VERSION "HNNBNNNYNNNNNNNNNNNNNNNNNNNNNNNNNNNNNNNNNN/4/%%%/4/'%**4NNN///"

NS_ :

BS_:

BU_: BAP_Tester CGS Gateway Gateway_PAG HUD Kombi Kombi_LB Kombi_PAG Waehlhebel_SB

BO_ 379 FCU_02: 8 Gateway
 SG_ FCU_02_CRC : 0|8@1+ (1,0) [0|255] ""  Vector__XXX
 SG_ FCU_02_BZ : 8|4@1+ (1,0) [0|15] ""  Vector__XXX
 SG_ FCU_Warn_H2_Konzentrat_Motorraum : 12|3@1+ (1.0,0.0) [0.0|7] ""  Kombi
 SG_ FCU_nicht_verfuegbar : 15|1@1+ (1.0,0.0) [0.0|1] ""  Vector__XXX
 SG_ FCU_Startstopp_Anforderung : 16|4@1+ (1.0,0.0) [0.0|15] ""  Vector__XXX
 SG_ FCU_HV_Anf : 20|2@1+ (1.0,0.0) [0.0|3] ""  Vector__XXX
 SG_ FCU_Klima_Eingr : 22|2@1+ (1.0,0.0) [0.0|3] ""  Vector__XXX
 SG_ FCU_IstModus : 24|5@1+ (1.0,0.0) [0.0|31] ""  Vector__XXX
 SG_ FCU_Status_Spgfreiheit : 29|2@1+ (1.0,0.0) [0.0|3] ""  Vector__XXX
 SG_ FCU_Fehler_Leistungsreduzierung : 31|1@1+ (1.0,0.0) [0.0|1] ""  Vector__XXX
 SG_ FCU_Fehler_Abschaltanforderung : 32|1@1+ (1.0,0.0) [0.0|1] ""  Vector__XXX
 SG_ FCU_Fehler_Notabschaltung : 33|1@1+ (1.0,0.0) [0.0|1] ""  Vector__XXX
 SG_ FCU_Fehler_Entladung_defekt : 34|2@1+ (1.0,0.0) [0.0|3] ""  Vector__XXX
 SG_ FCU_Fehler_Isofehler_I : 36|2@1+ (1.0,0.0) [0.0|3] ""  Vector__XXX
 SG_ FCU_Fehler_Isofehler_II : 38|2@1+ (1.0,0.0) [0.0|3] ""  Vector__XXX
 SG_ FCU_OBD_Lampe_Anf : 40|1@1+ (1.0,0.0) [0.0|1] ""  Vector__XXX
 SG_ FCU_Absperrventil_schliessen : 41|2@1+ (1.0,0.0) [0.0|3] ""  Vector__XXX
 SG_ FCU_TK_Betankung_Anforderung : 43|1@1+ (1.0,0.0) [0.0|1] ""  Vector__XXX
 SG_ FCU_MinAbs_Leistung : 44|10@1+ (0.1,-50) [-50.0|52.2] "Unit_KiloWatt"  Vector__XXX
 SG_ FCU_Ionenspuelung_aktiv : 54|2@1+ (1.0,0.0) [0.0|3] ""  Vector__XXX
 SG_ FCU_TK_Freigabe_Tankklappe : 56|4@1+ (1.0,0.0) [0.0|15] ""  Vector__XXX

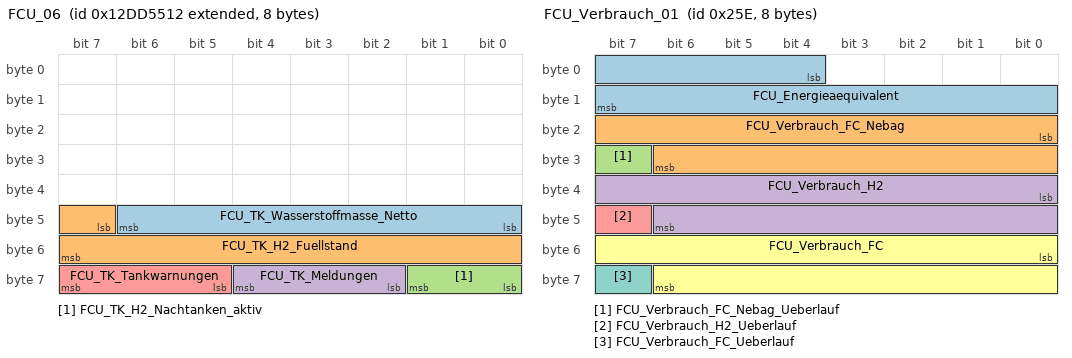
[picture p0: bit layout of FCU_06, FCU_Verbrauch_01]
BO_ 2463978770 FCU_06: 8 Gateway
 SG_ FCU_TK_Wasserstoffmasse_Netto : 40|7@1+ (0.1,0) [0.0|12.7] "Unit_KiloGram"  Kombi
 SG_ FCU_TK_H2_Fuellstand : 47|9@1+ (0.25,0) [0.00|127.25] "Unit_PerCent"  Kombi
 SG_ FCU_TK_H2_Nachtanken_aktiv : 56|2@1+ (1.0,0.0) [0.0|3] ""  Kombi
 SG_ FCU_TK_Meldungen : 58|3@1+ (1.0,0.0) [0.0|7] ""  Kombi
 SG_ FCU_TK_Tankwarnungen : 61|3@1+ (1.0,0.0) [0.0|7] ""  Kombi

BO_ 606 FCU_Verbrauch_01: 8 Gateway
 SG_ FCU_Energieaequivalent : 4|12@1+ (30,0) [0|122820] "Unit_WattSeconPerGram"  Vector__XXX
 SG_ FCU_Verbrauch_FC_Nebag : 16|15@1+ (1,0) [0|32767] "Unit_WattSecond"  Kombi
 SG_ FCU_Verbrauch_FC_Nebag_Ueberlauf : 31|1@1+ (1.0,0.0) [0.0|1] ""  Kombi
 SG_ FCU_Verbrauch_H2 : 32|15@1+ (0.1,0) [0.0|3276.7] "Unit_MilliGram"  Kombi
 SG_ FCU_Verbrauch_H2_Ueberlauf : 47|1@1+ (1.0,0.0) [0.0|1] ""  Kombi
 SG_ FCU_Verbrauch_FC : 48|15@1+ (1,0) [0|32767] "Unit_WattSecond"  Kombi
 SG_ FCU_Verbrauch_FC_Ueberlauf : 63|1@1+ (1.0,0.0) [0.0|1] ""  Kombi

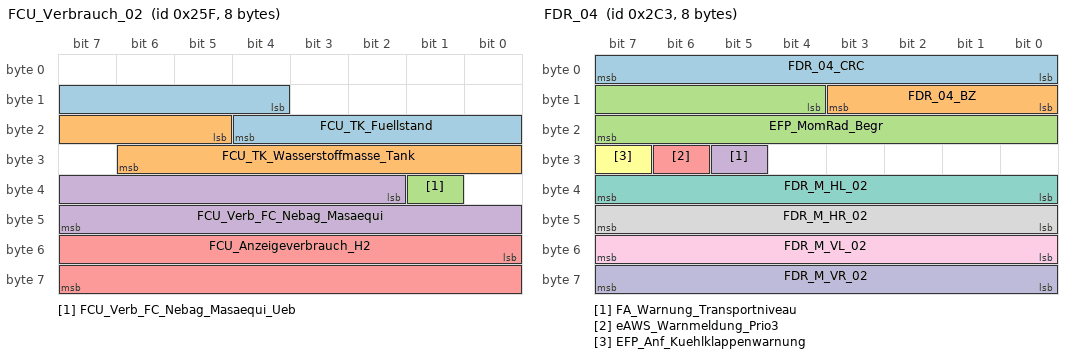
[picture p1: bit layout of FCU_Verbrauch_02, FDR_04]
BO_ 607 FCU_Verbrauch_02: 8 Gateway
 SG_ FCU_TK_Fuellstand : 12|9@1+ (0.25,0) [0.00|127.25] "Unit_PerCent"  Kombi
 SG_ FCU_TK_Wasserstoffmasse_Tank : 21|10@1+ (0.01,0) [0.00|10.21] "Unit_KiloGram"  Vector__XXX
 SG_ FCU_Verb_FC_Nebag_Masaequi_Ueb : 33|1@1+ (1.0,0.0) [0.0|1] ""  Kombi
 SG_ FCU_Verb_FC_Nebag_Masaequi : 34|14@1+ (0.1,0) [0.0|1638.3] "Unit_MilliGram"  Kombi
 SG_ FCU_Anzeigeverbrauch_H2 : 48|16@1+ (0.0005,0) [0.0000|32.7675] "Unit_KiloGramPerHour"  Kombi

BO_ 707 FDR_04: 8 Gateway
 SG_ FDR_04_CRC : 0|8@1+ (1,0) [0|255] ""  Kombi_LB,Kombi_PAG
 SG_ FDR_04_BZ : 8|4@1+ (1,0) [0|15] ""  Kombi_LB,Kombi_PAG
 SG_ EFP_MomRad_Begr : 12|12@1+ (3,0) [0|12279] "Unit_NewtoMeter"  Vector__XXX
 SG_ FA_Warnung_Transportniveau : 29|1@1+ (1.0,0.0) [0.0|1] ""  Kombi,Kombi_LB,Kombi_PAG
 SG_ eAWS_Warnmeldung_Prio3 : 30|1@1+ (1.0,0.0) [0.0|1] ""  Kombi_PAG
 SG_ EFP_Anf_Kuehlklappenwarnung : 31|1@1+ (1.0,0.0) [0.0|1] ""  Kombi,Kombi_LB,Kombi_PAG
 SG_ FDR_M_HL_02 : 32|8@1+ (1,-100) [-100|100] "Unit_PerCent"  Kombi,Kombi_LB,Kombi_PAG
 SG_ FDR_M_HR_02 : 40|8@1+ (1,-100) [-100|100] "Unit_PerCent"  Kombi,Kombi_LB,Kombi_PAG
 SG_ FDR_M_VL_02 : 48|8@1+ (1,-100) [-100|100] "Unit_PerCent"  Kombi,Kombi_LB,Kombi_PAG
 SG_ FDR_M_VR_02 : 56|8@1+ (1,-100) [-100|100] "Unit_PerCent"  Kombi,Kombi_LB,Kombi_PAG

BO_ 2589283684 FoD_01: 8 Gateway
 SG_ FoD_Transmission_Info : 60|2@1+ (1.0,0.0) [0.0|3] ""  Kombi,Kombi_LB
 SG_ FoD_Anz_Funktionsabschaltung : 62|2@1+ (1.0,0.0) [0.0|3] ""  Kombi,Kombi_LB

BO_ 2549875476 FoD_Kombi_Req: 8 Gateway
 SG_ FoD_Kombi_Req_Data : 0|64@1+ (1.0,0.0) [0.0|18446744073709551615] ""  Kombi,Kombi_LB,Kombi_PAG

BO_ 2550006548 FoD_Kombi_Resp: 8 Kombi
 SG_ FoD_Kombi_Resp_Data : 0|64@1+ (1.0,0.0) [0.0|18446744073709551615] ""  Gateway,Gateway_PAG

BO_ 2463978599 FZ_01: 8 Gateway
 SG_ MKE_Anpassung_FZ : 16|16@1+ (0.00012207,1) [1.00000000|8.99973538] "Unit_None"  Vector__XXX
 SG_ MKE_Fahrzeit : 38|10@1+ (1,0) [1|1023] "Unit_Minut"  Kombi,Kombi_LB,Kombi_PAG

BO_ 968 Getriebe_14: 8 Gateway
 SG_ GE_OBD_AbsperrVent : 12|4@1+ (1.0,0.0) [0.0|15] ""  Vector__XXX
 SG_ GE_amax_moeglich : 16|9@1+ (0.024,-2.016) [-2.016|10.224] "Unit_MeterPerSeconSquar"  Vector__XXX
 SG_ GE_Charisma_FahrPr : 25|4@1+ (1.0,0.0) [0.0|15] ""  Vector__XXX
 SG_ GE_Charisma_Status : 29|2@1+ (1.0,0.0) [0.0|3] ""  Vector__XXX
 SG_ GE_Freigabe_Verfallsinfo_WFS : 31|1@1+ (1.0,0.0) [0.0|1] ""  Vector__XXX
 SG_ GE_LaunchControl_LB : 32|4@1+ (1.0,0.0) [0.0|15] ""  Kombi_LB,Kombi_PAG
 SG_ GE_Status_PaddleNeutral : 37|2@1+ (1.0,0.0) [0.0|3] ""  Kombi,Kombi_PAG
 SG_ GE_Remotestart_Betrieb : 39|1@1+ (1.0,0.0) [0.0|1] ""  Vector__XXX
 SG_ Freilauf_Charisma_FahrPr : 40|4@1+ (1.0,0.0) [0.0|15] ""  Vector__XXX
 SG_ Freilauf_Charisma_Status : 44|2@1+ (1.0,0.0) [0.0|3] ""  Vector__XXX
 SG_ GE_Freigabe_Info_WFS : 46|1@1+ (1.0,0.0) [0.0|1] ""  Vector__XXX
 SG_ GE_Sperr_Info_WFS : 47|1@1+ (1.0,0.0) [0.0|1] ""  Vector__XXX
 SG_ GE_Zustand_Kuppltemp : 48|2@1+ (1.0,0.0) [0.0|3] ""  Vector__XXX
 SG_ GE_Codierung_MSG : 50|1@1+ (1.0,0.0) [0.0|1] ""  Vector__XXX
 SG_ GE_LaunchControl : 51|1@1+ (1.0,0.0) [0.0|1] ""  Vector__XXX
 SG_ GE_Heizwunsch : 52|2@1+ (1.0,0.0) [0.0|3] ""  Vector__XXX
 SG_ GE_OBD_Status : 54|1@1+ (1.0,0.0) [0.0|1] ""  Vector__XXX
 SG_ GE_LFR_Adaption : 55|1@1+ (1.0,0.0) [0.0|1] ""  Vector__XXX
 SG_ GE_Sumpftemperatur : 56|8@1+ (1,-58) [-58|196] "Unit_DegreCelsi"  Vector__XXX

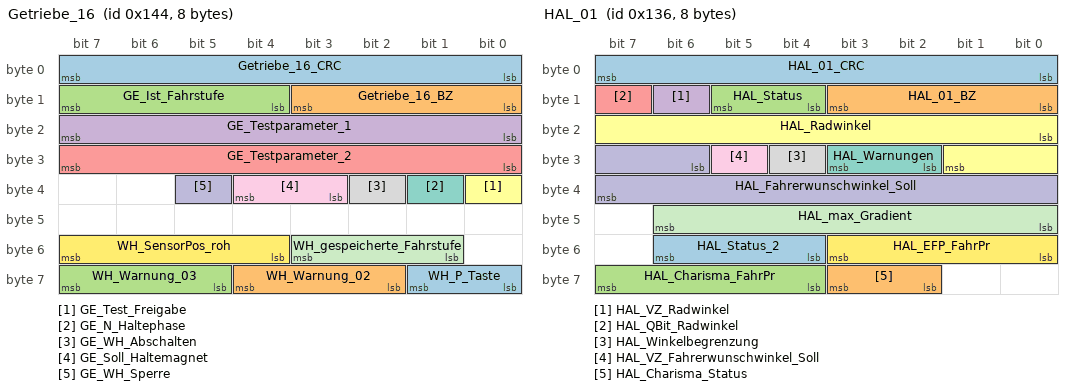
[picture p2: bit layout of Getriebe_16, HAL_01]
BO_ 324 Getriebe_16: 8 Gateway
 SG_ Getriebe_16_CRC : 0|8@1+ (1,0) [0|255] ""  CGS,Waehlhebel_SB
 SG_ Getriebe_16_BZ : 8|4@1+ (1,0) [0|15] ""  CGS,Waehlhebel_SB
 SG_ GE_Ist_Fahrstufe : 12|4@1+ (1.0,0.0) [0.0|15] ""  CGS,Waehlhebel_SB
 SG_ GE_Testparameter_1 : 16|8@1+ (1,0) [0|255] ""  CGS,Waehlhebel_SB
 SG_ GE_Testparameter_2 : 24|8@1+ (1,0) [0|255] ""  CGS,Waehlhebel_SB
 SG_ GE_Test_Freigabe : 32|1@1+ (1.0,0.0) [0.0|1] ""  CGS,Waehlhebel_SB
 SG_ GE_N_Haltephase : 33|1@1+ (1.0,0.0) [0.0|1] ""  CGS,Waehlhebel_SB
 SG_ GE_WH_Abschalten : 34|1@1+ (1.0,0.0) [0.0|1] ""  CGS,Waehlhebel_SB
 SG_ GE_Soll_Haltemagnet : 35|2@1+ (1.0,0.0) [0.0|3] ""  CGS,Waehlhebel_SB
 SG_ GE_WH_Sperre : 37|1@1+ (1.0,0.0) [0.0|1] ""  CGS,Waehlhebel_SB
 SG_ WH_gespeicherte_Fahrstufe : 49|3@1+ (1.0,0.0) [0.0|7] ""  Kombi_LB
 SG_ WH_SensorPos_roh : 52|4@1+ (1.0,0.0) [0.0|15] ""  Kombi_LB
 SG_ WH_P_Taste : 56|2@1+ (1.0,0.0) [0.0|3] ""  Kombi_LB
 SG_ WH_Warnung_02 : 58|3@1+ (1.0,0.0) [0.0|7] ""  Kombi_LB
 SG_ WH_Warnung_03 : 61|3@1+ (1.0,0.0) [0.0|7] ""  Kombi_LB

BO_ 299 GRA_ACC_01: 8 Gateway
 SG_ GRA_ACC_01_CRC : 0|8@1+ (1,0) [0|255] ""  Vector__XXX
 SG_ GRA_ACC_01_BZ : 8|4@1+ (1,0) [0|15] ""  Vector__XXX
 SG_ GRA_Hauptschalter : 12|1@1+ (1.0,0.0) [0.0|1] ""  Kombi,Kombi_LB,Kombi_PAG
 SG_ GRA_Abbrechen : 13|1@1+ (1.0,0.0) [0.0|1] ""  Vector__XXX
 SG_ GRA_Typ_Hauptschalter : 14|1@1+ (1.0,0.0) [0.0|1] ""  Vector__XXX
 SG_ GRA_Limiter : 15|1@1+ (1.0,0.0) [0.0|1] ""  Kombi,Kombi_LB,Kombi_PAG
 SG_ GRA_Tip_Setzen : 16|1@1+ (1.0,0.0) [0.0|1] ""  Vector__XXX
 SG_ GRA_Tip_Hoch : 17|1@1+ (1.0,0.0) [0.0|1] ""  Vector__XXX
 SG_ GRA_Tip_Runter : 18|1@1+ (1.0,0.0) [0.0|1] ""  Vector__XXX
 SG_ GRA_Tip_Wiederaufnahme : 19|1@1+ (1.0,0.0) [0.0|1] ""  Vector__XXX
 SG_ GRA_Verstellung_Zeitluecke : 20|2@1+ (1.0,0.0) [0.0|3] ""  Vector__XXX
 SG_ GRA_Codierung : 22|2@1+ (1.0,0.0) [0.0|3] ""  Vector__XXX
 SG_ GRA_Fehler : 24|1@1+ (1.0,0.0) [0.0|1] ""  Vector__XXX
 SG_ GRA_LIM_Taste_verfuegbar : 25|1@1+ (1.0,0.0) [0.0|1] ""  Vector__XXX
 SG_ GRA_Tip_Stufe_2 : 26|1@1+ (1.0,0.0) [0.0|1] ""  Vector__XXX
 SG_ GRA_Typ_Bedienteil : 27|3@1+ (1.0,0.0) [0.0|7] ""  Vector__XXX
 SG_ GRA_TravelAssist : 30|1@1+ (1.0,0.0) [0.0|1] ""  Vector__XXX
 SG_ GRA_reserveByte4 : 31|1@1+ (1.0,0.0) [0.0|1] ""  Vector__XXX
 SG_ GRA_reserveByte5 : 32|8@1+ (1.0,0.0) [0.0|255] ""  Vector__XXX
 SG_ GRA_reserveByte6 : 40|8@1+ (1.0,0.0) [0.0|255] ""  Vector__XXX
 SG_ GRA_reserveByte7 : 48|8@1+ (1.0,0.0) [0.0|255] ""  Vector__XXX
 SG_ GRA_reserveByte8 : 56|8@1+ (1.0,0.0) [0.0|255] ""  Vector__XXX

BO_ 310 HAL_01: 8 Gateway
 SG_ HAL_01_CRC : 0|8@1+ (1,0) [0|255] ""  Kombi,Kombi_LB,Kombi_PAG
 SG_ HAL_01_BZ : 8|4@1+ (1,0) [0|15] ""  Kombi,Kombi_LB,Kombi_PAG
 SG_ HAL_Status : 12|2@1+ (1.0,0.0) [0.0|3] ""  Vector__XXX
 SG_ HAL_VZ_Radwinkel : 14|1@1+ (1.0,0.0) [0.0|1] ""  Kombi_LB
 SG_ HAL_QBit_Radwinkel : 15|1@1+ (1.0,0.0) [0.0|1] ""  Vector__XXX
 SG_ HAL_Radwinkel : 16|10@1+ (0.01,0) [0.00|10.19] "Unit_DegreOfArc"  Kombi_LB
 SG_ HAL_Warnungen : 26|2@1+ (1.0,0.0) [0.0|3] ""  Kombi,Kombi_LB,Kombi_PAG
 SG_ HAL_Winkelbegrenzung : 28|1@1+ (1.0,0.0) [0.0|1] ""  Vector__XXX
 SG_ HAL_VZ_Fahrerwunschwinkel_Soll : 29|1@1+ (1.0,0.0) [0.0|1] ""  Vector__XXX
 SG_ HAL_Fahrerwunschwinkel_Soll : 30|10@1+ (0.01,0) [0.00|10.21] "Unit_DegreOfArc"  Vector__XXX
 SG_ HAL_max_Gradient : 40|7@1+ (0.1,0) [0.0|12.5] "Unit_DegreOfArcPerSecon"  Vector__XXX
 SG_ HAL_EFP_FahrPr : 48|4@1+ (1.0,0.0) [0.0|15] ""  Vector__XXX
 SG_ HAL_Status_2 : 52|3@1+ (1.0,0.0) [0.0|7] ""  Kombi_LB
 SG_ HAL_Charisma_Status : 58|2@1+ (1.0,0.0) [0.0|3] ""  Vector__XXX
 SG_ HAL_Charisma_FahrPr : 60|4@1+ (1.0,0.0) [0.0|15] ""  Vector__XXX

BO_ 1412 HSP_01: 6 Gateway
 SG_ HSP_01_CRC : 0|8@1+ (1,0) [0|255] ""  Kombi
 SG_ HSP_01_BZ : 8|4@1+ (1,0) [0|15] ""  Kombi
 SG_ HSP_Taster : 12|1@1+ (1.0,0.0) [0.0|1] ""  Vector__XXX
 SG_ HSP_Status_LED : 13|1@1+ (1.0,0.0) [0.0|1] ""  Vector__XXX
 SG_ HSP_Warnung_LED : 14|1@1+ (1.0,0.0) [0.0|1] ""  Kombi
 SG_ HSP_Warnung_Ton : 15|1@1+ (1.0,0.0) [0.0|1] ""  Vector__XXX
 SG_ HSP_Warnung_Text : 16|1@1+ (1.0,0.0) [0.0|1] ""  Kombi
 SG_ HSP_Endlage_eingefahren : 17|1@1+ (1.0,0.0) [0.0|1] ""  Vector__XXX
 SG_ HSP_Endlage_ausgefahren : 18|1@1+ (1.0,0.0) [0.0|1] ""  Vector__XXX
 SG_ HSP_Unterspannung : 19|1@1+ (1.0,0.0) [0.0|1] ""  Vector__XXX
 SG_ HSP_Ueberspannung : 20|1@1+ (1.0,0.0) [0.0|1] ""  Vector__XXX
 SG_ HSP_Lokalaktiv : 21|1@1+ (1.0,0.0) [0.0|1] ""  Vector__XXX
 SG_ HSP_ResponseError : 22|1@1+ (1.0,0.0) [0.0|1] ""  Vector__XXX
 SG_ HSP_ErrorGueltigkeit_1 : 23|1@1+ (1.0,0.0) [0.0|1] ""  Vector__XXX
 SG_ HSP_ErrorGueltigkeit_2 : 24|1@1+ (1.0,0.0) [0.0|1] ""  Vector__XXX
 SG_ HSP_def : 25|1@1+ (1.0,0.0) [0.0|1] ""  Vector__XXX
 SG_ HSP_Motor_def : 26|1@1+ (1.0,0.0) [0.0|1] ""  Vector__XXX
 SG_ HSP_Spoiler_Error : 27|1@1+ (1.0,0.0) [0.0|1] ""  Vector__XXX
 SG_ HSP_Taster_Error : 28|1@1+ (1.0,0.0) [0.0|1] ""  Vector__XXX
 SG_ HSP_LED_Error : 29|1@1+ (1.0,0.0) [0.0|1] ""  Vector__XXX
 SG_ HSP_Spielschutz : 30|1@1+ (1.0,0.0) [0.0|1] ""  Vector__XXX
 SG_ HSP_Motor_Temp_Text : 31|1@1+ (1.0,0.0) [0.0|1] ""  Vector__XXX
 SG_ HSP_Charisma_FahrPr : 32|4@1+ (1.0,0.0) [0.0|15] ""  Vector__XXX
 SG_ HSP_Charisma_Status : 36|2@1+ (1.0,0.0) [0.0|3] ""  Vector__XXX
 SG_ HSP_man_Betaet_nicht_zulaessig : 38|1@1+ (1.0,0.0) [0.0|1] ""  Vector__XXX
 SG_ HSP_Komponentensteuerung : 39|1@1+ (1.0,0.0) [0.0|1] ""  Vector__XXX
 SG_ HSP_BAP_Messages : 40|4@1+ (1.0,0.0) [0.0|15] ""  Vector__XXX

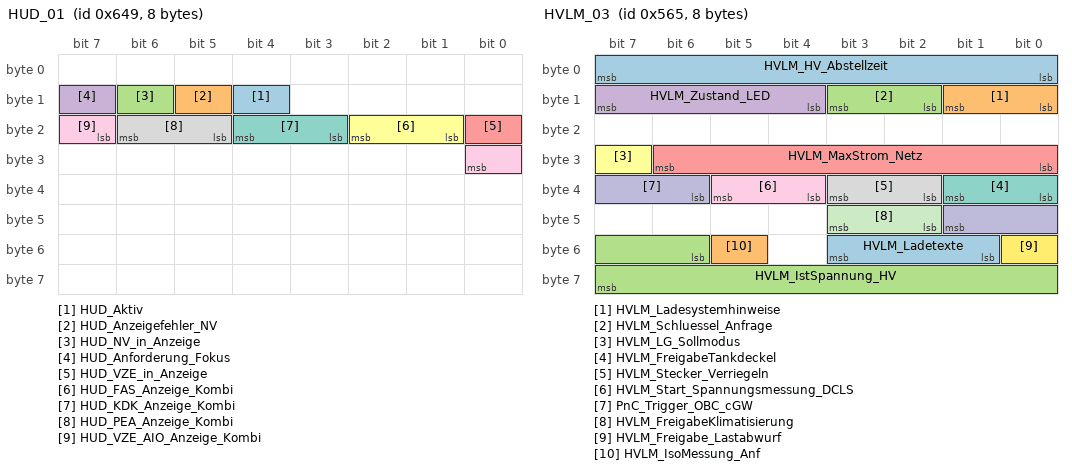
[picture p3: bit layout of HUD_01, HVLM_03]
BO_ 1609 HUD_01: 8 HUD
 SG_ HUD_Aktiv : 12|1@1+ (1.0,0.0) [0.0|1] ""  Kombi,Kombi_PAG
 SG_ HUD_Anzeigefehler_NV : 13|1@1+ (1.0,0.0) [0.0|1] ""  Vector__XXX
 SG_ HUD_NV_in_Anzeige : 14|1@1+ (1.0,0.0) [0.0|1] ""  Vector__XXX
 SG_ HUD_Anforderung_Fokus : 15|1@1+ (1.0,0.0) [0.0|1] ""  Kombi_PAG
 SG_ HUD_VZE_in_Anzeige : 16|1@1+ (1.0,0.0) [0.0|1] ""  Vector__XXX
 SG_ HUD_FAS_Anzeige_Kombi : 17|2@1+ (1.0,0.0) [0.0|3] ""  Vector__XXX
 SG_ HUD_KDK_Anzeige_Kombi : 19|2@1+ (1.0,0.0) [0.0|3] ""  Vector__XXX
 SG_ HUD_PEA_Anzeige_Kombi : 21|2@1+ (1.0,0.0) [0.0|3] ""  Vector__XXX
 SG_ HUD_VZE_AIO_Anzeige_Kombi : 23|2@1+ (1.0,0.0) [0.0|3] ""  Vector__XXX

BO_ 1283 HVK_01: 8 Gateway
 SG_ HVK_01_CRC : 0|8@1+ (1,0) [0|255] ""  Kombi,Kombi_LB,Kombi_PAG
 SG_ HVK_01_BZ : 8|4@1+ (1,0) [0|15] ""  Kombi,Kombi_LB,Kombi_PAG
 SG_ HVK_Istmodus_Anf : 12|1@1+ (1.0,0.0) [0.0|1] ""  Vector__XXX
 SG_ HVK_TN1_Sollmodus : 13|2@1+ (1.0,0.0) [0.0|3] ""  Vector__XXX
 SG_ HVK_MO_EmSollzustand : 16|8@1+ (1.0,0.0) [0.0|255] ""  Vector__XXX
 SG_ HVK_BMS_Sollmodus : 24|3@1+ (1.0,0.0) [0.0|7] ""  Vector__XXX
 SG_ HVK_DCDC_Sollmodus : 27|3@1+ (1.0,0.0) [0.0|7] ""  Vector__XXX
 SG_ HVK_EKK_Sollmodus : 30|3@1+ (1.0,0.0) [0.0|7] ""  Vector__XXX
 SG_ HVK_HVPTC_Sollmodus : 33|3@1+ (1.0,0.0) [0.0|7] ""  Vector__XXX
 SG_ HVK_HVLM_Sollmodus : 36|3@1+ (1.0,0.0) [0.0|7] ""  Vector__XXX
 SG_ HVK_HV_Netz_Warnungen : 39|2@1+ (1.0,0.0) [0.0|3] ""  Kombi,Kombi_LB,Kombi_PAG
 SG_ HV_Bordnetz_aktiv : 41|1@1+ (1.0,0.0) [0.0|1] ""  Vector__XXX
 SG_ HV_Bordnetz_Fehler : 42|1@1+ (1.0,0.0) [0.0|1] ""  Vector__XXX
 SG_ HVK_Gesamtst_Spgfreiheit : 43|2@1+ (1.0,0.0) [0.0|3] ""  Kombi,Kombi_LB,Kombi_PAG
 SG_ HVK_AktiveEntladung_Anf : 45|1@1+ (1.0,0.0) [0.0|1] ""  Vector__XXX
 SG_ HVK_Iso_Fehlerstatus : 48|1@1+ (1.0,0.0) [0.0|1] ""  Kombi,Kombi_PAG
 SG_ HVK_Iso_Messung_Start : 50|3@1+ (1.0,0.0) [0.0|7] ""  Vector__XXX
 SG_ HVK_AIAD_Sollmodus_2 M  : 53|1@1+ (1.0,0.0) [0.0|1] ""  Vector__XXX
 SG_ HVK_DCDC_EKK_Sollmodus : 62|2@1+ (1.0,0.0) [0.0|3] ""  Vector__XXX

BO_ 1381 HVLM_03: 8 Gateway
 SG_ HVLM_HV_Abstellzeit : 0|8@1+ (4,0) [0|1012] "Unit_Minut"  Vector__XXX
 SG_ HVLM_Ladesystemhinweise : 8|2@1+ (1.0,0.0) [0.0|3] ""  Kombi,Kombi_LB,Kombi_PAG
 SG_ HVLM_Schluessel_Anfrage : 10|2@1+ (1.0,0.0) [0.0|3] ""  Vector__XXX
 SG_ HVLM_Zustand_LED : 12|4@1+ (1.0,0.0) [0.0|15] ""  Kombi,Kombi_LB,Kombi_PAG
 SG_ HVLM_MaxStrom_Netz : 24|7@1+ (0.5,0) [0.0|62.5] "Unit_Amper"  Vector__XXX
 SG_ HVLM_LG_Sollmodus : 31|1@1+ (1.0,0.0) [0.0|1] ""  Vector__XXX
 SG_ HVLM_FreigabeTankdeckel : 32|2@1+ (1.0,0.0) [0.0|3] ""  Vector__XXX
 SG_ HVLM_Stecker_Verriegeln : 34|2@1+ (1.0,0.0) [0.0|3] ""  Vector__XXX
 SG_ HVLM_Start_Spannungsmessung_DCLS : 36|2@1+ (1.0,0.0) [0.0|3] ""  Vector__XXX
 SG_ PnC_Trigger_OBC_cGW : 38|4@1+ (1.0,0.0) [0.0|15] ""  Vector__XXX
 SG_ HVLM_FreigabeKlimatisierung : 42|2@1+ (1.0,0.0) [0.0|3] ""  Vector__XXX
 SG_ HVLM_Freigabe_Lastabwurf : 48|1@1+ (1.0,0.0) [0.0|1] ""  Vector__XXX
 SG_ HVLM_Ladetexte : 49|3@1+ (1.0,0.0) [0.0|7] ""  Kombi,Kombi_LB,Kombi_PAG
 SG_ HVLM_IsoMessung_Anf : 53|1@1+ (1.0,0.0) [0.0|1] ""  Vector__XXX
 SG_ HVLM_IstSpannung_HV : 54|10@1+ (1,0) [0|1021] "Unit_Volt"  Vector__XXX

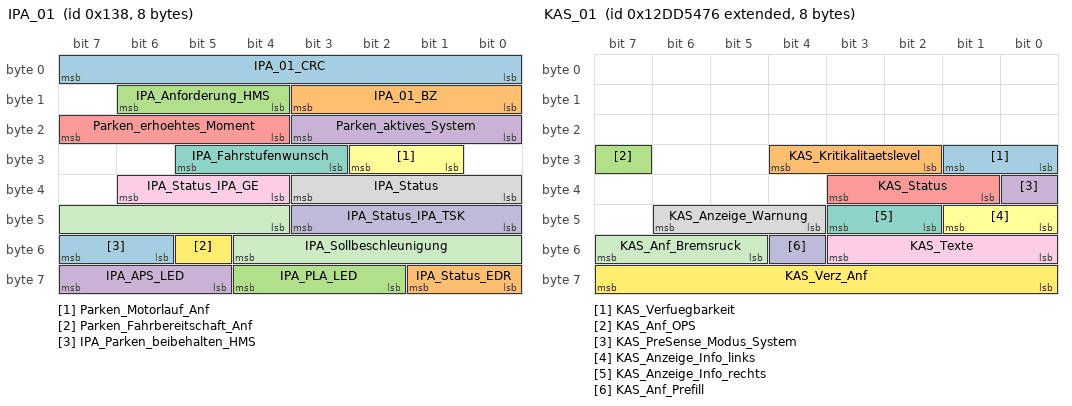
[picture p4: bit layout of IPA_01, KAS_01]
BO_ 312 IPA_01: 8 Gateway
 SG_ IPA_01_CRC : 0|8@1+ (1,0) [0|255] ""  Vector__XXX
 SG_ IPA_01_BZ : 8|4@1+ (1,0) [0|15] ""  Vector__XXX
 SG_ IPA_Anforderung_HMS : 12|3@1+ (1.0,0.0) [0.0|7] ""  Vector__XXX
 SG_ Parken_aktives_System : 16|4@1+ (1.0,0.0) [0.0|15] ""  Vector__XXX
 SG_ Parken_erhoehtes_Moment : 20|4@1+ (1.0,0.0) [0.0|15] ""  Vector__XXX
 SG_ Parken_Motorlauf_Anf : 25|2@1+ (1.0,0.0) [0.0|3] ""  Vector__XXX
 SG_ IPA_Fahrstufenwunsch : 27|3@1+ (1.0,0.0) [0.0|7] ""  Vector__XXX
 SG_ IPA_Status : 32|4@1+ (1.0,0.0) [0.0|15] ""  Vector__XXX
 SG_ IPA_Status_IPA_GE : 36|3@1+ (1.0,0.0) [0.0|7] ""  Vector__XXX
 SG_ IPA_Status_IPA_TSK : 40|4@1+ (1.0,0.0) [0.0|15] ""  Vector__XXX
 SG_ IPA_Sollbeschleunigung : 44|9@1+ (0.01,-4.11) [-4.10|1.00] "Unit_MeterPerSeconSquar"  Vector__XXX
 SG_ Parken_Fahrbereitschaft_Anf : 53|1@1+ (1.0,0.0) [0.0|1] ""  Kombi,Kombi_LB,Kombi_PAG
 SG_ IPA_Parken_beibehalten_HMS : 54|2@1+ (1.0,0.0) [0.0|3] ""  Vector__XXX
 SG_ IPA_Status_EDR : 56|2@1+ (1.0,0.0) [0.0|3] ""  Vector__XXX
 SG_ IPA_PLA_LED : 58|3@1+ (1.0,0.0) [0.0|7] ""  Vector__XXX
 SG_ IPA_APS_LED : 61|3@1+ (1.0,0.0) [0.0|7] ""  Vector__XXX

BO_ 1792 ISO_Funktionaler_Req_All: 8 Gateway
 SG_ ISO_ALL_01_Req_Data : 0|64@1+ (1.0,0.0) [0.0|18446744073709551615] ""  CGS,HUD,Kombi,Kombi_LB,Kombi_PAG,Waehlhebel_SB

BO_ 1819 ISO_HUD_Req: 8 Gateway
 SG_ ISO_HUD_Req_Data : 0|64@1+ (1.0,0.0) [0.0|18446744073709551615] ""  HUD

BO_ 1925 ISO_HUD_Resp: 8 HUD
 SG_ ISO_HUD_Resp_Data : 0|64@1+ (1.0,0.0) [0.0|18446744073709551615] ""  Gateway,Gateway_PAG

BO_ 1812 ISO_Kombi_Req: 8 Gateway
 SG_ ISO_Kombi_Req_Data : 0|64@1+ (1.0,0.0) [0.0|18446744073709551615] ""  Kombi,Kombi_LB,Kombi_PAG

BO_ 1918 ISO_Kombi_Resp: 8 Kombi
 SG_ ISO_Kombi_Resp_Data : 0|64@1+ (1.0,0.0) [0.0|18446744073709551615] ""  Gateway,Gateway_PAG

BO_ 1875 ISO_Waehlhebel_Req: 8 Gateway
 SG_ ISO_Waehlhebel_Req_Data : 0|64@1+ (1.0,0.0) [0.0|18446744073709551615] ""  CGS,Waehlhebel_SB

BO_ 1981 ISO_Waehlhebel_Resp: 8 CGS
 SG_ ISO_Waehlhebel_Resp_Data : 0|64@1+ (1.0,0.0) [0.0|18446744073709551615] ""  Gateway,Gateway_PAG

BO_ 2463978614 KAS_01: 8 Gateway
 SG_ KAS_Verfuegbarkeit : 24|2@1+ (1.0,0.0) [0.0|3] ""  Vector__XXX
 SG_ KAS_Kritikalitaetslevel : 26|3@1+ (1.0,0.0) [0.0|7] ""  Vector__XXX
 SG_ KAS_Anf_OPS : 31|1@1+ (1.0,0.0) [0.0|1] ""  Vector__XXX
 SG_ KAS_PreSense_Modus_System : 32|1@1+ (1.0,0.0) [0.0|1] ""  Vector__XXX
 SG_ KAS_Status : 33|3@1+ (1.0,0.0) [0.0|7] ""  HUD,Kombi,Kombi_LB,Kombi_PAG
 SG_ KAS_Anzeige_Info_links : 40|2@1+ (1.0,0.0) [0.0|3] ""  HUD,Kombi,Kombi_LB,Kombi_PAG
 SG_ KAS_Anzeige_Info_rechts : 42|2@1+ (1.0,0.0) [0.0|3] ""  HUD,Kombi,Kombi_LB,Kombi_PAG
 SG_ KAS_Anzeige_Warnung : 44|3@1+ (1.0,0.0) [0.0|7] ""  HUD,Kombi,Kombi_LB,Kombi_PAG
 SG_ KAS_Texte : 48|4@1+ (1.0,0.0) [0.0|15] ""  Kombi,Kombi_LB,Kombi_PAG
 SG_ KAS_Anf_Prefill : 52|1@1+ (1.0,0.0) [0.0|1] ""  Vector__XXX
 SG_ KAS_Anf_Bremsruck : 53|3@1+ (1.0,0.0) [0.0|7] ""  Vector__XXX
 SG_ KAS_Verz_Anf : 56|8@1+ (0.079,-19.987) [-19.987|0.000] "Unit_MeterPerSeconSquar"  Vector__XXX

BO_ 497 Kessy_11: 8 Gateway
 SG_ KY_IDG_in_Reichweite : 12|1@1+ (1.0,0.0) [0.0|1] ""  Vector__XXX
 SG_ KY_Auf_Taste : 13|1@1+ (1.0,0.0) [0.0|1] ""  Vector__XXX
 SG_ KY_HDF_Taste : 14|1@1+ (1.0,0.0) [0.0|1] ""  Vector__XXX
 SG_ KY_Panik_Taste : 15|1@1+ (1.0,0.0) [0.0|1] ""  Vector__XXX
 SG_ KY_Zu_Taste : 16|1@1+ (1.0,0.0) [0.0|1] ""  Vector__XXX
 SG_ KY_FT_Entriegelung_Autorisiert : 17|1@1+ (1.0,0.0) [0.0|1] ""  Vector__XXX
 SG_ KY_FT_Verriegelung_Autorisiert : 18|1@1+ (1.0,0.0) [0.0|1] ""  Vector__XXX
 SG_ KY_BT_Entriegelung_Autorisiert : 19|1@1+ (1.0,0.0) [0.0|1] ""  Vector__XXX
 SG_ KY_BT_Verriegelung_Autorisiert : 20|1@1+ (1.0,0.0) [0.0|1] ""  Vector__XXX
 SG_ KY_HFS_Entriegelung_Autorisiert : 21|1@1+ (1.0,0.0) [0.0|1] ""  Vector__XXX
 SG_ KY_HFS_Verriegelung_Autorisiert : 22|1@1+ (1.0,0.0) [0.0|1] ""  Vector__XXX
 SG_ KY_HBFS_Entriegelung_Autorisiert : 23|1@1+ (1.0,0.0) [0.0|1] ""  Vector__XXX
 SG_ KY_HBFS_Verriegelung_Autorisiert : 24|1@1+ (1.0,0.0) [0.0|1] ""  Vector__XXX
 SG_ KY_Front_Entr_Autorisiert : 25|1@1+ (1.0,0.0) [0.0|1] ""  Vector__XXX
 SG_ KY_Front_Verr_Autorisiert : 26|1@1+ (1.0,0.0) [0.0|1] ""  Vector__XXX
 SG_ KY_HD_Entriegelung_Autorisiert : 27|1@1+ (1.0,0.0) [0.0|1] ""  Vector__XXX
 SG_ KY_HD_Verriegelung_Autorisiert : 28|1@1+ (1.0,0.0) [0.0|1] ""  Vector__XXX
 SG_ KY_Bereich : 29|3@1+ (1.0,0.0) [0.0|7] ""  Vector__XXX
 SG_ KY_Position : 32|3@1+ (1.0,0.0) [0.0|7] ""  Vector__XXX
 SG_ KY_ZV_Signatur : 35|11@1+ (1,0) [0|2047] "Unit_None"  Vector__XXX
 SG_ Schluesselnr_Personalisierung : 46|4@1+ (1.0,0.0) [0.0|15] ""  Kombi,Kombi_LB,Kombi_PAG
 SG_ FFB_FDF_Taste : 50|1@1+ (1.0,0.0) [0.0|1] ""  Vector__XXX
 SG_ FFB_Joker_Taste : 51|1@1+ (1.0,0.0) [0.0|1] ""  Vector__XXX
 SG_ FFB_Park_Taste : 52|1@1+ (1.0,0.0) [0.0|1] ""  Vector__XXX
 SG_ FFB_Remotestart_Taste : 53|1@1+ (1.0,0.0) [0.0|1] ""  Vector__XXX
 SG_ FBS_Aktivierung_Pilot_Parken : 54|1@1+ (1.0,0.0) [0.0|1] ""  Vector__XXX
 SG_ KY_Schluessel_im_Fzg : 55|1@1+ (1.0,0.0) [0.0|1] ""  Vector__XXX
 SG_ KY_EasyClose_Abbruch : 56|1@1+ (1.0,0.0) [0.0|1] ""  Vector__XXX
 SG_ KY_EasyClose_Status : 57|3@1+ (1.0,0.0) [0.0|7] ""  Vector__XXX
 SG_ KY_HD_Auffahrt : 60|1@1+ (1.0,0.0) [0.0|1] ""  Vector__XXX
 SG_ KY_HD_Zufahrt : 61|1@1+ (1.0,0.0) [0.0|1] ""  Vector__XXX
 SG_ KY_LKL_1_Autorisierung : 62|1@1+ (1.0,0.0) [0.0|1] ""  Vector__XXX
 SG_ KY_LKL_2_Autorisierung : 63|1@1+ (1.0,0.0) [0.0|1] ""  Vector__XXX

BO_ 1424 Kessy_12: 8 Gateway
 SG_ FBS_Warn_Schluessel_Batt : 12|1@1+ (1.0,0.0) [0.0|1] ""  Kombi,Kombi_LB,Kombi_PAG
 SG_ KY_FFB_Frequenz : 13|2@1+ (1.0,0.0) [0.0|3] ""  Vector__XXX
 SG_ KY_HF_Aktiv : 15|1@1+ (1.0,0.0) [0.0|1] ""  Vector__XXX
 SG_ KY_LF_Aktiv : 16|1@1+ (1.0,0.0) [0.0|1] ""  Vector__XXX
 SG_ KY_KYL_Fahrer_Hinweise : 17|3@1+ (1.0,0.0) [0.0|7] ""  Kombi,Kombi_LB,Kombi_PAG
 SG_ KY_StartStopp_Info : 20|2@1+ (1.0,0.0) [0.0|3] ""  Vector__XXX
 SG_ KY_Keyless_Verbau : 22|1@1+ (1.0,0.0) [0.0|1] ""  Vector__XXX
 SG_ KY_Keyless_Go_Verbau : 23|1@1+ (1.0,0.0) [0.0|1] ""  Kombi,Kombi_LB,Kombi_PAG
 SG_ KY_Transponder_aktiv : 24|1@1+ (1.0,0.0) [0.0|1] ""  Vector__XXX
 SG_ KYL_Warn_kein_Schluessel : 25|1@1+ (1.0,0.0) [0.0|1] ""  Kombi,Kombi_LB,Kombi_PAG
 SG_ KYL_Warn_Kessy_defekt : 26|1@1+ (1.0,0.0) [0.0|1] ""  Kombi,Kombi_LB,Kombi_PAG
 SG_ KYL_Warn_Notzuendschloss : 27|1@1+ (1.0,0.0) [0.0|1] ""  Kombi,Kombi_LB,Kombi_PAG
 SG_ KY_Fzg_Verlassen_erkannt : 28|1@1+ (1.0,0.0) [0.0|1] ""  Vector__XXX
 SG_ KY_Fzg_Zugang_erkannt : 29|1@1+ (1.0,0.0) [0.0|1] ""  Vector__XXX
 SG_ KY_Indikator_Mehrere_Schluessel : 30|1@1+ (1.0,0.0) [0.0|1] ""  Vector__XXX
 SG_ KY_NFC_Fahrer_Hinweise : 41|3@1+ (1.0,0.0) [0.0|7] ""  Kombi,Kombi_LB,Kombi_PAG
 SG_ KST_Wegstrecke_Challenge : 44|20@1+ (1.0,0.0) [0.0|1048575] ""  Kombi,Kombi_LB,Kombi_PAG

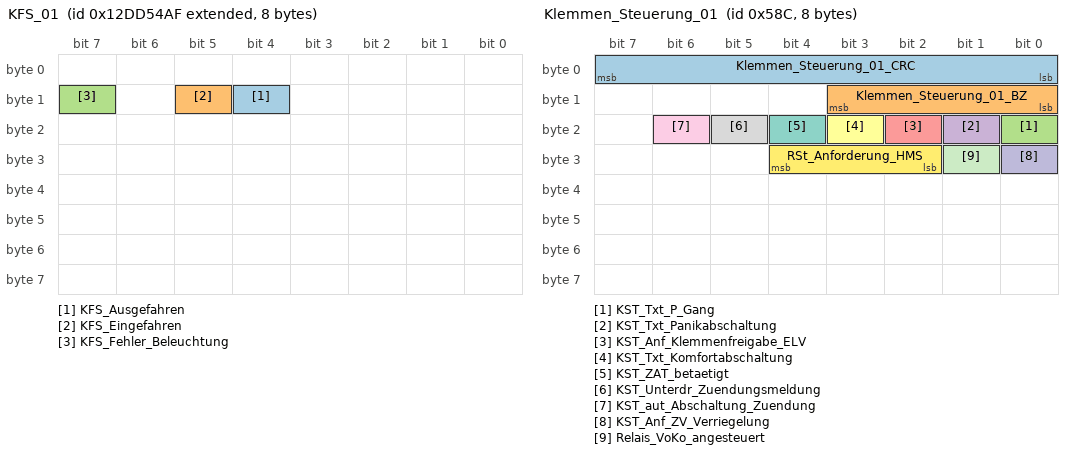
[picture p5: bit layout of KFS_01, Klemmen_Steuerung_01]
BO_ 2463978671 KFS_01: 8 Gateway
 SG_ KFS_Ausgefahren : 12|1@1+ (1.0,0.0) [0.0|1] ""  Vector__XXX
 SG_ KFS_Eingefahren : 13|1@1+ (1.0,0.0) [0.0|1] ""  Vector__XXX
 SG_ KFS_Fehler_Beleuchtung : 15|1@1+ (1.0,0.0) [0.0|1] ""  Vector__XXX

BO_ 960 Klemmen_Status_01: 4 Gateway
 SG_ Klemmen_Status_01_CRC : 0|8@1+ (1,0) [0|255] ""  CGS,Kombi,Kombi_LB,Kombi_PAG,Waehlhebel_SB
 SG_ Klemmen_Status_01_BZ : 8|4@1+ (1,0) [0|15] ""  CGS,Kombi,Kombi_LB,Kombi_PAG,Waehlhebel_SB
 SG_ RSt_Fahrerhinweise : 12|4@1+ (1.0,0.0) [0.0|15] ""  Kombi,Kombi_LB
 SG_ ZAS_Kl_S : 16|1@1+ (1.0,0.0) [0.0|1] ""  Kombi,Kombi_LB,Kombi_PAG
 SG_ ZAS_Kl_15 : 17|1@1+ (1.0,0.0) [0.0|1] ""  CGS,HUD,Kombi,Kombi_LB,Kombi_PAG,Waehlhebel_SB
 SG_ ZAS_Kl_X : 18|1@1+ (1.0,0.0) [0.0|1] ""  Vector__XXX
 SG_ ZAS_Kl_50_Startanforderung : 19|1@1+ (1.0,0.0) [0.0|1] ""  Kombi,Kombi_LB,Kombi_PAG
 SG_ BCM_Remotestart_Betrieb : 20|1@1+ (1.0,0.0) [0.0|1] ""  Vector__XXX
 SG_ ZAS_Kl_Infotainment : 21|1@1+ (1.0,0.0) [0.0|1] ""  Vector__XXX
 SG_ BCM_Remotestart_KL15_Anf : 22|1@1+ (1.0,0.0) [0.0|1] ""  Kombi,Kombi_PAG
 SG_ BCM_Remotestart_MO_Start : 23|1@1+ (1.0,0.0) [0.0|1] ""  Vector__XXX
 SG_ KST_Warn_P1_ZST_def : 24|1@1+ (1.0,0.0) [0.0|1] ""  Kombi,Kombi_LB,Kombi_PAG
 SG_ KST_Warn_P2_ZST_def : 25|1@1+ (1.0,0.0) [0.0|1] ""  Kombi,Kombi_LB,Kombi_PAG
 SG_ KST_Fahrerhinweis_1 : 26|1@1+ (1.0,0.0) [0.0|1] ""  Kombi,Kombi_LB,Kombi_PAG
 SG_ KST_Fahrerhinweis_2 : 27|1@1+ (1.0,0.0) [0.0|1] ""  Kombi,Kombi_LB,Kombi_PAG
 SG_ BCM_Ausparken_Betrieb : 28|1@1+ (1.0,0.0) [0.0|1] ""  Kombi,Kombi_LB,Kombi_PAG
 SG_ KST_Fahrerhinweis_4 : 29|1@1+ (1.0,0.0) [0.0|1] ""  Vector__XXX
 SG_ KST_Fahrerhinweis_5 : 30|1@1+ (1.0,0.0) [0.0|1] ""  Kombi,Kombi_LB,Kombi_PAG
 SG_ KST_Fahrerhinweis_6 : 31|1@1+ (1.0,0.0) [0.0|1] ""  Kombi,Kombi_LB,Kombi_PAG

BO_ 1420 Klemmen_Steuerung_01: 8 Gateway
 SG_ Klemmen_Steuerung_01_CRC : 0|8@1+ (1,0) [0|255] ""  Vector__XXX
 SG_ Klemmen_Steuerung_01_BZ : 8|4@1+ (1,0) [0|15] ""  Vector__XXX
 SG_ KST_Txt_P_Gang : 16|1@1+ (1.0,0.0) [0.0|1] ""  Kombi,Kombi_LB,Kombi_PAG
 SG_ KST_Txt_Panikabschaltung : 17|1@1+ (1.0,0.0) [0.0|1] ""  Kombi,Kombi_LB,Kombi_PAG
 SG_ KST_Anf_Klemmenfreigabe_ELV : 18|1@1+ (1.0,0.0) [0.0|1] ""  Vector__XXX
 SG_ KST_Txt_Komfortabschaltung : 19|1@1+ (1.0,0.0) [0.0|1] ""  Kombi,Kombi_LB,Kombi_PAG
 SG_ KST_ZAT_betaetigt : 20|1@1+ (1.0,0.0) [0.0|1] ""  Vector__XXX
 SG_ KST_Unterdr_Zuendungsmeldung : 21|1@1+ (1.0,0.0) [0.0|1] ""  Kombi,Kombi_LB,Kombi_PAG
 SG_ KST_aut_Abschaltung_Zuendung : 22|1@1+ (1.0,0.0) [0.0|1] ""  Kombi,Kombi_LB,Kombi_PAG
 SG_ KST_Anf_ZV_Verriegelung : 24|1@1+ (1.0,0.0) [0.0|1] ""  Vector__XXX
 SG_ Relais_VoKo_angesteuert : 25|1@1+ (1.0,0.0) [0.0|1] ""  Vector__XXX
 SG_ RSt_Anforderung_HMS : 26|3@1+ (1.0,0.0) [0.0|7] ""  Vector__XXX

BO_ 1646 Klima_03: 8 Gateway
 SG_ KL_STL_aktiv : 0|1@1+ (1.0,0.0) [0.0|1] ""  Kombi,Kombi_LB,Kombi_PAG
 SG_ KL_STH_aktiv : 1|1@1+ (1.0,0.0) [0.0|1] ""  Kombi,Kombi_PAG
 SG_ KL_Solarluefter_aktiv : 2|1@1+ (1.0,0.0) [0.0|1] ""  Vector__XXX
 SG_ KL_Umluft_Taste : 3|1@1+ (1.0,0.0) [0.0|1] ""  Kombi_PAG
 SG_ KL_Geblaese_Fond_Status : 4|4@1+ (1.0,0.0) [0.0|15] ""  Kombi,Kombi_LB,Kombi_PAG
 SG_ KL_STH_Ansteuerung : 8|2@1+ (1.0,0.0) [0.0|3] ""  Vector__XXX
 SG_ KL_STH_Betriebsdauer : 10|6@1+ (1,0) [0|60] "Unit_Minut"  Kombi,Kombi_PAG
 SG_ KL_Magnetventil : 16|1@1+ (1.0,0.0) [0.0|1] ""  Vector__XXX
 SG_ KL_WaPu : 17|1@1+ (1.0,0.0) [0.0|1] ""  Vector__XXX
 SG_ KL_Geblaese_Status : 18|4@1+ (1.0,0.0) [0.0|15] ""  Kombi,Kombi_LB,Kombi_PAG
 SG_ KL_Restwaerme_aktiv : 22|1@1+ (1.0,0.0) [0.0|1] ""  Vector__XXX
 SG_ KL_Kompressorkupplung : 23|1@1+ (1.0,0.0) [0.0|1] ""  Vector__XXX
 SG_ KL_BCmE_Livetip_Freigabe : 24|1@1+ (1.0,0.0) [0.0|1] ""  Vector__XXX
 SG_ KL_HYB_ASV_hinten_schliessen_Anf : 25|1@1+ (1.0,0.0) [0.0|1] ""  Vector__XXX
 SG_ KL_HYB_ASV_vorne_schliessen_Anf : 26|1@1+ (1.0,0.0) [0.0|1] ""  Vector__XXX
 SG_ KL_ErwVK_Zusatzrelais : 27|1@1+ (1.0,0.0) [0.0|1] ""  Vector__XXX
 SG_ KL_Status_Beduftung : 28|1@1+ (1.0,0.0) [0.0|1] ""  Vector__XXX
 SG_ KL_Status_Ionisator_Front : 29|1@1+ (1.0,0.0) [0.0|1] ""  Vector__XXX
 SG_ KL_STH_Timer_Status : 30|1@1+ (1.0,0.0) [0.0|1] ""  Kombi,Kombi_PAG
 SG_ KL_ErwVK_Anf : 31|1@1+ (1.0,0.0) [0.0|1] ""  Vector__XXX
 SG_ KL_Innen_Temp : 32|8@1+ (0.5,-50) [-50.0|76.0] "Unit_DegreCelsi"  CGS,Waehlhebel_SB
 SG_ KL_I_Geblaese_Fond : 40|8@1+ (0.25,0) [0.00|63.50] "Unit_Amper"  Vector__XXX
 SG_ KL_Anf_AussenspiegelHzg : 48|1@1+ (1.0,0.0) [0.0|1] ""  Vector__XXX
 SG_ KL_Heizkreisventilstellung : 49|2@1+ (1.0,0.0) [0.0|3] ""  Vector__XXX
 SG_ KL_FSH_Automatikbetrieb : 51|1@1+ (1.0,0.0) [0.0|1] ""  Kombi_PAG
 SG_ KL_SIH_LEH_Verteilung_VL : 52|3@1+ (1.0,0.0) [0.0|7] ""  Vector__XXX
 SG_ KL_SIH_LEL_Verteilung_VL : 55|3@1+ (1.0,0.0) [0.0|7] ""  Vector__XXX
 SG_ KL_SIH_LEH_Verteilung_VR : 58|3@1+ (1.0,0.0) [0.0|7] ""  Vector__XXX
 SG_ KL_SIH_LEL_Verteilung_VR : 61|3@1+ (1.0,0.0) [0.0|7] ""  Vector__XXX

BO_ 1663 Klima_05: 8 Gateway
 SG_ KL_Mod_Display_li : 0|4@1+ (1.0,0.0) [0.0|15] ""  Vector__XXX
 SG_ KL_Mod_Display_re : 4|4@1+ (1.0,0.0) [0.0|15] ""  Vector__XXX
 SG_ KL_Fondbed_vorne_aktiv : 8|1@1+ (1.0,0.0) [0.0|1] ""  Vector__XXX
 SG_ KL_Fond_re_reduziert : 9|1@1+ (1.0,0.0) [0.0|1] ""  Vector__XXX
 SG_ KL_Fond_li_reduziert : 10|1@1+ (1.0,0.0) [0.0|1] ""  Vector__XXX
 SG_ KL_Absperrventil_Fond : 11|1@1+ (1.0,0.0) [0.0|1] ""  Vector__XXX
 SG_ KL_SH_HL_Lastabschaltung : 12|2@1+ (1.0,0.0) [0.0|3] ""  Vector__XXX
 SG_ KL_SH_HR_Lastabschaltung : 14|2@1+ (1.0,0.0) [0.0|3] ""  Vector__XXX
 SG_ KL_Sollausblastemp_HL : 16|10@1+ (0.1,0) [0.0|102.2] "Unit_DegreCelsi"  Vector__XXX
 SG_ KL_Einheiten : 26|1@1+ (1.0,0.0) [0.0|1] ""  Vector__XXX
 SG_ KL_Kindersicherung : 27|1@1+ (1.0,0.0) [0.0|1] ""  Vector__XXX
 SG_ KL_Heizverbraucher_aus : 28|1@1+ (1.0,0.0) [0.0|1] ""  Vector__XXX
 SG_ KL_Heizverbraucher_Notaus : 29|1@1+ (1.0,0.0) [0.0|1] ""  Vector__XXX
 SG_ KL_Gebl_Verst_Abs_Modus : 30|1@1+ (1.0,0.0) [0.0|1] ""  Vector__XXX
 SG_ KL_Sollausblastemp_HR : 32|10@1+ (0.1,0) [0.0|102.2] "Unit_DegreCelsi"  Vector__XXX
 SG_ KL_ICO2_Sensor_defekt : 42|2@1+ (1.0,0.0) [0.0|3] ""  Kombi,Kombi_LB,Kombi_PAG
 SG_ KL_Umluft : 48|8@1+ (0.5,0) [0.0|100.0] "Unit_PerCent"  Vector__XXX
 SG_ KL_Geblaesespg_Fond : 56|8@1+ (0.1,0) [0.0|25.5] "Unit_Volt"  Vector__XXX

BO_TX_BU_ 707 :Gateway,Gateway_PAG;
BO_TX_BU_ 2589283684 :Gateway,Gateway_PAG;
BO_TX_BU_ 2549875476 :Gateway,Gateway_PAG;
BO_TX_BU_ 2550006548 :Kombi,Kombi_LB,Kombi_PAG;
BO_TX_BU_ 2463978599 :Gateway,Gateway_PAG;
BO_TX_BU_ 968 :Gateway,Gateway_PAG;
BO_TX_BU_ 324 :Gateway,Gateway_PAG;
BO_TX_BU_ 299 :Gateway,Gateway_PAG;
BO_TX_BU_ 310 :Gateway,Gateway_PAG;
BO_TX_BU_ 1412 :Gateway,Gateway_PAG;
BO_TX_BU_ 1283 :Gateway,Gateway_PAG;
BO_TX_BU_ 1381 :Gateway,Gateway_PAG;
BO_TX_BU_ 312 :Gateway,Gateway_PAG;
BO_TX_BU_ 1792 :Gateway,Gateway_PAG;
BO_TX_BU_ 1819 :Gateway,Gateway_PAG;
BO_TX_BU_ 1812 :Gateway,Gateway_PAG;
BO_TX_BU_ 1918 :Kombi,Kombi_LB,Kombi_PAG;
BO_TX_BU_ 1875 :Gateway,Gateway_PAG;
BO_TX_BU_ 1981 :CGS,Waehlhebel_SB;
BO_TX_BU_ 2463978614 :Gateway,Gateway_PAG;
BO_TX_BU_ 497 :Gateway,Gateway_PAG;
BO_TX_BU_ 1424 :Gateway,Gateway_PAG;
BO_TX_BU_ 2463978671 :Gateway,Gateway_PAG;
BO_TX_BU_ 960 :Gateway,Gateway_PAG;
BO_TX_BU_ 1420 :Gateway,Gateway_PAG;
BO_TX_BU_ 1646 :Gateway,Gateway_PAG;
BO_TX_BU_ 1663 :Gateway,Gateway_PAG;
CM_ BO_ 1609 "MLB_Evo ohne KD-Bit";
CM_ BO_ 960 "MQB";
CM_ BO_ 1646 "ab MQB 7.3";
CM_ BO_ 1663 "Klima";

CM_ SG_ 379 FCU_Absperrventil_schliessen "Abtrennung HT-Kreis von Heizkreis";
CM_ SG_ 379 FCU_Fehler_Abschaltanforderung "FCU-System-Stoppanforderung der FCU aufgrund Fehler in der FCU (nur mit Fehlerspeichereintrag)";
CM_ SG_ 379 FCU_Fehler_Entladung_defekt "Aktueller Fehlerstatus der Entladung";
CM_ SG_ 379 FCU_Fehler_Isofehler_I "Aktueller Isofehlerstatus des Brennstoffzellensystems";
CM_ SG_ 379 FCU_Fehler_Isofehler_II "Aktueller Isofehlerstatus des Brennstoffzellensystems";
CM_ SG_ 379 FCU_Fehler_Leistungsreduzierung "Leistungsreduzierung der FCU aufgrund Fehler aktiv (nur mit Fehlerspeichereintrag), z.B. LimpHome";
CM_ SG_ 379 FCU_Fehler_Notabschaltung "FCU-System-Notabschaltung  aufgrund Fehler in der FCU (nur mit Fehlerspeichereintrag)";
CM_ SG_ 379 FCU_HV_Anf "Anforderung 'HV-Netz aktivieren'";
CM_ SG_ 379 FCU_Ionenspuelung_aktiv "Spülung aller Kühlkreisläufe der Brennstoffzelle
0= keine Spülung
1= Spülung zwingend notwendig
2= Spülung Anforderung";
CM_ SG_ 379 FCU_IstModus "IST-Modus des FCU-Systems";
CM_ SG_ 379 FCU_Klima_Eingr "beschränkt Kompressorleistung / Kompressorabwurf";
CM_ SG_ 379 FCU_MinAbs_Leistung "Absolute minimale Leistung des BZ-Systems

Leistungsabgabe BZ-System - positiv
Leistungsaufnahme BZ-System - negativ";
CM_ SG_ 379 FCU_nicht_verfuegbar "FCU-System-Verfuegbarkeitsstatus";
CM_ SG_ 379 FCU_OBD_Lampe_Anf "Anforderung MIL (MalfunctionIndicationLamp) von FCU";
CM_ SG_ 379 FCU_Startstopp_Anforderung "Start/Stop-Anforderungen der FCU, z.B. Stopverbot, -freigabe, -anforderung, -wunsch und Startwunsch";
CM_ SG_ 379 FCU_Status_Spgfreiheit "0=Init
1=HV-Komponente spannungsfrei (U_Zwkr < 20V)
2=HV-Komponente nicht spannungsfrei (U_Zwkr >/= 25V, Hysterese)
3=Fehler (z.B. Fehler in der Sensorik)";
CM_ SG_ 379 FCU_TK_Betankung_Anforderung "Notwendig für Tankvorgang, um Weiterfahrt zu unterbinden.

Triggert:
- BZ zum Herunterfahren bzw. Sleep-Mode
- EPB aktivieren
- Fahrbereitschaft deaktivieren";
CM_ SG_ 379 FCU_TK_Freigabe_Tankklappe "Freigabesignal für Entriegelung Tankklappe.";
CM_ SG_ 379 FCU_Warn_H2_Konzentrat_Motorraum "Warnung H2-Konzentration im Motorraum

Ansteuerung Kühlerlüfter für Motorraumspülung & ggf. Deaktivierung Innenraumgebläse. Ggf. müssen Akustikgrenzen aufgehoben werden";

CM_ SG_ 2463978770 FCU_TK_H2_Fuellstand "Wasserstoff-Füllstand für Anzeige im Kombi";
CM_ SG_ 2463978770 FCU_TK_H2_Nachtanken_aktiv "Wird bei einer H2 Betankung gesetzt, und bleibt gesetzt bis v>5km/h für >5s";
CM_ SG_ 2463978770 FCU_TK_Meldungen "Anzeige von Infos und Fehler im  Kombi";
CM_ SG_ 2463978770 FCU_TK_Tankwarnungen "Warnt den Fahrer vor geringem Füllstand (analog: Reserve 1; Reserve 2)";
CM_ SG_ 2463978770 FCU_TK_Wasserstoffmasse_Netto "Wasserstoffmasse Netto ( Behälterschutz und Worst-Case-Reserve berücksichtigt)";

CM_ SG_ 606 FCU_Energieaequivalent "BZ-System-Wirkungsgrad korrigierter Heizwert";
CM_ SG_ 606 FCU_Verbrauch_FC "Überlaufender Zähler von der BZ abgegebene elektrische Arbeit";
CM_ SG_ 606 FCU_Verbrauch_FC_Nebag "Überlaufender Zähler von den BZ Nebenaggregaten aufgenommene Arbeit";
CM_ SG_ 606 FCU_Verbrauch_FC_Nebag_Ueberlauf "Erster Überlauf Verbrauchssignal";
CM_ SG_ 606 FCU_Verbrauch_FC_Ueberlauf "Erster Überlauf Verbrauchssignal";
CM_ SG_ 606 FCU_Verbrauch_H2 "Überlaufender Zähler/Eingebrachte H2 Masse";
CM_ SG_ 606 FCU_Verbrauch_H2_Ueberlauf "Erster Überlauf Verbrauchssignal";

CM_ SG_ 607 FCU_Anzeigeverbrauch_H2 "Momentanverbrauch H2";
CM_ SG_ 607 FCU_TK_Fuellstand "Aktueller nutzbarer Tankfüllstand wird in FCU berechnet.";
CM_ SG_ 607 FCU_TK_Wasserstoffmasse_Tank "Nutzbare Gewichtsmasse des sich in den Tanks befindenden Wasserstoffs.";
CM_ SG_ 607 FCU_Verb_FC_Nebag_Masaequi "Überlaufender Zähler/Eingebrachte H2 Masse für Nebenaggregate";
CM_ SG_ 607 FCU_Verb_FC_Nebag_Masaequi_Ueb "Erster Überlauf Verbrauchssignal";

CM_ SG_ 707 eAWS_Warnmeldung_Prio3 "Signal zur Ansteuerung der Prio3 Warnmeldung für das eAWS im Kombi";
CM_ SG_ 707 EFP_Anf_Kuehlklappenwarnung "Signal wird zur Ansteuerung einer Kühlklappenwarnung im Kombiinstrument genutzt";
CM_ SG_ 707 EFP_MomRad_Begr "Begrenzung des beschleunigt wirkenden Antriebstrangsollmomentenanteils auf Summenradebene 
Für MLBevo: Faktor in TS_Faktor_Radmomente beachten!";
CM_ SG_ 707 FA_Warnung_Transportniveau "Signal zur Ansteuerung einer Warnmeldung, wenn beim Transportmodus das Zielniveau nicht angefahren wird";
CM_ SG_ 707 FDR_04_BZ "4bit Botschaftszähler, wird mit jeder Sendebotschaft inkrementiert";
CM_ SG_ 707 FDR_04_CRC "Für MLB:
Berechnung siehe Lastenheft 'Kommunikationsabsicherung für FlexRay und CAN'
Ab MQB und MLBevo:
Berechnung siehe Lastenheft 'End-to-End Kommunikationsabsicherung'

Endwerte siehe Begleitdokument 'S-PDU Kennungsfolgen'";
CM_ SG_ 707 FDR_M_HL_02 "Momentenanzeige für MMI.";
CM_ SG_ 707 FDR_M_HR_02 "Momentenanzeige für MMI.";
CM_ SG_ 707 FDR_M_VL_02 "Momentenanzeige für MMI.";
CM_ SG_ 707 FDR_M_VR_02 "Momentenanzeige für MMI.";

CM_ SG_ 2589283684 FoD_Anz_Funktionsabschaltung "Signal triggert Aufschaltung eines Popups, um dem Fahrer die Abschaltung einer Funktion zu melden.";
CM_ SG_ 2589283684 FoD_Transmission_Info "Mit dem Signal zeigt der FoD-Master allen FoD-Slaves den Beginn und das Ende eines Freischaltuebertragungszykluses (FS-ID-Zyklus) an.";

CM_ SG_ 2549875476 FoD_Kombi_Req_Data "Function on demand request an Kombiinstrument";

CM_ SG_ 2550006548 FoD_Kombi_Resp_Data "Function on demand response vom Kombiinstrument";

CM_ SG_ 2463978599 MKE_Anpassung_FZ "Informationen der MKE zur Anpassung der Status der weiteren Fahrerzustände
Adaptionswert der Müdigkeiterkennung";
CM_ SG_ 2463978599 MKE_Fahrzeit "Fahrzeit in Minuten für die Anzeige im Kombi bei einer Meldung";

CM_ SG_ 968 Freilauf_Charisma_FahrPr "MLBevo: Aktuelles Fahrprogramm des Charisma-Teilnehmers (siehe Systemlastenheft Drive Select)
MQB: Istwert der Kennlinie (siehe Systemlastenheft MQB FPA)";
CM_ SG_ 968 Freilauf_Charisma_Status "Charisma Systemstatus des Charisma-Teilnehmers

Wert 0x3 ist nur für Fahrzeuge ab MQB relevant";
CM_ SG_ 968 GE_amax_moeglich "AL/DL: maximal mögliche Beschleunigung unter Berücksichtigung aller möglichen Gänge.

Eine Reduzierung des maximalen Motormoments durch Efficiency wird in dem Signal berücksichtigt.

VL: maximal mögliche Beschleunigung bei Nenndrehzahl (Efficency wird";
CM_ SG_ 968 GE_Charisma_FahrPr "MLBevo: Aktuelles Fahrprogramm des Charisma-Teilnehmers (siehe Systemlastenheft Drive Select)
MQB: Istwert der Kennlinie (siehe Systemlastenheft MQB FPA)";
CM_ SG_ 968 GE_Charisma_Status "Charisma Systemstatus des Charisma-Teilnehmers

Wert 0x3 ist nur für Fahrzeuge ab MQB relevant";
CM_ SG_ 968 GE_Codierung_MSG "Statusausgabe der Diagnose für Falschverbau. Plausibilisierung der empfangenen Motor- und Getriebevariante mit der erwarteten Motor- und Getriebevarianten.";
CM_ SG_ 968 GE_Freigabe_Info_WFS "WFS-Freigabeinformation";
CM_ SG_ 968 GE_Freigabe_Verfallsinfo_WFS "WFS";
CM_ SG_ 968 GE_LaunchControl "Während einer LaunchControl-Anfahrt sendet das Getriebesteuergerät das Bit LaunchControl aktiv.
Die Bremse wertet dieses Bit aus, um während einer solchen Anfahrt die Regelgrenzen der Schlupfregelung zu erweitern.
Im Motor Nutzung zur Verbesserung des A";
CM_ SG_ 968 GE_LaunchControl_LB "LB launch control status";
CM_ SG_ 968 GE_LFR_Adaption "Qualifiziert das ausgegeben Motorbelastungsmoment (durch GE_Vorsteuermoment) für die Verwendung zur LFR (Leerlauffüllungsregelung) im Moto";
CM_ SG_ 968 GE_OBD_AbsperrVent "Das Getriebesteuergerät führt eine elektrische Diagnose des von ihm angesteuerten Absperrventils für den Öl-Wasser-Wärmetauscher durch und übermittelt das Ergebnis an das MSG (Standard-4Bit-OBD-Status, nicht alle Zustände müssen genutzt werden; so sind z.";
CM_ SG_ 968 GE_OBD_Status "Dieses Bit steuert die MIL-Lampe an (Motorsteuergerät reicht diese Info an Kombi weiter).";
CM_ SG_ 968 GE_Remotestart_Betrieb "Das GSG ist für den Remotestart-Betrieb bereit. Nach Empfang der Motorstartanforderung für RSt-Betrieb durch BCM wird der Fahrzeugmotor gestartet und solange der Motor läuft, bleibt dieses Bit aktiv. Dieses Signal ist nur zur Verwendung durch das BCM zur ";
CM_ SG_ 968 GE_Sperr_Info_WFS "WFS-Sperrinformation";
CM_ SG_ 968 GE_Status_PaddleNeutral "Status Ablauf der Paddle Neutral Funktion";
CM_ SG_ 968 GE_Sumpftemperatur "Getriebesumpftemperatur wird über den Temperatursensor auf der Getriebeplatine ermittelt. Die absolute Sumpftemperatur wird vom Motor empfangen, um entsprechende Kühlleistung für das Getriebe einzustellen.";
CM_ SG_ 968 GE_Zustand_Kuppltemp "Dieses Signal gibt den Temperaturzustand der Kupplung im DQ-Getriebe (z. Zt. DQ2x0, DQ500) an das ACC-System.";

CM_ SG_ 324 GE_Ist_Fahrstufe "Im Getriebe eingelegte Fahrstufe zur Anzeige am Bedienelement. Ist die Fahrstufe ungültig, wird keine Fahrstufe angezeigt.";
CM_ SG_ 324 GE_N_Haltephase "Das Getriebe signalisiert dem Waehlhebel, dass die N-Haltephase aktiv ist. 
Danach kann der Waehlhebel ein Abschalten des I-CAN ermöglichen";
CM_ SG_ 324 GE_Soll_Haltemagnet "Sollposition des Parksperren-Haltemagneten für die Ansteuerung durch den Waehlhebel";
CM_ SG_ 324 GE_Test_Freigabe "Das Bit wird auf 1 gesetzt, wenn gültige Testparameter gesendet werden.";
CM_ SG_ 324 GE_Testparameter_1 "Testparameter 1 (Frage) zur Überwachung des Wählhebel-SG";
CM_ SG_ 324 GE_Testparameter_2 "Testparameter 2 (Frage) zur Überwachung des Wählhebel-SG";
CM_ SG_ 324 GE_WH_Abschalten "Mit diesem Bit kann das Getriebe das Wählhebel-SG reseten bzw. dauerhaft deaktivieren. Der Wählhebel geht dann in einen Standby-Modus. ";
CM_ SG_ 324 GE_WH_Sperre "Bit wird auf 1 gesetzt, wenn getriebeseitigen Bedingungen erfüllt sind, um Wählhebel zu bewegen.";
CM_ SG_ 324 Getriebe_16_CRC "Für MLB:
'Berechnung siehe Lastenheft 'Kommunikationsabsicherung für FlexRay und CAN''

Ab MQB und MLBevo:
'Berechnung siehe Lastenheft 'End-to-End Kommunikationsabsicherung''

Endwerte siehe Begleitdokument 'S-PDU Kennungsfolgen'";
CM_ SG_ 324 WH_gespeicherte_Fahrstufe "Kurzzeit-Fahrstufenspeicherung in Abhängigkeit von GE_Ist_Fahrstufe.";
CM_ SG_ 324 WH_P_Taste "Das Signal zeigt den Status der P-Taste an.";
CM_ SG_ 324 WH_SensorPos_roh "Zustand Wählhebelposition. Wird das Signal WH_Variante nicht bedient, ist die Signalcodierung 
wie im MQB zu verwenden.

MQB:
0=Init
1=Position_1
2=Position_2
3=Position_3
4=nicht_betaetigt
5=Position_D
6=Position_N
7=Position_R
8=Position_P
";
CM_ SG_ 324 WH_Warnung_02 "Warnmeldungen vom Waehlhebel an das Kombi";
CM_ SG_ 324 WH_Warnung_03 "Warnungen des CGS im Lambo Urus";

CM_ SG_ 299 GRA_Abbrechen "GRA : aus mit speichern
ACC : Soft aus";
CM_ SG_ 299 GRA_ACC_01_BZ "4bit Botschaftszaehler, wird mit jeder Sendebotschaft inkrementiert
Botschaft asynchron geroutet. Zählerwert kann springen.";
CM_ SG_ 299 GRA_ACC_01_CRC "Für MLB:
'Berechnung siehe Lastenheft 'Kommunikationsabsicherung für FlexRay und CAN''

Ab MQB und MLBevo:
'Berechnung siehe Lastenheft 'End-to-End Kommunikationsabsicherung''

Endwerte siehe Begleitdokument 'S-PDU Kennungsfolgen'";
CM_ SG_ 299 GRA_Codierung "Das Signal zeigt an, ob das Sende-SG (SMLS/MFL) auf GRA- oder ACC-Bedienteil codiert ist:
0: kein GRA- oder ACC Bedienteil
1: GRA-Bedienteil
2: ACC-Bedienteil
3: Limiter_Only-Bedienteil";
CM_ SG_ 299 GRA_Fehler "Das Signal zeigt an, dass das Sende-SG (SMLS/MFG) einen Defekt des GRA-Bedienteils erkannt hat und hierzu ein FSPE abgelegt wurde.";
CM_ SG_ 299 GRA_Hauptschalter "Stellung des GRA/ACC-Hauptschalters: 
Bei gerastetem Hauptschalter:
0: Hauptschalter aus
1: Hauptschalter ein
Bei getastetem Hauptschalter:
0: Taster nicht betätigt
1: Taster betätigt";
CM_ SG_ 299 GRA_LIM_Taste_verfuegbar "Das Signal zeigt an, ob eine Limiter-Umschalttaste am jeweiligen GRA/ACC-Bedienelement vorhanden ist.";
CM_ SG_ 299 GRA_Limiter "Stellung des Limiter-Tasters";
CM_ SG_ 299 GRA_reserveByte4 "Zweck: Befüllen der reservierten Bitpositionen mit 0 (wg. LIN-Teilnehmer MFL)";
CM_ SG_ 299 GRA_reserveByte5 "Zweck: Befüllen der reservierten Bitpositionen mit 0 (wg. LIN-Teilnehmer MFL)";
CM_ SG_ 299 GRA_reserveByte6 "Zweck: Befüllen der reservierten Bitpositionen mit 0 (wg. LIN-Teilnehmer MFL)";
CM_ SG_ 299 GRA_reserveByte7 "Zweck: Befüllen der reservierten Bitpositionen mit 0 (wg. LIN-Teilnehmer MFL)";
CM_ SG_ 299 GRA_reserveByte8 "Zweck: Befüllen der reservierten Bitpositionen mit 0 (wg. LIN-Teilnehmer MFL)";
CM_ SG_ 299 GRA_Tip_Hoch "Tippschalter Tip Up / Geschwindigkeit erhöhen";
CM_ SG_ 299 GRA_Tip_Runter "Tippschalter Tip Down / Geschwindigkeit reduzieren";
CM_ SG_ 299 GRA_Tip_Setzen "Tippschalter Set";
CM_ SG_ 299 GRA_Tip_Stufe_2 "Signal zeigt an, dass der zweistufige GRA/ACC-Hebel (8_Positions_Bedienteil) in der 2. Tip-Stufe betätigt wird. Das Signal wird nur gleichzeitig mit dem Signal GRA_Tip_Hoch oder GRA_Tip_Runter gesetzt, wobei die Bits GRA_Tip_Hoch bzw. GRA_Tip_Runter die R";
CM_ SG_ 299 GRA_Tip_Wiederaufnahme "Tippschalter Wiederaufnahme";
CM_ SG_ 299 GRA_TravelAssist "Taste für TravelAssist";
CM_ SG_ 299 GRA_Typ_Bedienteil "Das Signal kennzeichnet die Variante des GRA/ACC-Bedienteils:
0: Init
1: 4-Positionen-Bedienteil (z.B. GRA im Blinkerhebel)
2: 6-Positionen-Bedienteil (GRA/ACC-Bedienteil mit separaten Stellungen für Set/Resume/TipUp/TipDown) 
3: 8-Positionen-Bediente";
CM_ SG_ 299 GRA_Typ_Hauptschalter "Variante des GRA/ACC-Hauptschalters:
0: gerasteter Hauptschalter (bzw. Taster mit Speicherung des Status im SMLS (PAG))
1: getasteter Hauptschalter, keine Speicherung des Status im SMLS";
CM_ SG_ 299 GRA_Verstellung_Zeitluecke "Verstellung der Zeitlücke für ACC

DIST -1 = Zeitluecke um 1 Stufe kleiner
DIST +1 = Zeitluecke um 1 Stufe groeßer
DIST Toggle = Zeitlücke um 1 Stufe kleiner, von kleinster Stufe auf größte Stufe";

CM_ SG_ 310 HAL_01_BZ "Botschaft asynchron geroutet. Zählerwert kann springen.";
CM_ SG_ 310 HAL_01_CRC "Für MLB:
'Berechnung siehe Lastenheft 'Kommunikationsabsicherung für FlexRay und CAN''

Ab MQB und MLBevo:
'Berechnung siehe Lastenheft 'End-to-End Kommunikationsabsicherung''

Endwerte siehe Begleitdokument 'S-PDU Kennungsfolgen'
";
CM_ SG_ 310 HAL_Charisma_FahrPr "MLBevo: Aktuelles Fahrprogramm des Charisma-Teilnehmers (siehe Systemlastenheft Drive Select)
MQB: Istwert der Kennlinie (siehe Systemlastenheft MQB FPA)";
CM_ SG_ 310 HAL_Charisma_Status "Rückmeldung an den Charisma-Master";
CM_ SG_ 310 HAL_EFP_FahrPr "Aktueller Ist-Zustand der HAL";
CM_ SG_ 310 HAL_Fahrerwunschwinkel_Soll "Zielwinkel (=Fahrerwunschwinkel) am Rad Hinterachslenkung in Grad";
CM_ SG_ 310 HAL_max_Gradient "maximaler Zustellgradient für die Stabilisierungsfunktion mit HAL durch ESP";
CM_ SG_ 310 HAL_QBit_Radwinkel "Wenn Bit gesetzt, dann entspreicht das Signal nicht mehr ASIL-D. (z.B. Ausfall der redundanten Sensorik)";
CM_ SG_ 310 HAL_Radwinkel "Zusätzlich durch die HAL gestellter Radwinkeloffset an der Hinterachse in Grad";
CM_ SG_ 310 HAL_Status "Status der Hinterachslenkung
0: normaler Betrieb 
1: HAL verriegelt (z.B. harter Fehler, nicht kalibriert)
2: Rücknahme der Leistung, Funktion eingeschränkt/Derating aktiv 
3: HAL deaktiviert";
CM_ SG_ 310 HAL_Status_2 "Zustand der Hinterachlenkung in der Smart application";
CM_ SG_ 310 HAL_VZ_Fahrerwunschwinkel_Soll "Soll-Lenkrichtung der HAL";
CM_ SG_ 310 HAL_VZ_Radwinkel "Lenkrichtung der HAL";
CM_ SG_ 310 HAL_Warnungen "Warnmeldungsanforderung von der Hinterachslenkung an das Kombiinstrumnent";
CM_ SG_ 310 HAL_Winkelbegrenzung "Signal liefert die Info über eine aktive Winkelbegrenzung in der HAL aufgrund Bauteilschutz";

CM_ SG_ 1412 HSP_01_CRC "CRC8-Checksumme über alle Datenbytes der Botschaft HSPs_01

 Für MLB:
 'Berechnung siehe Lastenheft 'Kommunikationsabsicherung für Flexray und CAN''

 Ab MQB und MLBevo:
 'Berechnung siehe Lastenheft 'End-to-End Kommunikationsabsicherung'

 Endwer";
CM_ SG_ 1412 HSP_BAP_Messages "Statusinformationen für BAP Kommunikation.";
CM_ SG_ 1412 HSP_Charisma_FahrPr "MLBevo: Aktuelles Fahrprogramm des Charisma-Teilnehmers (siehe Systemlastenheft Drive Select)
MQB: Istwert der Kennlinie (siehe Systemlastenheft MQB FPA)";
CM_ SG_ 1412 HSP_Charisma_Status "Rückmeldung an den Charisma-Master

Wert 0x3 ist nur für Fahrzeuge ab MQB relevant";
CM_ SG_ 1412 HSP_def "Spoilersteuergerät defekt";
CM_ SG_ 1412 HSP_Endlage_ausgefahren "Spoiler in Endlage ausgefahren";
CM_ SG_ 1412 HSP_Endlage_eingefahren "Spoiler in Endlage eingefahren";
CM_ SG_ 1412 HSP_Komponentensteuerung "Ansteuerart des HSP";
CM_ SG_ 1412 HSP_LED_Error "Spoiler meldet LED-Fehler";
CM_ SG_ 1412 HSP_man_Betaet_nicht_zulaessig "Manuelle Betätigung des Spoilers nicht zulässig.";
CM_ SG_ 1412 HSP_Motor_def "elektr. Fehler im Spoilermotor";
CM_ SG_ 1412 HSP_Motor_Temp_Text "Kombimeldung für Systemverfügbarkeit";
CM_ SG_ 1412 HSP_ResponseError "siehe LIN2.0-Specification
(Darf nicht über ein Fehlergueltigkeitsbit abgesichtert werden!)";
CM_ SG_ 1412 HSP_Taster_Error "Spoiler meldet Tasterfehler";
CM_ SG_ 1412 HSP_Warnung_LED "Kombi Warnung LED Spoiler";
CM_ SG_ 1412 HSP_Warnung_Text "Kombi Warnung Text Spoiler";
CM_ SG_ 1412 HSP_Warnung_Ton "Kombi Warnung Ton Spoiler";

CM_ SG_ 1609 HUD_Aktiv "Zeigt an ob das HUD eingeschaltet und anzeigebereit oder ausgeschaltet ist. ";
CM_ SG_ 1609 HUD_Anforderung_Fokus "Signal um den Bedienfokus vom Kombi anzufordern.";
CM_ SG_ 1609 HUD_Anzeigefehler_NV "Nightvisionbild kann im HUD aufgrund eines Fehlers nicht angezeigt werden";
CM_ SG_ 1609 HUD_FAS_Anzeige_Kombi "Zeigt an ob die FAS Inhalte im Kombi oder im HUD angezeigt werden sollen.";
CM_ SG_ 1609 HUD_KDK_Anzeige_Kombi "Zeigt an ob die KDK im Kombi oder im HUD angezeigt werden sollen.";
CM_ SG_ 1609 HUD_NV_in_Anzeige "Rueckmeldung,ob NV-Inhalte im HUD angezeigt werden.";
CM_ SG_ 1609 HUD_PEA_Anzeige_Kombi "Zeigt an ob die PEA Inhalte im Kombi oder im HUD angezeigt werden sollen.";
CM_ SG_ 1609 HUD_VZE_AIO_Anzeige_Kombi "Zeigt an ob die VZE und AIO Inhalte im Kombi oder im HUD angezeigt werden sollen.";
CM_ SG_ 1609 HUD_VZE_in_Anzeige "Rückmeldung,ob VZE-Inhalte im HUD angezeigt werden.";

CM_ SG_ 1283 HV_Bordnetz_aktiv "Signalisiert ein aktives Hochvoltbordnetz. Für die Belastbarkeit des HV-Netzes müssen Strom- bzw. Leistungsgrenzen eingehalten werden";
CM_ SG_ 1283 HV_Bordnetz_Fehler "Status ob im  HV-Netz ein Fehler detektiert wurde.";
CM_ SG_ 1283 HVK_01_CRC "Für MLB:
'Berechnung siehe Lastenheft 'Kommunikationsabsicherung für FlexRay und CAN''

Ab MQB und MLBevo:
'Berechnung siehe Lastenheft 'End-to-End Kommunikationsabsicherung''

Endwerte siehe Begleitdokument 'S-PDU Kennungsfolgen'";
CM_ SG_ 1283 HVK_AIAD_Sollmodus_2 "Freigabe für die HV-Netz Teilnahme";
CM_ SG_ 1283 HVK_AktiveEntladung_Anf "Anforderung zum aktiven Entladen des HV-Netzes, während der Abschaltung des HV-Netz.";
CM_ SG_ 1283 HVK_BMS_Sollmodus "Angeforderter Sollmodus der HV-Batterie:
0 : HV_Off                                
1 : HV_On (HS geschlossen)                
2 : nicht belegbar                        
3 : AC-Laden_erw (HS +AC_2-Schütze geschlossen)                         
4 : AC-";
CM_ SG_ 1283 HVK_DCDC_EKK_Sollmodus "Bedarfsgerechtes Aktivieren des 400V-DCDC-Wandlers bei Anforderung durch TME";
CM_ SG_ 1283 HVK_DCDC_Sollmodus "angeforderte Soll-Betriebsart des DC/DC-Wandlers: 
0: Standby; Kommunikation aktiv
1: Zwischenkreis des HV-Netzes wird vorgeladen; HV-Netz wird aktiviert und darf nicht  
    belastet werden.
2: Tiefsetzen (HV --> BN 14,4V)
    Sollwertvorgabe projek";
CM_ SG_ 1283 HVK_EKK_Sollmodus "Sollmodus elektrischer Klimakompressor";
CM_ SG_ 1283 HVK_Gesamtst_Spgfreiheit "Status des HV-Systems";
CM_ SG_ 1283 HVK_HV_Netz_Warnungen "Anforderung Warnung/Fehler HV-System im Kombi
0: Keine Warnung/Init
1:Anforderung_Anzeige_Warnung_HV-Netz (gelbes Symbol)
2:Anforderung_Anzeige_Fehler_HV-Netz (rotes Symbol)
3:Anforderung_Anzeige_Warnung_Kein_Wiederstart_möglich";
CM_ SG_ 1283 HVK_HVLM_Sollmodus "Angeforderter Sollmodus des Lademanagers.";
CM_ SG_ 1283 HVK_HVPTC_Sollmodus "Sollmodus HV-PTC
0 : keine Freigabe
1 : Freigabe
2 : Freigabe_ausgesetzt
3 : nicht belegbar
4 : nicht belegbar
5 : nicht belegbar
6 : nicht belegbar
7 : Init   (CAN-Initialisierung)   

Info: 'nicht belegbar' d.h. Sollmodus nicht relevant für HV";
CM_ SG_ 1283 HVK_Iso_Fehlerstatus "Das Signal gibt an, ob ein Isolationsfehler an der Ladesäule vorliegt  (BMS_IsoFehler = IsoFehler_Schwelle_2) und dient als Trigger einer Warnmeldung im Kombi-Instrument.";
CM_ SG_ 1283 HVK_Iso_Messung_Start "Anforderung an die isolationswiderstandsüberwachenden HV-Komponenten zur Durchführung der Isolations-Widerstandsmessung.";
CM_ SG_ 1283 HVK_Istmodus_Anf "HVK-Anforderung an alle HV-Komponenten deren Istmodus im schnellen Zyklus (Inhibitzeit) zu senden.";
CM_ SG_ 1283 HVK_MO_EmSollzustand "Anforderung vom HVK Sollzustand der Elm_State
0 = HvOff              
1 = HvStbyReq          
2 = HvStbyWait         
3 = HvBattOnReq        
4 = HvBattOnWait       
10 = HvOnIdle          
18 = HvOnDrvReq        
19 = HvOnDrvWait       
20 = HvO";
CM_ SG_ 1283 HVK_TN1_Sollmodus "Angeforderter Sollmodus der Steuereinheit für das Schütze des Teilnetz1 'Ladepfad':
0 : HV_Off                                
1 : HV_On (Schütz geschlossen)                
2 : reserviert
3 : Init   (CAN-Initialisierung)";

CM_ SG_ 1381 HVLM_Freigabe_Lastabwurf "Für die PHEV’s 2.0 (ertüchtigtes HV-System für Emission/Reichweite) muss zur Reduzierung von Leistungsvorhalten eine Laständerung im HV-System erkannt und ausgeregelt werden:

Im Ladebetrieb muss eine negative Laständerung der Nebenverbraucher (z.B. Hei";
CM_ SG_ 1381 HVLM_FreigabeKlimatisierung "Klimatisierung freigeben";
CM_ SG_ 1381 HVLM_FreigabeTankdeckel "Tankdeckelfreigabe";
CM_ SG_ 1381 HVLM_HV_Abstellzeit "Zeitraum zwischen HV-Deaktiviert und HV-Aktiviert";
CM_ SG_ 1381 HVLM_IsoMessung_Anf "Signalisierung an den HVK, ob während des Ladens eine Iso-Messung durchgeführt werden muss.
0 = Laden mit Isomessung
1 = Laden ohne Isomessung";
CM_ SG_ 1381 HVLM_IstSpannung_HV "Ausgangsspannung des Ladegerätes und DC-Spannung der Ladesäule. Messung zwischen den DC HV-Leitungen. ";
CM_ SG_ 1381 HVLM_Ladesystemhinweise "Anzeigen von Hinweisen zum Ladesystem.
Anzeigen, dass das Ladesystem defekt ist.";
CM_ SG_ 1381 HVLM_Ladetexte "Anzeige, ob AC- oder DC-Laden nicht möglich ist";
CM_ SG_ 1381 HVLM_LG_Sollmodus "Sollmodus AC Ladegerät";
CM_ SG_ 1381 HVLM_MaxStrom_Netz "maximal zulässiger Strom auf Primärseite (AC) des Ladegerätes
Minima aus
Vorgabe z.B. über
- intelligente Kommunikation
- Control Pilot Duty Cycle
- Widerstandskodierung Kabel (Proximity)
- Vorgabe MMI, o.ä.";
CM_ SG_ 1381 HVLM_Schluessel_Anfrage "Anforderung HVLM an BCM für Schlüsselsuche über Kessy";
CM_ SG_ 1381 HVLM_Start_Spannungsmessung_DCLS "Meldung an das BMS, dass an der DC-Ladesäule eine Messspannung aufgeschaltet wird.";
CM_ SG_ 1381 HVLM_Stecker_Verriegeln "Anforderung Steckerverriegelung";
CM_ SG_ 1381 HVLM_Zustand_LED "Zustand der Lade-LED im Kombi und Dosenbeleuchtung";
CM_ SG_ 1381 PnC_Trigger_OBC_cGW "Trigger-Signal für die UDS-Kommunikation zwischen cGW und OBC für die Funktion Plug & Charge Online";

CM_ SG_ 312 IPA_01_BZ "Fehlende Beschreibung (Import)
Botschaft asynchron geroutet. Zählerwert kann springen.";
CM_ SG_ 312 IPA_01_CRC "Für MLB:
'Berechnung siehe Lastenheft 'Kommunikationsabsicherung für FlexRay und CAN''

Ab MQB und MLBevo:
'Berechnung siehe Lastenheft 'End-to-End Kommunikationsabsicherung''

Endwerte siehe Begleitdokument 'S-PDU Kennungsfolgen'";
CM_ SG_ 312 IPA_Anforderung_HMS "Anforderung vom IPA (Intelligent Park Assist) an das HMS (Haltemanagement System)";
CM_ SG_ 312 IPA_APS_LED "Ansteuerung der APS Funktions-LED durch das BCM.
0 = LED aus
1 = LED ein
2 = LED blinken
3 = Funktion gesperrt, LED aus
4 = frei
5 = frei
6 = Init
7 = frei";
CM_ SG_ 312 IPA_Fahrstufenwunsch "Flankengesteuerter Fahrstufenwunsch von IPA/PiloPa an das Getriebe";
CM_ SG_ 312 IPA_Parken_beibehalten_HMS "Anforderung seitens Pilotiertem Parken bzw. Manövrierassistent das Lösen der EPB bzw. das Auslegen der Parksperre zu blockieren";
CM_ SG_ 312 IPA_PLA_LED "Ansteuerung der PLA Funktions-LED durch das BCM.
0 = LED aus
1 = LED ein
2 = LED blinken
3 = Funktion gesperrt, LED aus
4 = frei
5 = frei
6 = Init
7 = frei";
CM_ SG_ 312 IPA_Sollbeschleunigung "Anforderung vom IPA an den TSK, das Fahrzeug zu beschleunigen.";
CM_ SG_ 312 IPA_Status "Zustand der IPA-Statusmaschine";
CM_ SG_ 312 IPA_Status_EDR "Statusinformation von IPA/PiloPa für EDR";
CM_ SG_ 312 IPA_Status_IPA_GE "Statusinformation von IPA/PiloPa für Handshakemechanismus mit dem Getriebe-SG";
CM_ SG_ 312 IPA_Status_IPA_TSK "Statusinformation vom IPA für Handshakemechanismus mit TSK";
CM_ SG_ 312 Parken_aktives_System "Das Signal zeigt an, welches der Parksysteme auf dem zFAS gerade aktiv ist.";
CM_ SG_ 312 Parken_erhoehtes_Moment "Anforderung einer spezifizierten Motormomenten-Rampe seitens IPA/PiloPa für das Überfahren einer Schwelle oder eines Bordsteins.";
CM_ SG_ 312 Parken_Fahrbereitschaft_Anf "Anforderung seitens iPA/pilotiertes Parken, die Fahrbereitschaft aufrecht zu erhalten und das Verlassenskonzept im MSG beim „automatischen Parkvorgang“ zu deaktivieren.";
CM_ SG_ 312 Parken_Motorlauf_Anf "Anforderung Motorlauf seitens PiloPa";

CM_ SG_ 1792 ISO_ALL_01_Req_Data "Funktionaler Request ALL";

CM_ SG_ 1819 ISO_HUD_Req_Data "OffBoard Tester Diagnose Request HUD";

CM_ SG_ 1925 ISO_HUD_Resp_Data "OffBoard Tester Diagnose Response HUD";

CM_ SG_ 1812 ISO_Kombi_Req_Data "Diagnose Request Kombiinstrument";

CM_ SG_ 1918 ISO_Kombi_Resp_Data "Diagnose Response Kombiinstrument";

CM_ SG_ 1875 ISO_Waehlhebel_Req_Data "OffBoard Tester Diagnose Request Waehlhebel";

CM_ SG_ 1981 ISO_Waehlhebel_Resp_Data "OffBoard Tester Diagnose Response Waehlhebel";

CM_ SG_ 2463978614 KAS_Anf_Bremsruck "Anforderung Warnruck";
CM_ SG_ 2463978614 KAS_Anf_OPS "Anforderung des OPS durch den Kreuzungsassistenten";
CM_ SG_ 2463978614 KAS_Anf_Prefill "Anforderung Prefill";
CM_ SG_ 2463978614 KAS_Anzeige_Info_links "Anzeige für Inforelevantes Objekt links";
CM_ SG_ 2463978614 KAS_Anzeige_Info_rechts "Anzeige für Inforelevantes Objekt rechts";
CM_ SG_ 2463978614 KAS_Anzeige_Warnung "Anzeige der Warnung";
CM_ SG_ 2463978614 KAS_Kritikalitaetslevel "Mit dem Signal wird das Kritikalitätslevel der Funktion KA dargestellt. Je höher das Kritikalitätslevel ist, desto höher die Wahrscheinlichkeit einer Kollision mit Querverkehr.
wird auch befüllt wenn KA vor Kunde deaktiviert ist.

Benötigt zur Kommunik";
CM_ SG_ 2463978614 KAS_PreSense_Modus_System "Signal zur Realisierung der BAP-Kommunikation für PreSense";
CM_ SG_ 2463978614 KAS_Status "Statusausgabe der Funktion";
CM_ SG_ 2463978614 KAS_Texte "Anzeige der KAS Texte";
CM_ SG_ 2463978614 KAS_Verfuegbarkeit "Signal zur Realisierung der BAP-Kommunikation für PreSense.
Kommunikation des Kreuzungsassistent (zFAS) mit dem BAP-Koordinator (SC).

Damit wird die Verfügbarkeit der Funktion KA übermittelt, um vor Kunde die Verfügbarkeit mindestens einer Funktion de";
CM_ SG_ 2463978614 KAS_Verz_Anf "Verzögerungsanforderung von KAS an VZM";

CM_ SG_ 497 FBS_Aktivierung_Pilot_Parken "Aktivierung der Funktion pilotiertes Parken";
CM_ SG_ 497 FFB_FDF_Taste "FDF Taste am Funkschluessel";
CM_ SG_ 497 FFB_Joker_Taste "Frei konfigurierbare Taste auf der Funkfernbedienung (für Verdecktaste, UGDO Taste).
";
CM_ SG_ 497 FFB_Park_Taste "Parktaste Funkschluessel";
CM_ SG_ 497 FFB_Remotestart_Taste "Remotestart Taste Funkschluessel";
CM_ SG_ 497 KY_Auf_Taste "Auf-Taste Funkschluessel";
CM_ SG_ 497 KY_Bereich "Schlüsselentfernung für Funktionen Annäherungslicht, automatisches Entriegeln";
CM_ SG_ 497 KY_BT_Entriegelung_Autorisiert "Erkennung / Authorisierung Keyless BT
";
CM_ SG_ 497 KY_BT_Verriegelung_Autorisiert "Authorisierung Verriegelungssensor Keyless BT
";
CM_ SG_ 497 KY_EasyClose_Abbruch "ID-Geber während HD-Zufahrt im Nahbereich EasyClose erkannt";
CM_ SG_ 497 KY_EasyClose_Status "Signal zur LED Ansteuerung im HD-Verriegelungstaster für die Funktion EasyClose.";
CM_ SG_ 497 KY_Front_Entr_Autorisiert "Erkennung / Authorisierung Keyless Front";
CM_ SG_ 497 KY_Front_Verr_Autorisiert "Authorisierung Verriegelungssensor Keyless Front";
CM_ SG_ 497 KY_FT_Entriegelung_Autorisiert "Erkennung / Authorisierung Keyless FT
";
CM_ SG_ 497 KY_FT_Verriegelung_Autorisiert "Authorisierung Verriegelungssensor Keyless FT
";
CM_ SG_ 497 KY_HBFS_Entriegelung_Autorisiert "Erkennung / Authorisierung Keyless HBFS
";
CM_ SG_ 497 KY_HBFS_Verriegelung_Autorisiert "Authorisierung Verriegelungssensor Keyless HBFS


";
CM_ SG_ 497 KY_HD_Auffahrt "Auffahrt HD nach Wiedereintritt ID-Geber in EasyClose Nahbereich";
CM_ SG_ 497 KY_HD_Entriegelung_Autorisiert "Erkennung / Authorisierung Keyless Heck
";
CM_ SG_ 497 KY_HD_Verriegelung_Autorisiert "Autorisierung der Schließanforderung über Verriegelungsinnentaster";
CM_ SG_ 497 KY_HD_Zufahrt "Zufahrt HD nach erfolgreicher Funktion EasyClose";
CM_ SG_ 497 KY_HDF_Taste "HDF Taste am Funkschluessel";
CM_ SG_ 497 KY_HFS_Entriegelung_Autorisiert "Erkennung / Authorisierung Keyless HFS
";
CM_ SG_ 497 KY_HFS_Verriegelung_Autorisiert "Authorisierung Verriegelungssensor Keyless HFS

";
CM_ SG_ 497 KY_IDG_in_Reichweite "Für elektrisch betätigte Türen und Klappen muss für eine Betätigung über Funk eine Reichweitenbegrenzung eingeführt werden. Diese Bit zeigt an, dass sich der Funkschlüssel innerhalb der geforderten Reichweite befindet";
CM_ SG_ 497 KY_LKL_1_Autorisierung "Schlüsselstatus für Anfragen der Ladeklappe 1";
CM_ SG_ 497 KY_LKL_2_Autorisierung "Schlüsselstatus für Anfragen der Ladeklappe 2";
CM_ SG_ 497 KY_Panik_Taste "Panik Taste Funkschluessel";
CM_ SG_ 497 KY_Position "Schlüsselposition für Funktionen Annäherungslicht, automatisches Entriegeln";
CM_ SG_ 497 KY_Schluessel_im_Fzg "Zeigt einen erkannten Schlüssel im Fzg an.";
CM_ SG_ 497 KY_Zu_Taste "Zu-Taste Funkschluessel";
CM_ SG_ 497 KY_ZV_Signatur "Signatur der ZV";
CM_ SG_ 497 Schluesselnr_Personalisierung "Signal gibt die jewels aktuelle Schlüsselnummer für die Personalisierung wieder";

CM_ SG_ 1424 FBS_Warn_Schluessel_Batt "Kombi Prio Warnung Schluessel Batterie
'Bitte Schlüsselbatterie wechseln!'";
CM_ SG_ 1424 KST_Wegstrecke_Challenge "Wegstreckenchallenge ans Kombi und ESC";
CM_ SG_ 1424 KY_FFB_Frequenz "Frequenz FFB";
CM_ SG_ 1424 KY_Fzg_Verlassen_erkannt "Fahrer/Schlüssel hat das Fahrzeug verlassen und FT wurde geschlossen";
CM_ SG_ 1424 KY_Fzg_Zugang_erkannt "Fahrer/Schlüssel hat Fahrzeug betreten und die FT geschlossen";
CM_ SG_ 1424 KY_HF_Aktiv "HF Funkempfang
";
CM_ SG_ 1424 KY_Indikator_Mehrere_Schluessel "Indikator für u.a. Sitzmemory, dass sich mehr als ein Schlüssel im Fahrzeug befinden.";
CM_ SG_ 1424 KY_Keyless_Go_Verbau "Verbauinfo Keyless Go
";
CM_ SG_ 1424 KY_Keyless_Verbau "Verbauinfo Keyless 
";
CM_ SG_ 1424 KY_KYL_Fahrer_Hinweise "Kombi Fahrer Hinweise Keyless";
CM_ SG_ 1424 KY_LF_Aktiv "LF Schluesselkommunikation
";
CM_ SG_ 1424 KY_NFC_Fahrer_Hinweise "Kombi Fahrer Hinweise Keyless / NFC";
CM_ SG_ 1424 KY_StartStopp_Info "Stopp-Freigabe und Start-Anforderung an den Start-Stopp-Koordinator";
CM_ SG_ 1424 KY_Transponder_aktiv "Notspule bzw, Nottransponder wird angesteuert";
CM_ SG_ 1424 KYL_Warn_kein_Schluessel "Kombi Prio Warnung Keyless 
'Schlüssel nicht im Fahrzeug!'
";
CM_ SG_ 1424 KYL_Warn_Kessy_defekt "Kombi Prio Warnung Keyless
'Keyless Go defekt, Zündschloß benutzen'";
CM_ SG_ 1424 KYL_Warn_Notzuendschloss "Aufforderung an den Benutzer, den Schlüsssel an die Notspule zu halten, wenn Kessy den Schlüssel nicht finden kann
'Keyless Go defekt. Zum Starten den Schlüssel vor das Symbol halten!'";

CM_ SG_ 2463978671 KFS_Ausgefahren "KFS ausgefahren";
CM_ SG_ 2463978671 KFS_Eingefahren "KFS ist vollständig eingefahren.";
CM_ SG_ 2463978671 KFS_Fehler_Beleuchtung "KFS Fehler Beleuchtung";

CM_ SG_ 960 BCM_Ausparken_Betrieb "Anforderung zur erneuten Lampenaufprüfung und Anzeige von Warnhinweisen nach einem pilotierten Ausparkvorgang (Trigger: fallende Flanke)";
CM_ SG_ 960 BCM_Remotestart_Betrieb "Zeigt den Status des RemoteStarts an, d.h. KL15_RSt ist aktiviert und der Motorlauf ist im RSt-Betrieb aktiv.";
CM_ SG_ 960 BCM_Remotestart_KL15_Anf "Zeigt den Status der Aktivierung der KL15_RST durch das BCM an.";
CM_ SG_ 960 BCM_Remotestart_MO_Start "Nachdem das BCM die Remotestart MSG Freigabe sicher erkannt hat, fordert das BCM wiederum über dieses Signal vom MSG einen Motorstart durchzuführen.";
CM_ SG_ 960 Klemmen_Status_01_BZ "4bit Botschaftszaehler; wird in jeder Sendebotschaft inkrementiert";
CM_ SG_ 960 Klemmen_Status_01_CRC "Für MLB:
'Berechnung siehe Lastenheft 'Kommunikationsabsicherung für FlexRay und CAN''

Ab MQB und MLBevo:
'Berechnung siehe Lastenheft 'End-to-End Kommunikationsabsicherung''

Endwerte siehe Begleitdokument 'S-PDU Kennungsfolgen'";
CM_ SG_ 960 KST_Fahrerhinweis_1 "Signalisierung Fahrerhinweis 1 der Klemmensteuerung an das Kombi";
CM_ SG_ 960 KST_Fahrerhinweis_2 "Signalisierung Fahrerhinweis 2 der Klemmensteuerung an das Kombi";
CM_ SG_ 960 KST_Fahrerhinweis_4 "Signalisierung Fahrerhinweis 4 der Klemmensteuerung an das Kombi";
CM_ SG_ 960 KST_Fahrerhinweis_5 "Anzeigesignal für RemoteStart";
CM_ SG_ 960 KST_Fahrerhinweis_6 "Signal aktiviert die Kombi-Anzeigeinstrumente (Drehzahl, Tankinhalt, Kühlmitteltemperatur) während aktiviertem RemoteStart-Betrieb";
CM_ SG_ 960 KST_Warn_P1_ZST_def "Kombi Prio Warnung Klemmensteuerung 
Zündschloß defekt, Service aufsuchen!";
CM_ SG_ 960 KST_Warn_P2_ZST_def "Kombi Prio Warnung Klemmensteuerung
Zündschloß defekt!
";
CM_ SG_ 960 RSt_Fahrerhinweise "Über das Signal fordert das BCM Fahrerhinweise im Kombi für die Funktion RemoteStart an.";
CM_ SG_ 960 ZAS_Kl_15 "Klemme 15: Zuendung (SW-Kl.15)
";
CM_ SG_ 960 ZAS_Kl_50_Startanforderung "Klemme 50: Startwunsch Fahrer
";
CM_ SG_ 960 ZAS_Kl_Infotainment "Separate Klemmeninformation für das Infotainment. Signal entspricht im wesentlichen einer Klemme S Information, kann aber über einen Vor - bzw. Nachlauf zu Klemme S verfügen. 
Ein konkreter Anwendungsfall für einen Nachlauf ist die Abschaltung der Klemme";
CM_ SG_ 960 ZAS_Kl_S "Klemme S: S-Kontakt (Schluessel steckt)
";
CM_ SG_ 960 ZAS_Kl_X "Klemme 75
";

CM_ SG_ 1420 Klemmen_Steuerung_01_BZ "4bit Botschaftszaehler; wird in jeder Sendebotschaft inkrementiert";
CM_ SG_ 1420 Klemmen_Steuerung_01_CRC "Ab MQB und MLBevo:
'Berechnung siehe Lastenheft 'End-to-End Kommunikationsabsicherung''

Endwerte siehe Begleitdokument 'S-PDU Kennungsfolgen'";
CM_ SG_ 1420 KST_Anf_Klemmenfreigabe_ELV "Klemmensteuerung fordert Klemmen-Freigabe durch die ELV an.";
CM_ SG_ 1420 KST_Anf_ZV_Verriegelung "Neuer Verriegelungstrigger für die ZV nach der automatischen Klemmenabschaltung.

Wird bei Kessyfahrzeugen mit StartStop ein aktiver Stop-Mode und Fahrerverlassen erkannt, startet ein 30 Sekunden-Timer. Innerhalb dieser 30 Sekunden hat der Fahrer die Mö";
CM_ SG_ 1420 KST_aut_Abschaltung_Zuendung "Falls bei eingeschalteter Zündung das Abblendlicht aktiv war, muss nach der automatischen Abschaltung der Kl_15 & Kl_S, dass Standlicht aktiv bleiben. Das Signal sendet die Information, dass eine automatische Abschaltung der Kl_15 und Kl_S erfogt.";
CM_ SG_ 1420 KST_Txt_Komfortabschaltung "Dieses Signal fordert im Kombi die Meldung an, die den Fahrer über die ausgeführte automatische Zündungsabschaltung informiert. Signal wird für10s gesendet.";
CM_ SG_ 1420 KST_Txt_P_Gang "Text: 'Wählhebel in Position P bringen!'";
CM_ SG_ 1420 KST_Txt_Panikabschaltung "Text: 'Notabschaltung''";
CM_ SG_ 1420 KST_Unterdr_Zuendungsmeldung "Bei aktivem Signal soll die Zündungsmeldung durch das Kombi unterdrückt werden.";
CM_ SG_ 1420 KST_ZAT_betaetigt "Zündanlass-Taster (ZAT) betätigt";
CM_ SG_ 1420 Relais_VoKo_angesteuert "Signal zur Rückmeldung, ob das Relais für die Verbraucher von erweiterte Voko / RemoteStart angesteuert wird.";
CM_ SG_ 1420 RSt_Anforderung_HMS "Anforderung vom RSt (Remote Start) an das HMS (Haltemanagement System)";

CM_ SG_ 1646 KL_Anf_AussenspiegelHzg "Anforderung Außenspiegelheizung seitens Klimafunktion (z.B. bei Erweiterter VoKo)";
CM_ SG_ 1646 KL_BCmE_Livetip_Freigabe "Status der Klimaanlage. 
Zeigt an, ob der Livetip 'Fenster schließen wegen Ineffizienz Klimaanlage' sinvollerweise angezeigt werden soll";
CM_ SG_ 1646 KL_ErwVK_Anf "Erweiterte Voko angefordertert / aktiv";
CM_ SG_ 1646 KL_ErwVK_Zusatzrelais "Steuerung Zusatzrelais für Erweiterte Voko";
CM_ SG_ 1646 KL_FSH_Automatikbetrieb "Ermöglicht eine Unterscheidung von Anforderung FSH durch Kundenwunsch und Anforderung FSH durch Regelung des Klimasteuergeräts.
Das Signal liegt als Pegel an.";
CM_ SG_ 1646 KL_Geblaese_Fond_Status "Status Geblaese









";
CM_ SG_ 1646 KL_Geblaese_Status "Status Geblaese









";
CM_ SG_ 1646 KL_Heizkreisventilstellung "Bei MQB PHEV: Stellung Heizkreisventil Motor";
CM_ SG_ 1646 KL_HYB_ASV_hinten_schliessen_Anf "Anforderung der Klima an das BMS, das Absperrventil des Kältemittelkreislaufs zur Batteriekühlung zu schliessen";
CM_ SG_ 1646 KL_HYB_ASV_vorne_schliessen_Anf "Anforderung der Klima an das BMS, das Absperrventil des Kältemittelkreislaufs der Klimaanlage zu schliessen";
CM_ SG_ 1646 KL_I_Geblaese_Fond "Stromaufnahme Gebläse Heck";
CM_ SG_ 1646 KL_Innen_Temp "Innentemperatur

";
CM_ SG_ 1646 KL_Kompressorkupplung "Signal zur Aktivierung/Deaktivierung der Kompressorkupplung";
CM_ SG_ 1646 KL_Magnetventil "Anforderung des Bypassventils.";
CM_ SG_ 1646 KL_Restwaerme_aktiv "Signal zur Aktivierung/Deaktivierung der Wasserpumpe bei Restwärme; 
reduzierte IRÜ Empfindlichkeit";
CM_ SG_ 1646 KL_SIH_LEH_Verteilung_VL "Vom Kunden eingestellte Aufteilung der Heizleistung auf Sitzfläche und Lehnefläche für Sitz vorne links";
CM_ SG_ 1646 KL_SIH_LEH_Verteilung_VR "Vom Kunden eingestellte Aufteilung der Heizleistung auf Sitzfläche und Lehnefläche für Sitz vorne rechts";
CM_ SG_ 1646 KL_SIH_LEL_Verteilung_VL "Vom Kunden eingestellte Aufteilung der Lüftungsleistung auf Sitzfläche und Lehnenfläche für Sitz vorne links";
CM_ SG_ 1646 KL_SIH_LEL_Verteilung_VR "Vom Kunden eingestellte Aufteilung der Lüftungsleistung auf Sitzfläche und Lehnenfläche für Sitz vorne rechts";
CM_ SG_ 1646 KL_Solarluefter_aktiv "Betriebsstatus Solarluefter
";
CM_ SG_ 1646 KL_Status_Beduftung "Status der Beduftung";
CM_ SG_ 1646 KL_Status_Ionisator_Front "Status des Ionisator Front";
CM_ SG_ 1646 KL_STH_aktiv "Betriebsstatus Standheizung
";
CM_ SG_ 1646 KL_STH_Ansteuerung "Ansteuerung STH

";
CM_ SG_ 1646 KL_STH_Betriebsdauer "Betriebsdauer STH";
CM_ SG_ 1646 KL_STH_Timer_Status "Status des Standheizungstimers (für VW621 initial zur Übermittelung der Information von KlimaMSB zu Kombi)
Zur Anzeige im Kombi für 10 Sekunden nach Kl.15 aus;";
CM_ SG_ 1646 KL_STL_aktiv "Betriebsstatus Standlueftung
";
CM_ SG_ 1646 KL_Umluft_Taste "Betaetigung Umlufttaste
";
CM_ SG_ 1646 KL_WaPu "Ansteuerung der Standheizungswasserpumpe";

CM_ SG_ 1663 KL_Absperrventil_Fond "nur im D4 verwendet";
CM_ SG_ 1663 KL_Fond_li_reduziert "Vorhalt fuer VW, nicht B8";
CM_ SG_ 1663 KL_Fond_re_reduziert "Vorhalt fuer VW, nicht B8";
CM_ SG_ 1663 KL_Fondbed_vorne_aktiv "Fondbedienung von vorne
Im D4 nicht unterstützt    siehe Klima_07, Synchronisierunganforderung
";
CM_ SG_ 1663 KL_Gebl_Verst_Abs_Modus "Gebläseverstellung im Absolutmodus";
CM_ SG_ 1663 KL_Geblaesespg_Fond "Geläsespannung Fond";
CM_ SG_ 1663 KL_Heizverbraucher_aus "Signal ans Fondgerät, alle Heizverbraucher zu deaktivieren";
CM_ SG_ 1663 KL_Heizverbraucher_Notaus "Signal ans Fondgerät, alle Heizverbraucher zu deaktivieren";
CM_ SG_ 1663 KL_ICO2_Sensor_defekt "Funktionszustand vom CO2 Sensor";
CM_ SG_ 1663 KL_Mod_Display_li "Modus des Display links";
CM_ SG_ 1663 KL_Mod_Display_re "Modus des Display rechts
";
CM_ SG_ 1663 KL_SH_HL_Lastabschaltung "Abschaltung der Sitzheizung hinten links wegen BEM, auch Taktung möglich
";
CM_ SG_ 1663 KL_SH_HR_Lastabschaltung "Abschaltung der Sitzheizung hinten rechts wegen BEM, auch Taktung möglich
";
CM_ SG_ 1663 KL_Sollausblastemp_HL "Sollausblastemperatur hinten links (0°C .. 85°C)

Vorhalt";
CM_ SG_ 1663 KL_Sollausblastemp_HR "Sollausblastemperatur hinten rechts (0°C .. 85°C)

Vorhalt";
CM_ SG_ 1663 KL_Umluft "Sollwert für Umluftklappe Fondraum";
BA_DEF_REL_ BU_SG_REL_  "GenSigTimeoutTime" INT 0 65535;
BA_DEF_ BO_  "DiagRequest" ENUM "No", "Yes";
BA_DEF_ BO_  "DiagResponse" ENUM "No", "Yes";
BA_DEF_ BO_  "DiagState" ENUM "No", "Yes";
BA_DEF_ BO_  "GenMsgChkConstant" HEX 0 4095;
BA_DEF_ BO_  "GenMsgCycleTime" INT 0 65535;
BA_DEF_ BO_  "GenMsgCycleTimeFast" INT 0 65535;
BA_DEF_ BO_  "GenMsgDelayTime" INT 0 100000;
BA_DEF_ BO_  "GenMsgILSupport" ENUM "No", "Yes";
BA_DEF_ BO_  "GenMsgNrOfRepetition" INT 0 100;
BA_DEF_ BO_  "GenMsgPDUConstants" STRING;
BA_DEF_ BO_  "GenMsgSendType" ENUM "Cyclic", "not_used", "not_used", "not_used", "not_used", "not_used", "not_used", "IfActive", "NoMsgSendType";
BA_DEF_ BO_  "GenMsgStartDelayTime" INT 0 100000;
BA_DEF_ BO_  "NmMessage" ENUM "No", "Yes";
BA_DEF_ BO_  "NmhMessage" ENUM "No", "Yes";
BA_DEF_ BO_  "MsgType" ENUM "Application", "NM ", "NMH", "TP2.0", "ISO-TP ", "BAP", "EID", "KS", "XCP_PRE_CONFIGURED", "XCP_RUNTIME_CONFIGURED";
BA_DEF_ BO_  "VAGTP20_API" HEX 0 255;
BA_DEF_ BO_  "VAGTP20_DynConnection" ENUM "No", "Yes";
BA_DEF_ BO_  "VAGTP20_DynSetup" ENUM "No", "Yes";
BA_DEF_ BO_  "VAGTP20_StatConnection" ENUM "No", "Yes";
BA_DEF_ SG_  "GenSigActiveRepetitions" INT -2147483648 2147483647;
BA_DEF_ SG_  "GenSigInactiveValue" INT -2147483648 2147483647;
BA_DEF_ SG_  "GenSigSendType" ENUM "Cyclic", "OnWrite", "OnWriteWithRepetition", "OnChange", "OnChangeWithRepetition", "IfActive", "IfActiveWithRepetition", "NoSigSendType", "OnChangeAndIfActive", "OnChangeAndIfActiveWithRepetition";
BA_DEF_ SG_  "GenSigStartValue" INT -2147483648 2147483647;
BA_DEF_ SG_  "NWM-WakeupAllowed" ENUM "No", "Yes";
BA_DEF_ SG_  "GenSigFuncType" ENUM "NoFunction", "MsgCounter", "CRC-8", "XOR", "XOR-2", "DatedBit", "SW-Kl15", "CHK", "Constant", "Protocol", "CRC-8-SAE_J1850", "CRC-32", "DataLength", "DataID", "MsgCounter16", "SOK-Signatur", "Cluster";
BA_DEF_ SG_  "GenSigSwitchedByIgnition" ENUM "No", "Yes";
BA_DEF_ SG_  "Fehlerwert" HEX 0 2147483647;
BA_DEF_ SG_  "GenSigMissingSourceValue" HEX 0 2147483647;
BA_DEF_DEF_REL_  "GenSigTimeoutTime" 0;
BA_DEF_DEF_  "DiagRequest" "No";
BA_DEF_DEF_  "DiagResponse" "No";
BA_DEF_DEF_  "DiagState" "No";
BA_DEF_DEF_  "GenMsgChkConstant" 0;
BA_DEF_DEF_  "GenMsgCycleTime" 0;
BA_DEF_DEF_  "GenMsgCycleTimeFast" 0;
BA_DEF_DEF_  "GenMsgDelayTime" 0;
BA_DEF_DEF_  "GenMsgILSupport" "No";
BA_DEF_DEF_  "GenMsgNrOfRepetition" 0;
BA_DEF_DEF_  "GenMsgPDUConstants" "";
BA_DEF_DEF_  "GenMsgSendType" "NoMsgSendType";
BA_DEF_DEF_  "GenMsgStartDelayTime" 0;
BA_DEF_DEF_  "NmMessage" "No";
BA_DEF_DEF_  "NmhMessage" "No";
BA_DEF_DEF_  "MsgType" "Application";
BA_DEF_DEF_  "VAGTP20_API" 0;
BA_DEF_DEF_  "VAGTP20_DynConnection" "No";
BA_DEF_DEF_  "VAGTP20_DynSetup" "No";
BA_DEF_DEF_  "VAGTP20_StatConnection" "No";
BA_DEF_DEF_  "GenSigActiveRepetitions" 0;
BA_DEF_DEF_  "GenSigInactiveValue" 0;
BA_DEF_DEF_  "GenSigSendType" "NoSigSendType";
BA_DEF_DEF_  "GenSigStartValue" 0;
BA_DEF_DEF_  "NWM-WakeupAllowed" "No";
BA_DEF_DEF_  "GenSigFuncType" "NoFunction";
BA_DEF_DEF_  "GenSigSwitchedByIgnition" "Yes";
BA_DEF_DEF_  "Fehlerwert" 0;
BA_DEF_DEF_  "GenSigMissingSourceValue" 0;
BA_ "GenMsgCycleTime" BO_ 379 100;
BA_ "GenMsgDelayTime" BO_ 379 10;
BA_ "GenMsgILSupport" BO_ 379 1;
BA_ "GenMsgPDUConstants" BO_ 379 "0xfb,0xb3,0xc7,0x5d,0xcc,0xd6,0xfa,0x30,0x26,0x27,0x4e,0x3d,0xc9,0x0e,0x0c,0xa5";
BA_ "GenMsgSendType" BO_ 379 0;
BA_ "GenMsgCycleTime" BO_ 2463978770 100;
BA_ "GenMsgILSupport" BO_ 2463978770 1;
BA_ "GenMsgSendType" BO_ 2463978770 0;
BA_ "GenMsgCycleTime" BO_ 606 50;
BA_ "GenMsgILSupport" BO_ 606 1;
BA_ "GenMsgSendType" BO_ 606 0;
BA_ "GenMsgCycleTime" BO_ 607 50;
BA_ "GenMsgILSupport" BO_ 607 1;
BA_ "GenMsgSendType" BO_ 607 0;
BA_ "GenMsgCycleTime" BO_ 707 80;
BA_ "GenMsgILSupport" BO_ 707 1;
BA_ "GenMsgPDUConstants" BO_ 707 "0x4e,0xc0,0xa1,0x90,0xc4,0xb0,0xe7,0x7d,0xdb,0x1e,0x6f,0x69,0xac,0x73,0x9c,0x17";
BA_ "GenMsgSendType" BO_ 707 0;
BA_ "GenMsgCycleTime" BO_ 2589283684 960;
BA_ "GenMsgDelayTime" BO_ 2589283684 320;
BA_ "GenMsgILSupport" BO_ 2589283684 1;
BA_ "GenMsgSendType" BO_ 2589283684 0;
BA_ "GenMsgStartDelayTime" BO_ 2589283684 320;
BA_ "GenMsgILSupport" BO_ 2549875476 1;
BA_ "MsgType" BO_ 2549875476 4;
BA_ "GenMsgILSupport" BO_ 2550006548 1;
BA_ "MsgType" BO_ 2550006548 4;
BA_ "GenMsgCycleTime" BO_ 2463978599 1000;
BA_ "GenMsgDelayTime" BO_ 2463978599 40;
BA_ "GenMsgILSupport" BO_ 2463978599 1;
BA_ "GenMsgSendType" BO_ 2463978599 0;
BA_ "GenMsgStartDelayTime" BO_ 2463978599 70;
BA_ "GenMsgCycleTime" BO_ 968 200;
BA_ "GenMsgILSupport" BO_ 968 1;
BA_ "GenMsgSendType" BO_ 968 0;
BA_ "GenMsgChkConstant" BO_ 324 227;
BA_ "GenMsgCycleTime" BO_ 324 20;
BA_ "GenMsgILSupport" BO_ 324 1;
BA_ "GenMsgPDUConstants" BO_ 324 "0xe3,0xe3,0xe3,0xe3,0xe3,0xe3,0xe3,0xe3,0xe3,0xe3,0xe3,0xe3,0xe3,0xe3,0xe3,0xe3";
BA_ "GenMsgSendType" BO_ 324 0;
BA_ "GenMsgCycleTime" BO_ 299 200;
BA_ "GenMsgDelayTime" BO_ 299 20;
BA_ "GenMsgILSupport" BO_ 299 1;
BA_ "GenMsgPDUConstants" BO_ 299 "0x6a,0x38,0xb4,0x27,0x22,0xef,0xe1,0xbb,0xf8,0x80,0x84,0x49,0xc7,0x9e,0x1e,0x2b";
BA_ "GenMsgSendType" BO_ 299 0;
BA_ "GenMsgChkConstant" BO_ 310 55;
BA_ "GenMsgCycleTime" BO_ 310 100;
BA_ "GenMsgDelayTime" BO_ 310 10;
BA_ "GenMsgILSupport" BO_ 310 1;
BA_ "GenMsgPDUConstants" BO_ 310 "0x37,0x37,0x37,0x37,0x37,0x37,0x37,0x37,0x37,0x37,0x37,0x37,0x37,0x37,0x37,0x37";
BA_ "GenMsgSendType" BO_ 310 0;
BA_ "GenMsgChkConstant" BO_ 1412 127;
BA_ "GenMsgCycleTime" BO_ 1412 200;
BA_ "GenMsgILSupport" BO_ 1412 1;
BA_ "GenMsgPDUConstants" BO_ 1412 "0x7f,0x7f,0x7f,0x7f,0x7f,0x7f,0x7f,0x7f,0x7f,0x7f,0x7f,0x7f,0x7f,0x7f,0x7f,0x7f";
BA_ "GenMsgSendType" BO_ 1412 0;
BA_ "GenMsgCycleTime" BO_ 1609 1000;
BA_ "GenMsgDelayTime" BO_ 1609 100;
BA_ "GenMsgILSupport" BO_ 1609 1;
BA_ "GenMsgSendType" BO_ 1609 0;
BA_ "GenMsgCycleTime" BO_ 1283 100;
BA_ "GenMsgDelayTime" BO_ 1283 10;
BA_ "GenMsgILSupport" BO_ 1283 1;
BA_ "GenMsgPDUConstants" BO_ 1283 "0xed,0xd6,0x96,0x63,0xa5,0x12,0xd5,0x9a,0x1e,0x0d,0x24,0xcd,0x8c,0xa6,0x2f,0x41";
BA_ "GenMsgSendType" BO_ 1283 0;
BA_ "GenMsgStartDelayTime" BO_ 1283 10;
BA_ "GenMsgCycleTime" BO_ 1381 500;
BA_ "GenMsgDelayTime" BO_ 1381 50;
BA_ "GenMsgILSupport" BO_ 1381 1;
BA_ "GenMsgSendType" BO_ 1381 0;
BA_ "GenMsgCycleTime" BO_ 312 200;
BA_ "GenMsgDelayTime" BO_ 312 20;
BA_ "GenMsgILSupport" BO_ 312 1;
BA_ "GenMsgPDUConstants" BO_ 312 "0x77,0x4e,0x14,0x87,0xf2,0xf8,0xb2,0x61,0xf6,0xa4,0x52,0x94,0xd4,0x81,0x2a,0xb1";
BA_ "GenMsgSendType" BO_ 312 0;
BA_ "DiagState" BO_ 1792 1;
BA_ "MsgType" BO_ 1792 4;
BA_ "DiagRequest" BO_ 1819 1;
BA_ "MsgType" BO_ 1819 4;
BA_ "DiagResponse" BO_ 1925 1;
BA_ "MsgType" BO_ 1925 4;
BA_ "DiagRequest" BO_ 1812 1;
BA_ "MsgType" BO_ 1812 4;
BA_ "DiagResponse" BO_ 1918 1;
BA_ "MsgType" BO_ 1918 4;
BA_ "DiagRequest" BO_ 1875 1;
BA_ "MsgType" BO_ 1875 4;
BA_ "DiagResponse" BO_ 1981 1;
BA_ "MsgType" BO_ 1981 4;
BA_ "GenMsgCycleTime" BO_ 2463978614 200;
BA_ "GenMsgDelayTime" BO_ 2463978614 20;
BA_ "GenMsgILSupport" BO_ 2463978614 1;
BA_ "GenMsgSendType" BO_ 2463978614 0;
BA_ "GenMsgCycleTime" BO_ 497 500;
BA_ "GenMsgCycleTimeFast" BO_ 497 40;
BA_ "GenMsgDelayTime" BO_ 497 20;
BA_ "GenMsgILSupport" BO_ 497 1;
BA_ "GenMsgNrOfRepetition" BO_ 497 7;
BA_ "GenMsgSendType" BO_ 497 0;
BA_ "GenMsgCycleTime" BO_ 1424 200;
BA_ "GenMsgDelayTime" BO_ 1424 50;
BA_ "GenMsgILSupport" BO_ 1424 1;
BA_ "GenMsgSendType" BO_ 1424 0;
BA_ "GenMsgCycleTime" BO_ 2463978671 200;
BA_ "GenMsgDelayTime" BO_ 2463978671 50;
BA_ "GenMsgILSupport" BO_ 2463978671 1;
BA_ "GenMsgSendType" BO_ 2463978671 0;
BA_ "GenMsgChkConstant" BO_ 960 195;
BA_ "GenMsgCycleTime" BO_ 960 100;
BA_ "GenMsgDelayTime" BO_ 960 10;
BA_ "GenMsgILSupport" BO_ 960 1;
BA_ "GenMsgPDUConstants" BO_ 960 "0xc3,0xc3,0xc3,0xc3,0xc3,0xc3,0xc3,0xc3,0xc3,0xc3,0xc3,0xc3,0xc3,0xc3,0xc3,0xc3";
BA_ "GenMsgSendType" BO_ 960 0;
BA_ "GenMsgCycleTime" BO_ 1420 1000;
BA_ "GenMsgCycleTimeFast" BO_ 1420 100;
BA_ "GenMsgDelayTime" BO_ 1420 50;
BA_ "GenMsgILSupport" BO_ 1420 1;
BA_ "GenMsgNrOfRepetition" BO_ 1420 3;
BA_ "GenMsgPDUConstants" BO_ 1420 "0x9b,0xb5,0x9d,0x06,0x01,0xe7,0x8f,0xc1,0xd0,0x10,0x47,0xe9,0xd3,0xca,0x05,0xf0";
BA_ "GenMsgSendType" BO_ 1420 0;
BA_ "GenMsgCycleTime" BO_ 1646 2000;
BA_ "GenMsgDelayTime" BO_ 1646 200;
BA_ "GenMsgILSupport" BO_ 1646 1;
BA_ "GenMsgSendType" BO_ 1646 0;
BA_ "GenMsgCycleTime" BO_ 1663 1000;
BA_ "GenMsgDelayTime" BO_ 1663 50;
BA_ "GenMsgILSupport" BO_ 1663 1;
BA_ "GenMsgSendType" BO_ 1663 0;
BA_ "GenSigSendType" SG_ 379 FCU_02_BZ 0;
BA_ "GenSigFuncType" SG_ 379 FCU_02_BZ 1;
BA_ "GenSigSwitchedByIgnition" SG_ 379 FCU_02_BZ 0;
BA_ "GenSigSendType" SG_ 379 FCU_02_CRC 0;
BA_ "GenSigFuncType" SG_ 379 FCU_02_CRC 2;
BA_ "GenSigSwitchedByIgnition" SG_ 379 FCU_02_CRC 0;
BA_ "GenSigSendType" SG_ 379 FCU_Absperrventil_schliessen 0;
BA_ "GenSigSwitchedByIgnition" SG_ 379 FCU_Absperrventil_schliessen 0;
BA_ "GenSigSendType" SG_ 379 FCU_Fehler_Abschaltanforderung 3;
BA_ "GenSigSwitchedByIgnition" SG_ 379 FCU_Fehler_Abschaltanforderung 0;
BA_ "Fehlerwert" SG_ 379 FCU_Fehler_Abschaltanforderung 1;
BA_ "GenSigSendType" SG_ 379 FCU_Fehler_Entladung_defekt 3;
BA_ "GenSigStartValue" SG_ 379 FCU_Fehler_Entladung_defekt 3;
BA_ "GenSigSwitchedByIgnition" SG_ 379 FCU_Fehler_Entladung_defekt 0;
BA_ "Fehlerwert" SG_ 379 FCU_Fehler_Entladung_defekt 1;
BA_ "GenSigSendType" SG_ 379 FCU_Fehler_Isofehler_I 3;
BA_ "GenSigStartValue" SG_ 379 FCU_Fehler_Isofehler_I 3;
BA_ "GenSigSwitchedByIgnition" SG_ 379 FCU_Fehler_Isofehler_I 0;
BA_ "GenSigSendType" SG_ 379 FCU_Fehler_Isofehler_II 3;
BA_ "GenSigStartValue" SG_ 379 FCU_Fehler_Isofehler_II 3;
BA_ "GenSigSwitchedByIgnition" SG_ 379 FCU_Fehler_Isofehler_II 0;
BA_ "GenSigSendType" SG_ 379 FCU_Fehler_Leistungsreduzierung 3;
BA_ "GenSigSwitchedByIgnition" SG_ 379 FCU_Fehler_Leistungsreduzierung 0;
BA_ "Fehlerwert" SG_ 379 FCU_Fehler_Leistungsreduzierung 1;
BA_ "GenSigSendType" SG_ 379 FCU_Fehler_Notabschaltung 3;
BA_ "GenSigSwitchedByIgnition" SG_ 379 FCU_Fehler_Notabschaltung 0;
BA_ "Fehlerwert" SG_ 379 FCU_Fehler_Notabschaltung 1;
BA_ "GenSigSendType" SG_ 379 FCU_HV_Anf 0;
BA_ "GenSigSwitchedByIgnition" SG_ 379 FCU_HV_Anf 0;
BA_ "Fehlerwert" SG_ 379 FCU_HV_Anf 3;
BA_ "GenSigSendType" SG_ 379 FCU_Ionenspuelung_aktiv 3;
BA_ "GenSigSwitchedByIgnition" SG_ 379 FCU_Ionenspuelung_aktiv 0;
BA_ "GenSigSendType" SG_ 379 FCU_IstModus 3;
BA_ "GenSigStartValue" SG_ 379 FCU_IstModus 31;
BA_ "GenSigSwitchedByIgnition" SG_ 379 FCU_IstModus 0;
BA_ "GenSigSendType" SG_ 379 FCU_Klima_Eingr 3;
BA_ "GenSigSwitchedByIgnition" SG_ 379 FCU_Klima_Eingr 0;
BA_ "GenSigSendType" SG_ 379 FCU_MinAbs_Leistung 0;
BA_ "GenSigStartValue" SG_ 379 FCU_MinAbs_Leistung 1023;
BA_ "GenSigSwitchedByIgnition" SG_ 379 FCU_MinAbs_Leistung 0;
BA_ "GenSigSendType" SG_ 379 FCU_nicht_verfuegbar 3;
BA_ "GenSigSwitchedByIgnition" SG_ 379 FCU_nicht_verfuegbar 0;
BA_ "GenSigSendType" SG_ 379 FCU_OBD_Lampe_Anf 0;
BA_ "GenSigSwitchedByIgnition" SG_ 379 FCU_OBD_Lampe_Anf 0;
BA_ "GenSigSendType" SG_ 379 FCU_Startstopp_Anforderung 3;
BA_ "GenSigSwitchedByIgnition" SG_ 379 FCU_Startstopp_Anforderung 0;
BA_ "GenSigSendType" SG_ 379 FCU_Status_Spgfreiheit 3;
BA_ "GenSigSwitchedByIgnition" SG_ 379 FCU_Status_Spgfreiheit 0;
BA_ "GenSigSendType" SG_ 379 FCU_TK_Betankung_Anforderung 0;
BA_ "GenSigSwitchedByIgnition" SG_ 379 FCU_TK_Betankung_Anforderung 0;
BA_ "GenSigSendType" SG_ 379 FCU_TK_Freigabe_Tankklappe 0;
BA_ "GenSigSwitchedByIgnition" SG_ 379 FCU_TK_Freigabe_Tankklappe 0;
BA_ "Fehlerwert" SG_ 379 FCU_TK_Freigabe_Tankklappe 15;
BA_ "GenSigSendType" SG_ 379 FCU_Warn_H2_Konzentrat_Motorraum 0;
BA_ "GenSigSwitchedByIgnition" SG_ 379 FCU_Warn_H2_Konzentrat_Motorraum 0;
BA_ "GenSigSendType" SG_ 2463978770 FCU_TK_H2_Fuellstand 0;
BA_ "GenSigStartValue" SG_ 2463978770 FCU_TK_H2_Fuellstand 510;
BA_ "GenSigSwitchedByIgnition" SG_ 2463978770 FCU_TK_H2_Fuellstand 0;
BA_ "Fehlerwert" SG_ 2463978770 FCU_TK_H2_Fuellstand 511;
BA_ "GenSigSendType" SG_ 2463978770 FCU_TK_H2_Nachtanken_aktiv 0;
BA_ "GenSigSwitchedByIgnition" SG_ 2463978770 FCU_TK_H2_Nachtanken_aktiv 0;
BA_ "Fehlerwert" SG_ 2463978770 FCU_TK_H2_Nachtanken_aktiv 3;
BA_ "GenSigSendType" SG_ 2463978770 FCU_TK_Meldungen 0;
BA_ "GenSigSwitchedByIgnition" SG_ 2463978770 FCU_TK_Meldungen 0;
BA_ "Fehlerwert" SG_ 2463978770 FCU_TK_Meldungen 7;
BA_ "GenSigSendType" SG_ 2463978770 FCU_TK_Tankwarnungen 0;
BA_ "GenSigSwitchedByIgnition" SG_ 2463978770 FCU_TK_Tankwarnungen 0;
BA_ "Fehlerwert" SG_ 2463978770 FCU_TK_Tankwarnungen 7;
BA_ "GenSigSendType" SG_ 2463978770 FCU_TK_Wasserstoffmasse_Netto 0;
BA_ "GenSigSwitchedByIgnition" SG_ 2463978770 FCU_TK_Wasserstoffmasse_Netto 0;
BA_ "GenSigSendType" SG_ 606 FCU_Energieaequivalent 0;
BA_ "GenSigStartValue" SG_ 606 FCU_Energieaequivalent 4095;
BA_ "GenSigSwitchedByIgnition" SG_ 606 FCU_Energieaequivalent 0;
BA_ "GenSigSendType" SG_ 606 FCU_Verbrauch_FC 0;
BA_ "GenSigSwitchedByIgnition" SG_ 606 FCU_Verbrauch_FC 0;
BA_ "GenSigSendType" SG_ 606 FCU_Verbrauch_FC_Nebag 0;
BA_ "GenSigSwitchedByIgnition" SG_ 606 FCU_Verbrauch_FC_Nebag 0;
BA_ "GenSigSendType" SG_ 606 FCU_Verbrauch_FC_Nebag_Ueberlauf 0;
BA_ "GenSigSwitchedByIgnition" SG_ 606 FCU_Verbrauch_FC_Nebag_Ueberlauf 0;
BA_ "GenSigSendType" SG_ 606 FCU_Verbrauch_FC_Ueberlauf 0;
BA_ "GenSigSwitchedByIgnition" SG_ 606 FCU_Verbrauch_FC_Ueberlauf 0;
BA_ "GenSigSendType" SG_ 606 FCU_Verbrauch_H2 0;
BA_ "GenSigSwitchedByIgnition" SG_ 606 FCU_Verbrauch_H2 0;
BA_ "GenSigSendType" SG_ 606 FCU_Verbrauch_H2_Ueberlauf 0;
BA_ "GenSigSwitchedByIgnition" SG_ 606 FCU_Verbrauch_H2_Ueberlauf 0;
BA_ "GenSigSendType" SG_ 607 FCU_Anzeigeverbrauch_H2 0;
BA_ "GenSigSwitchedByIgnition" SG_ 607 FCU_Anzeigeverbrauch_H2 0;
BA_ "GenSigSendType" SG_ 607 FCU_TK_Fuellstand 0;
BA_ "GenSigStartValue" SG_ 607 FCU_TK_Fuellstand 510;
BA_ "GenSigSwitchedByIgnition" SG_ 607 FCU_TK_Fuellstand 0;
BA_ "Fehlerwert" SG_ 607 FCU_TK_Fuellstand 511;
BA_ "GenSigSendType" SG_ 607 FCU_TK_Wasserstoffmasse_Tank 0;
BA_ "GenSigStartValue" SG_ 607 FCU_TK_Wasserstoffmasse_Tank 1022;
BA_ "GenSigSwitchedByIgnition" SG_ 607 FCU_TK_Wasserstoffmasse_Tank 0;
BA_ "Fehlerwert" SG_ 607 FCU_TK_Wasserstoffmasse_Tank 1023;
BA_ "GenSigSendType" SG_ 607 FCU_Verb_FC_Nebag_Masaequi 0;
BA_ "GenSigSwitchedByIgnition" SG_ 607 FCU_Verb_FC_Nebag_Masaequi 0;
BA_ "GenSigSendType" SG_ 607 FCU_Verb_FC_Nebag_Masaequi_Ueb 0;
BA_ "GenSigSwitchedByIgnition" SG_ 607 FCU_Verb_FC_Nebag_Masaequi_Ueb 0;
BA_ "GenSigSendType" SG_ 707 eAWS_Warnmeldung_Prio3 0;
BA_ "GenSigSwitchedByIgnition" SG_ 707 eAWS_Warnmeldung_Prio3 0;
BA_ "GenSigSendType" SG_ 707 EFP_Anf_Kuehlklappenwarnung 0;
BA_ "GenSigSwitchedByIgnition" SG_ 707 EFP_Anf_Kuehlklappenwarnung 0;
BA_ "GenSigSendType" SG_ 707 EFP_MomRad_Begr 0;
BA_ "GenSigStartValue" SG_ 707 EFP_MomRad_Begr 4094;
BA_ "GenSigSwitchedByIgnition" SG_ 707 EFP_MomRad_Begr 0;
BA_ "Fehlerwert" SG_ 707 EFP_MomRad_Begr 4095;
BA_ "GenSigSendType" SG_ 707 FA_Warnung_Transportniveau 0;
BA_ "GenSigSwitchedByIgnition" SG_ 707 FA_Warnung_Transportniveau 0;
BA_ "GenSigSendType" SG_ 707 FDR_04_BZ 0;
BA_ "GenSigFuncType" SG_ 707 FDR_04_BZ 1;
BA_ "GenSigSwitchedByIgnition" SG_ 707 FDR_04_BZ 0;
BA_ "GenSigSendType" SG_ 707 FDR_04_CRC 0;
BA_ "GenSigFuncType" SG_ 707 FDR_04_CRC 2;
BA_ "GenSigSwitchedByIgnition" SG_ 707 FDR_04_CRC 0;
BA_ "GenSigSendType" SG_ 707 FDR_M_HL_02 0;
BA_ "GenSigStartValue" SG_ 707 FDR_M_HL_02 254;
BA_ "GenSigSwitchedByIgnition" SG_ 707 FDR_M_HL_02 0;
BA_ "Fehlerwert" SG_ 707 FDR_M_HL_02 255;
BA_ "GenSigSendType" SG_ 707 FDR_M_HR_02 0;
BA_ "GenSigStartValue" SG_ 707 FDR_M_HR_02 254;
BA_ "GenSigSwitchedByIgnition" SG_ 707 FDR_M_HR_02 0;
BA_ "Fehlerwert" SG_ 707 FDR_M_HR_02 255;
BA_ "GenSigSendType" SG_ 707 FDR_M_VL_02 0;
BA_ "GenSigStartValue" SG_ 707 FDR_M_VL_02 254;
BA_ "GenSigSwitchedByIgnition" SG_ 707 FDR_M_VL_02 0;
BA_ "Fehlerwert" SG_ 707 FDR_M_VL_02 255;
BA_ "GenSigSendType" SG_ 707 FDR_M_VR_02 0;
BA_ "GenSigStartValue" SG_ 707 FDR_M_VR_02 254;
BA_ "GenSigSwitchedByIgnition" SG_ 707 FDR_M_VR_02 0;
BA_ "Fehlerwert" SG_ 707 FDR_M_VR_02 255;
BA_ "GenSigSendType" SG_ 2589283684 FoD_Anz_Funktionsabschaltung 3;
BA_ "GenSigSwitchedByIgnition" SG_ 2589283684 FoD_Anz_Funktionsabschaltung 0;
BA_ "GenSigSendType" SG_ 2589283684 FoD_Transmission_Info 3;
BA_ "GenSigSwitchedByIgnition" SG_ 2589283684 FoD_Transmission_Info 0;
BA_ "GenSigSendType" SG_ 2549875476 FoD_Kombi_Req_Data 3;
BA_ "GenSigFuncType" SG_ 2549875476 FoD_Kombi_Req_Data 9;
BA_ "GenSigSwitchedByIgnition" SG_ 2549875476 FoD_Kombi_Req_Data 0;
BA_ "GenSigSendType" SG_ 2550006548 FoD_Kombi_Resp_Data 3;
BA_ "GenSigFuncType" SG_ 2550006548 FoD_Kombi_Resp_Data 9;
BA_ "GenSigSwitchedByIgnition" SG_ 2550006548 FoD_Kombi_Resp_Data 0;
BA_ "GenSigSendType" SG_ 2463978599 MKE_Anpassung_FZ 3;
BA_ "GenSigSwitchedByIgnition" SG_ 2463978599 MKE_Anpassung_FZ 0;
BA_ "Fehlerwert" SG_ 2463978599 MKE_Anpassung_FZ 65535;
BA_ "GenSigSendType" SG_ 2463978599 MKE_Fahrzeit 0;
BA_ "GenSigSwitchedByIgnition" SG_ 2463978599 MKE_Fahrzeit 0;
BA_ "GenSigSendType" SG_ 968 Freilauf_Charisma_FahrPr 0;
BA_ "GenSigSwitchedByIgnition" SG_ 968 Freilauf_Charisma_FahrPr 0;
BA_ "GenSigSendType" SG_ 968 Freilauf_Charisma_Status 0;
BA_ "GenSigSwitchedByIgnition" SG_ 968 Freilauf_Charisma_Status 0;
BA_ "GenSigSendType" SG_ 968 GE_amax_moeglich 0;
BA_ "GenSigStartValue" SG_ 968 GE_amax_moeglich 84;
BA_ "GenSigSwitchedByIgnition" SG_ 968 GE_amax_moeglich 0;
BA_ "GenSigSendType" SG_ 968 GE_Charisma_FahrPr 0;
BA_ "GenSigSwitchedByIgnition" SG_ 968 GE_Charisma_FahrPr 0;
BA_ "GenSigSendType" SG_ 968 GE_Charisma_Status 0;
BA_ "GenSigSwitchedByIgnition" SG_ 968 GE_Charisma_Status 0;
BA_ "GenSigSendType" SG_ 968 GE_Codierung_MSG 0;
BA_ "GenSigSwitchedByIgnition" SG_ 968 GE_Codierung_MSG 0;
BA_ "GenSigSendType" SG_ 968 GE_Freigabe_Info_WFS 0;
BA_ "GenSigSwitchedByIgnition" SG_ 968 GE_Freigabe_Info_WFS 0;
BA_ "GenSigSendType" SG_ 968 GE_Freigabe_Verfallsinfo_WFS 0;
BA_ "GenSigSwitchedByIgnition" SG_ 968 GE_Freigabe_Verfallsinfo_WFS 0;
BA_ "GenSigSendType" SG_ 968 GE_Heizwunsch 0;
BA_ "GenSigStartValue" SG_ 968 GE_Heizwunsch 1;
BA_ "GenSigSwitchedByIgnition" SG_ 968 GE_Heizwunsch 0;
BA_ "GenSigSendType" SG_ 968 GE_LaunchControl 0;
BA_ "GenSigSwitchedByIgnition" SG_ 968 GE_LaunchControl 0;
BA_ "GenSigSendType" SG_ 968 GE_LaunchControl_LB 0;
BA_ "GenSigSwitchedByIgnition" SG_ 968 GE_LaunchControl_LB 0;
BA_ "GenSigSendType" SG_ 968 GE_LFR_Adaption 0;
BA_ "GenSigSwitchedByIgnition" SG_ 968 GE_LFR_Adaption 0;
BA_ "GenSigSendType" SG_ 968 GE_OBD_AbsperrVent 0;
BA_ "GenSigSwitchedByIgnition" SG_ 968 GE_OBD_AbsperrVent 0;
BA_ "GenSigSendType" SG_ 968 GE_OBD_Status 0;
BA_ "GenSigSwitchedByIgnition" SG_ 968 GE_OBD_Status 0;
BA_ "GenSigSendType" SG_ 968 GE_Remotestart_Betrieb 0;
BA_ "GenSigSwitchedByIgnition" SG_ 968 GE_Remotestart_Betrieb 0;
BA_ "GenSigSendType" SG_ 968 GE_Sperr_Info_WFS 0;
BA_ "GenSigSwitchedByIgnition" SG_ 968 GE_Sperr_Info_WFS 0;
BA_ "GenSigSendType" SG_ 968 GE_Status_PaddleNeutral 0;
BA_ "GenSigSwitchedByIgnition" SG_ 968 GE_Status_PaddleNeutral 0;
BA_ "GenSigSendType" SG_ 968 GE_Sumpftemperatur 0;
BA_ "GenSigSwitchedByIgnition" SG_ 968 GE_Sumpftemperatur 0;
BA_ "Fehlerwert" SG_ 968 GE_Sumpftemperatur 255;
BA_ "GenSigSendType" SG_ 968 GE_Zustand_Kuppltemp 0;
BA_ "GenSigSwitchedByIgnition" SG_ 968 GE_Zustand_Kuppltemp 0;
BA_ "GenSigSendType" SG_ 324 GE_Ist_Fahrstufe 0;
BA_ "GenSigSwitchedByIgnition" SG_ 324 GE_Ist_Fahrstufe 0;
BA_ "Fehlerwert" SG_ 324 GE_Ist_Fahrstufe 15;
BA_ "GenSigSendType" SG_ 324 GE_N_Haltephase 0;
BA_ "GenSigSwitchedByIgnition" SG_ 324 GE_N_Haltephase 0;
BA_ "GenSigSendType" SG_ 324 GE_Soll_Haltemagnet 0;
BA_ "GenSigSwitchedByIgnition" SG_ 324 GE_Soll_Haltemagnet 0;
BA_ "GenSigSendType" SG_ 324 GE_Test_Freigabe 0;
BA_ "GenSigSwitchedByIgnition" SG_ 324 GE_Test_Freigabe 0;
BA_ "GenSigSendType" SG_ 324 GE_Testparameter_1 0;
BA_ "GenSigSwitchedByIgnition" SG_ 324 GE_Testparameter_1 0;
BA_ "GenSigSendType" SG_ 324 GE_Testparameter_2 0;
BA_ "GenSigSwitchedByIgnition" SG_ 324 GE_Testparameter_2 0;
BA_ "GenSigSendType" SG_ 324 GE_WH_Abschalten 0;
BA_ "GenSigSwitchedByIgnition" SG_ 324 GE_WH_Abschalten 0;
BA_ "GenSigSendType" SG_ 324 GE_WH_Sperre 0;
BA_ "GenSigStartValue" SG_ 324 GE_WH_Sperre 1;
BA_ "GenSigSwitchedByIgnition" SG_ 324 GE_WH_Sperre 0;
BA_ "GenSigSendType" SG_ 324 Getriebe_16_BZ 0;
BA_ "GenSigFuncType" SG_ 324 Getriebe_16_BZ 1;
BA_ "GenSigSwitchedByIgnition" SG_ 324 Getriebe_16_BZ 0;
BA_ "GenSigSendType" SG_ 324 Getriebe_16_CRC 0;
BA_ "GenSigFuncType" SG_ 324 Getriebe_16_CRC 2;
BA_ "GenSigSwitchedByIgnition" SG_ 324 Getriebe_16_CRC 0;
BA_ "GenSigSendType" SG_ 324 WH_gespeicherte_Fahrstufe 0;
BA_ "GenSigSwitchedByIgnition" SG_ 324 WH_gespeicherte_Fahrstufe 0;
BA_ "GenSigSendType" SG_ 324 WH_P_Taste 0;
BA_ "GenSigSwitchedByIgnition" SG_ 324 WH_P_Taste 0;
BA_ "Fehlerwert" SG_ 324 WH_P_Taste 3;
BA_ "GenSigSendType" SG_ 324 WH_SensorPos_roh 0;
BA_ "GenSigSwitchedByIgnition" SG_ 324 WH_SensorPos_roh 0;
BA_ "Fehlerwert" SG_ 324 WH_SensorPos_roh 15;
BA_ "GenSigSendType" SG_ 324 WH_Warnung_02 0;
BA_ "GenSigSwitchedByIgnition" SG_ 324 WH_Warnung_02 0;
BA_ "GenSigSendType" SG_ 324 WH_Warnung_03 0;
BA_ "GenSigSwitchedByIgnition" SG_ 324 WH_Warnung_03 0;
BA_ "GenSigSendType" SG_ 299 GRA_Abbrechen 0;
BA_ "GenSigSendType" SG_ 299 GRA_ACC_01_BZ 0;
BA_ "GenSigFuncType" SG_ 299 GRA_ACC_01_BZ 1;
BA_ "GenSigSendType" SG_ 299 GRA_ACC_01_CRC 0;
BA_ "GenSigFuncType" SG_ 299 GRA_ACC_01_CRC 2;
BA_ "GenSigSendType" SG_ 299 GRA_Codierung 0;
BA_ "GenSigSendType" SG_ 299 GRA_Fehler 0;
BA_ "Fehlerwert" SG_ 299 GRA_Fehler 1;
BA_ "GenSigSendType" SG_ 299 GRA_Hauptschalter 3;
BA_ "GenSigSendType" SG_ 299 GRA_LIM_Taste_verfuegbar 0;
BA_ "GenSigFuncType" SG_ 299 GRA_LIM_Taste_verfuegbar 8;
BA_ "GenSigSendType" SG_ 299 GRA_Limiter 3;
BA_ "GenSigSendType" SG_ 299 GRA_reserveByte4 0;
BA_ "GenSigSendType" SG_ 299 GRA_reserveByte5 0;
BA_ "GenSigSendType" SG_ 299 GRA_reserveByte6 0;
BA_ "GenSigSendType" SG_ 299 GRA_reserveByte7 0;
BA_ "GenSigSendType" SG_ 299 GRA_reserveByte8 0;
BA_ "GenSigSendType" SG_ 299 GRA_Tip_Hoch 0;
BA_ "GenSigSendType" SG_ 299 GRA_Tip_Runter 0;
BA_ "GenSigSendType" SG_ 299 GRA_Tip_Setzen 0;
BA_ "GenSigSendType" SG_ 299 GRA_Tip_Stufe_2 0;
BA_ "GenSigSendType" SG_ 299 GRA_Tip_Wiederaufnahme 0;
BA_ "GenSigSendType" SG_ 299 GRA_TravelAssist 3;
BA_ "GenSigSwitchedByIgnition" SG_ 299 GRA_TravelAssist 0;
BA_ "GenSigSendType" SG_ 299 GRA_Typ_Bedienteil 0;
BA_ "GenSigSendType" SG_ 299 GRA_Typ_Hauptschalter 0;
BA_ "GenSigSendType" SG_ 299 GRA_Verstellung_Zeitluecke 0;
BA_ "GenSigSendType" SG_ 310 HAL_01_BZ 0;
BA_ "GenSigFuncType" SG_ 310 HAL_01_BZ 1;
BA_ "GenSigSwitchedByIgnition" SG_ 310 HAL_01_BZ 0;
BA_ "GenSigSendType" SG_ 310 HAL_01_CRC 0;
BA_ "GenSigFuncType" SG_ 310 HAL_01_CRC 2;
BA_ "GenSigSwitchedByIgnition" SG_ 310 HAL_01_CRC 0;
BA_ "GenSigSendType" SG_ 310 HAL_Charisma_FahrPr 0;
BA_ "GenSigSwitchedByIgnition" SG_ 310 HAL_Charisma_FahrPr 0;
BA_ "GenSigSendType" SG_ 310 HAL_Charisma_Status 0;
BA_ "GenSigSwitchedByIgnition" SG_ 310 HAL_Charisma_Status 0;
BA_ "GenSigSendType" SG_ 310 HAL_EFP_FahrPr 0;
BA_ "GenSigSwitchedByIgnition" SG_ 310 HAL_EFP_FahrPr 0;
BA_ "GenSigSendType" SG_ 310 HAL_Fahrerwunschwinkel_Soll 0;
BA_ "GenSigStartValue" SG_ 310 HAL_Fahrerwunschwinkel_Soll 1022;
BA_ "GenSigSwitchedByIgnition" SG_ 310 HAL_Fahrerwunschwinkel_Soll 0;
BA_ "Fehlerwert" SG_ 310 HAL_Fahrerwunschwinkel_Soll 1023;
BA_ "GenSigSendType" SG_ 310 HAL_max_Gradient 0;
BA_ "GenSigStartValue" SG_ 310 HAL_max_Gradient 126;
BA_ "GenSigSwitchedByIgnition" SG_ 310 HAL_max_Gradient 0;
BA_ "Fehlerwert" SG_ 310 HAL_max_Gradient 127;
BA_ "GenSigSendType" SG_ 310 HAL_QBit_Radwinkel 0;
BA_ "GenSigSwitchedByIgnition" SG_ 310 HAL_QBit_Radwinkel 0;
BA_ "GenSigSendType" SG_ 310 HAL_Radwinkel 0;
BA_ "GenSigStartValue" SG_ 310 HAL_Radwinkel 1022;
BA_ "GenSigSwitchedByIgnition" SG_ 310 HAL_Radwinkel 0;
BA_ "Fehlerwert" SG_ 310 HAL_Radwinkel 1023;
BA_ "GenSigSendType" SG_ 310 HAL_Status 0;
BA_ "GenSigSwitchedByIgnition" SG_ 310 HAL_Status 0;
BA_ "GenSigSendType" SG_ 310 HAL_Status_2 0;
BA_ "GenSigSwitchedByIgnition" SG_ 310 HAL_Status_2 0;
BA_ "GenSigSendType" SG_ 310 HAL_VZ_Fahrerwunschwinkel_Soll 0;
BA_ "GenSigSwitchedByIgnition" SG_ 310 HAL_VZ_Fahrerwunschwinkel_Soll 0;
BA_ "GenSigSendType" SG_ 310 HAL_VZ_Radwinkel 0;
BA_ "GenSigSwitchedByIgnition" SG_ 310 HAL_VZ_Radwinkel 0;
BA_ "GenSigSendType" SG_ 310 HAL_Warnungen 3;
BA_ "GenSigSwitchedByIgnition" SG_ 310 HAL_Warnungen 0;
BA_ "GenSigSendType" SG_ 310 HAL_Winkelbegrenzung 0;
BA_ "GenSigSwitchedByIgnition" SG_ 310 HAL_Winkelbegrenzung 0;
BA_ "GenSigSendType" SG_ 1412 HSP_01_BZ 0;
BA_ "GenSigFuncType" SG_ 1412 HSP_01_BZ 1;
BA_ "GenSigSwitchedByIgnition" SG_ 1412 HSP_01_BZ 0;
BA_ "GenSigSendType" SG_ 1412 HSP_01_CRC 0;
BA_ "GenSigFuncType" SG_ 1412 HSP_01_CRC 2;
BA_ "GenSigSwitchedByIgnition" SG_ 1412 HSP_01_CRC 0;
BA_ "GenSigSendType" SG_ 1412 HSP_BAP_Messages 0;
BA_ "GenSigSwitchedByIgnition" SG_ 1412 HSP_BAP_Messages 0;
BA_ "GenSigSendType" SG_ 1412 HSP_Charisma_FahrPr 0;
BA_ "GenSigSwitchedByIgnition" SG_ 1412 HSP_Charisma_FahrPr 0;
BA_ "GenSigSendType" SG_ 1412 HSP_Charisma_Status 0;
BA_ "GenSigSwitchedByIgnition" SG_ 1412 HSP_Charisma_Status 0;
BA_ "GenSigSendType" SG_ 1412 HSP_def 0;
BA_ "GenSigSwitchedByIgnition" SG_ 1412 HSP_def 0;
BA_ "Fehlerwert" SG_ 1412 HSP_def 1;
BA_ "GenSigSendType" SG_ 1412 HSP_Endlage_ausgefahren 0;
BA_ "GenSigSwitchedByIgnition" SG_ 1412 HSP_Endlage_ausgefahren 0;
BA_ "GenSigSendType" SG_ 1412 HSP_Endlage_eingefahren 0;
BA_ "GenSigSwitchedByIgnition" SG_ 1412 HSP_Endlage_eingefahren 0;
BA_ "GenSigSendType" SG_ 1412 HSP_ErrorGueltigkeit_1 0;
BA_ "GenSigSwitchedByIgnition" SG_ 1412 HSP_ErrorGueltigkeit_1 0;
BA_ "GenSigSendType" SG_ 1412 HSP_ErrorGueltigkeit_2 0;
BA_ "GenSigSwitchedByIgnition" SG_ 1412 HSP_ErrorGueltigkeit_2 0;
BA_ "GenSigSendType" SG_ 1412 HSP_Komponentensteuerung 0;
BA_ "GenSigSwitchedByIgnition" SG_ 1412 HSP_Komponentensteuerung 0;
BA_ "GenSigSendType" SG_ 1412 HSP_LED_Error 0;
BA_ "GenSigSwitchedByIgnition" SG_ 1412 HSP_LED_Error 0;
BA_ "Fehlerwert" SG_ 1412 HSP_LED_Error 1;
BA_ "GenSigSendType" SG_ 1412 HSP_Lokalaktiv 0;
BA_ "GenSigSwitchedByIgnition" SG_ 1412 HSP_Lokalaktiv 0;
BA_ "GenSigSendType" SG_ 1412 HSP_man_Betaet_nicht_zulaessig 0;
BA_ "GenSigSwitchedByIgnition" SG_ 1412 HSP_man_Betaet_nicht_zulaessig 0;
BA_ "GenSigSendType" SG_ 1412 HSP_Motor_def 0;
BA_ "GenSigSwitchedByIgnition" SG_ 1412 HSP_Motor_def 0;
BA_ "Fehlerwert" SG_ 1412 HSP_Motor_def 1;
BA_ "GenSigSendType" SG_ 1412 HSP_Motor_Temp_Text 0;
BA_ "GenSigSwitchedByIgnition" SG_ 1412 HSP_Motor_Temp_Text 0;
BA_ "GenSigSendType" SG_ 1412 HSP_ResponseError 0;
BA_ "GenSigSwitchedByIgnition" SG_ 1412 HSP_ResponseError 0;
BA_ "Fehlerwert" SG_ 1412 HSP_ResponseError 1;
BA_ "GenSigSendType" SG_ 1412 HSP_Spielschutz 0;
BA_ "GenSigSwitchedByIgnition" SG_ 1412 HSP_Spielschutz 0;
BA_ "GenSigSendType" SG_ 1412 HSP_Spoiler_Error 0;
BA_ "GenSigSwitchedByIgnition" SG_ 1412 HSP_Spoiler_Error 0;
BA_ "GenSigSendType" SG_ 1412 HSP_Status_LED 0;
BA_ "GenSigSwitchedByIgnition" SG_ 1412 HSP_Status_LED 0;
BA_ "GenSigSendType" SG_ 1412 HSP_Taster 0;
BA_ "GenSigSwitchedByIgnition" SG_ 1412 HSP_Taster 0;
BA_ "GenSigSendType" SG_ 1412 HSP_Taster_Error 0;
BA_ "GenSigSwitchedByIgnition" SG_ 1412 HSP_Taster_Error 0;
BA_ "GenSigSendType" SG_ 1412 HSP_Ueberspannung 0;
BA_ "GenSigSwitchedByIgnition" SG_ 1412 HSP_Ueberspannung 0;
BA_ "Fehlerwert" SG_ 1412 HSP_Ueberspannung 1;
BA_ "GenSigSendType" SG_ 1412 HSP_Unterspannung 0;
BA_ "GenSigSwitchedByIgnition" SG_ 1412 HSP_Unterspannung 0;
BA_ "Fehlerwert" SG_ 1412 HSP_Unterspannung 1;
BA_ "GenSigSendType" SG_ 1412 HSP_Warnung_LED 0;
BA_ "GenSigSwitchedByIgnition" SG_ 1412 HSP_Warnung_LED 0;
BA_ "GenSigSendType" SG_ 1412 HSP_Warnung_Text 0;
BA_ "GenSigSwitchedByIgnition" SG_ 1412 HSP_Warnung_Text 0;
BA_ "GenSigSendType" SG_ 1412 HSP_Warnung_Ton 0;
BA_ "GenSigSwitchedByIgnition" SG_ 1412 HSP_Warnung_Ton 0;
BA_ "GenSigSendType" SG_ 1609 HUD_Aktiv 0;
BA_ "GenSigSwitchedByIgnition" SG_ 1609 HUD_Aktiv 0;
BA_ "GenSigSendType" SG_ 1609 HUD_Anforderung_Fokus 3;
BA_ "GenSigSwitchedByIgnition" SG_ 1609 HUD_Anforderung_Fokus 0;
BA_ "GenSigSendType" SG_ 1609 HUD_Anzeigefehler_NV 0;
BA_ "GenSigSendType" SG_ 1609 HUD_FAS_Anzeige_Kombi 3;
BA_ "GenSigSwitchedByIgnition" SG_ 1609 HUD_FAS_Anzeige_Kombi 0;
BA_ "GenSigSendType" SG_ 1609 HUD_KDK_Anzeige_Kombi 3;
BA_ "GenSigSwitchedByIgnition" SG_ 1609 HUD_KDK_Anzeige_Kombi 0;
BA_ "GenSigSendType" SG_ 1609 HUD_NV_in_Anzeige 3;
BA_ "GenSigSwitchedByIgnition" SG_ 1609 HUD_NV_in_Anzeige 0;
BA_ "GenSigSendType" SG_ 1609 HUD_PEA_Anzeige_Kombi 3;
BA_ "GenSigSwitchedByIgnition" SG_ 1609 HUD_PEA_Anzeige_Kombi 0;
BA_ "GenSigSendType" SG_ 1609 HUD_VZE_AIO_Anzeige_Kombi 3;
BA_ "GenSigSwitchedByIgnition" SG_ 1609 HUD_VZE_AIO_Anzeige_Kombi 0;
BA_ "GenSigSendType" SG_ 1609 HUD_VZE_in_Anzeige 3;
BA_ "GenSigSendType" SG_ 1283 HV_Bordnetz_aktiv 3;
BA_ "GenSigSwitchedByIgnition" SG_ 1283 HV_Bordnetz_aktiv 0;
BA_ "GenSigSendType" SG_ 1283 HV_Bordnetz_Fehler 3;
BA_ "GenSigSwitchedByIgnition" SG_ 1283 HV_Bordnetz_Fehler 0;
BA_ "Fehlerwert" SG_ 1283 HV_Bordnetz_Fehler 1;
BA_ "GenSigSendType" SG_ 1283 HVK_01_BZ 0;
BA_ "GenSigFuncType" SG_ 1283 HVK_01_BZ 1;
BA_ "GenSigSwitchedByIgnition" SG_ 1283 HVK_01_BZ 0;
BA_ "GenSigSendType" SG_ 1283 HVK_01_CRC 0;
BA_ "GenSigFuncType" SG_ 1283 HVK_01_CRC 2;
BA_ "GenSigSwitchedByIgnition" SG_ 1283 HVK_01_CRC 0;
BA_ "GenSigSendType" SG_ 1283 HVK_AIAD_Sollmodus_2 3;
BA_ "GenSigSwitchedByIgnition" SG_ 1283 HVK_AIAD_Sollmodus_2 0;
BA_ "GenSigSendType" SG_ 1283 HVK_AktiveEntladung_Anf 3;
BA_ "GenSigSwitchedByIgnition" SG_ 1283 HVK_AktiveEntladung_Anf 0;
BA_ "GenSigSendType" SG_ 1283 HVK_BMS_Sollmodus 3;
BA_ "GenSigStartValue" SG_ 1283 HVK_BMS_Sollmodus 7;
BA_ "GenSigSwitchedByIgnition" SG_ 1283 HVK_BMS_Sollmodus 0;
BA_ "GenSigSendType" SG_ 1283 HVK_DCDC_EKK_Sollmodus 0;
BA_ "GenSigStartValue" SG_ 1283 HVK_DCDC_EKK_Sollmodus 3;
BA_ "GenSigSwitchedByIgnition" SG_ 1283 HVK_DCDC_EKK_Sollmodus 0;
BA_ "GenSigSendType" SG_ 1283 HVK_DCDC_Sollmodus 3;
BA_ "GenSigStartValue" SG_ 1283 HVK_DCDC_Sollmodus 7;
BA_ "GenSigSwitchedByIgnition" SG_ 1283 HVK_DCDC_Sollmodus 0;
BA_ "GenSigSendType" SG_ 1283 HVK_EKK_Sollmodus 3;
BA_ "GenSigStartValue" SG_ 1283 HVK_EKK_Sollmodus 7;
BA_ "GenSigSwitchedByIgnition" SG_ 1283 HVK_EKK_Sollmodus 0;
BA_ "GenSigSendType" SG_ 1283 HVK_Gesamtst_Spgfreiheit 0;
BA_ "GenSigSwitchedByIgnition" SG_ 1283 HVK_Gesamtst_Spgfreiheit 0;
BA_ "Fehlerwert" SG_ 1283 HVK_Gesamtst_Spgfreiheit 3;
BA_ "GenSigSendType" SG_ 1283 HVK_HV_Netz_Warnungen 3;
BA_ "GenSigSwitchedByIgnition" SG_ 1283 HVK_HV_Netz_Warnungen 0;
BA_ "GenSigSendType" SG_ 1283 HVK_HVLM_Sollmodus 3;
BA_ "GenSigStartValue" SG_ 1283 HVK_HVLM_Sollmodus 7;
BA_ "GenSigSwitchedByIgnition" SG_ 1283 HVK_HVLM_Sollmodus 0;
BA_ "GenSigSendType" SG_ 1283 HVK_HVPTC_Sollmodus 3;
BA_ "GenSigStartValue" SG_ 1283 HVK_HVPTC_Sollmodus 7;
BA_ "GenSigSwitchedByIgnition" SG_ 1283 HVK_HVPTC_Sollmodus 0;
BA_ "GenSigSendType" SG_ 1283 HVK_Iso_Fehlerstatus 0;
BA_ "GenSigSwitchedByIgnition" SG_ 1283 HVK_Iso_Fehlerstatus 0;
BA_ "Fehlerwert" SG_ 1283 HVK_Iso_Fehlerstatus 1;
BA_ "GenSigSendType" SG_ 1283 HVK_Iso_Messung_Start 3;
BA_ "GenSigSwitchedByIgnition" SG_ 1283 HVK_Iso_Messung_Start 0;
BA_ "GenSigSendType" SG_ 1283 HVK_Istmodus_Anf 3;
BA_ "GenSigSwitchedByIgnition" SG_ 1283 HVK_Istmodus_Anf 0;
BA_ "GenSigSendType" SG_ 1283 HVK_MO_EmSollzustand 3;
BA_ "GenSigStartValue" SG_ 1283 HVK_MO_EmSollzustand 255;
BA_ "GenSigSwitchedByIgnition" SG_ 1283 HVK_MO_EmSollzustand 0;
BA_ "GenSigSendType" SG_ 1283 HVK_TN1_Sollmodus 3;
BA_ "GenSigStartValue" SG_ 1283 HVK_TN1_Sollmodus 3;
BA_ "GenSigSwitchedByIgnition" SG_ 1283 HVK_TN1_Sollmodus 0;
BA_ "GenSigSendType" SG_ 1381 HVLM_Freigabe_Lastabwurf 0;
BA_ "GenSigSwitchedByIgnition" SG_ 1381 HVLM_Freigabe_Lastabwurf 0;
BA_ "GenSigSendType" SG_ 1381 HVLM_FreigabeKlimatisierung 0;
BA_ "GenSigStartValue" SG_ 1381 HVLM_FreigabeKlimatisierung 2;
BA_ "GenSigSwitchedByIgnition" SG_ 1381 HVLM_FreigabeKlimatisierung 0;
BA_ "Fehlerwert" SG_ 1381 HVLM_FreigabeKlimatisierung 3;
BA_ "GenSigSendType" SG_ 1381 HVLM_FreigabeTankdeckel 0;
BA_ "GenSigStartValue" SG_ 1381 HVLM_FreigabeTankdeckel 2;
BA_ "GenSigSwitchedByIgnition" SG_ 1381 HVLM_FreigabeTankdeckel 0;
BA_ "Fehlerwert" SG_ 1381 HVLM_FreigabeTankdeckel 3;
BA_ "GenSigSendType" SG_ 1381 HVLM_HV_Abstellzeit 0;
BA_ "GenSigStartValue" SG_ 1381 HVLM_HV_Abstellzeit 254;
BA_ "GenSigSwitchedByIgnition" SG_ 1381 HVLM_HV_Abstellzeit 0;
BA_ "Fehlerwert" SG_ 1381 HVLM_HV_Abstellzeit 255;
BA_ "GenSigSendType" SG_ 1381 HVLM_IsoMessung_Anf 3;
BA_ "GenSigSwitchedByIgnition" SG_ 1381 HVLM_IsoMessung_Anf 0;
BA_ "GenSigSendType" SG_ 1381 HVLM_IstSpannung_HV 0;
BA_ "GenSigStartValue" SG_ 1381 HVLM_IstSpannung_HV 1022;
BA_ "GenSigSwitchedByIgnition" SG_ 1381 HVLM_IstSpannung_HV 0;
BA_ "Fehlerwert" SG_ 1381 HVLM_IstSpannung_HV 1023;
BA_ "GenSigSendType" SG_ 1381 HVLM_Ladesystemhinweise 3;
BA_ "GenSigSwitchedByIgnition" SG_ 1381 HVLM_Ladesystemhinweise 0;
BA_ "GenSigSendType" SG_ 1381 HVLM_Ladetexte 3;
BA_ "GenSigSwitchedByIgnition" SG_ 1381 HVLM_Ladetexte 0;
BA_ "GenSigSendType" SG_ 1381 HVLM_LG_Sollmodus 0;
BA_ "GenSigSwitchedByIgnition" SG_ 1381 HVLM_LG_Sollmodus 0;
BA_ "GenSigSendType" SG_ 1381 HVLM_MaxStrom_Netz 0;
BA_ "GenSigStartValue" SG_ 1381 HVLM_MaxStrom_Netz 126;
BA_ "GenSigSwitchedByIgnition" SG_ 1381 HVLM_MaxStrom_Netz 0;
BA_ "Fehlerwert" SG_ 1381 HVLM_MaxStrom_Netz 127;
BA_ "GenSigSendType" SG_ 1381 HVLM_Schluessel_Anfrage 0;
BA_ "GenSigSwitchedByIgnition" SG_ 1381 HVLM_Schluessel_Anfrage 0;
BA_ "GenSigSendType" SG_ 1381 HVLM_Start_Spannungsmessung_DCLS 0;
BA_ "GenSigSwitchedByIgnition" SG_ 1381 HVLM_Start_Spannungsmessung_DCLS 0;
BA_ "GenSigSendType" SG_ 1381 HVLM_Stecker_Verriegeln 0;
BA_ "GenSigStartValue" SG_ 1381 HVLM_Stecker_Verriegeln 2;
BA_ "GenSigSwitchedByIgnition" SG_ 1381 HVLM_Stecker_Verriegeln 0;
BA_ "GenSigSendType" SG_ 1381 HVLM_Zustand_LED 3;
BA_ "GenSigStartValue" SG_ 1381 HVLM_Zustand_LED 14;
BA_ "GenSigSwitchedByIgnition" SG_ 1381 HVLM_Zustand_LED 0;
BA_ "Fehlerwert" SG_ 1381 HVLM_Zustand_LED 15;
BA_ "GenSigSendType" SG_ 1381 PnC_Trigger_OBC_cGW 3;
BA_ "GenSigSwitchedByIgnition" SG_ 1381 PnC_Trigger_OBC_cGW 0;
BA_ "GenSigSendType" SG_ 312 IPA_01_BZ 0;
BA_ "GenSigFuncType" SG_ 312 IPA_01_BZ 1;
BA_ "GenSigSwitchedByIgnition" SG_ 312 IPA_01_BZ 0;
BA_ "GenSigSendType" SG_ 312 IPA_01_CRC 0;
BA_ "GenSigFuncType" SG_ 312 IPA_01_CRC 2;
BA_ "GenSigSwitchedByIgnition" SG_ 312 IPA_01_CRC 0;
BA_ "GenSigSendType" SG_ 312 IPA_Anforderung_HMS 0;
BA_ "GenSigSwitchedByIgnition" SG_ 312 IPA_Anforderung_HMS 0;
BA_ "GenSigSendType" SG_ 312 IPA_APS_LED 3;
BA_ "GenSigStartValue" SG_ 312 IPA_APS_LED 6;
BA_ "GenSigSendType" SG_ 312 IPA_Fahrstufenwunsch 0;
BA_ "GenSigSendType" SG_ 312 IPA_Parken_beibehalten_HMS 0;
BA_ "GenSigStartValue" SG_ 312 IPA_Parken_beibehalten_HMS 2;
BA_ "Fehlerwert" SG_ 312 IPA_Parken_beibehalten_HMS 3;
BA_ "GenSigSendType" SG_ 312 IPA_PLA_LED 3;
BA_ "GenSigStartValue" SG_ 312 IPA_PLA_LED 6;
BA_ "GenSigSendType" SG_ 312 IPA_Sollbeschleunigung 0;
BA_ "GenSigSendType" SG_ 312 IPA_Status 3;
BA_ "GenSigSwitchedByIgnition" SG_ 312 IPA_Status 0;
BA_ "GenSigSendType" SG_ 312 IPA_Status_EDR 3;
BA_ "GenSigStartValue" SG_ 312 IPA_Status_EDR 1;
BA_ "GenSigSwitchedByIgnition" SG_ 312 IPA_Status_EDR 0;
BA_ "GenSigSendType" SG_ 312 IPA_Status_IPA_GE 0;
BA_ "Fehlerwert" SG_ 312 IPA_Status_IPA_GE 7;
BA_ "GenSigSendType" SG_ 312 IPA_Status_IPA_TSK 3;
BA_ "GenSigStartValue" SG_ 312 IPA_Status_IPA_TSK 1;
BA_ "GenSigSendType" SG_ 312 Parken_aktives_System 3;
BA_ "GenSigSendType" SG_ 312 Parken_erhoehtes_Moment 0;
BA_ "GenSigSwitchedByIgnition" SG_ 312 Parken_erhoehtes_Moment 0;
BA_ "GenSigSendType" SG_ 312 Parken_Fahrbereitschaft_Anf 3;
BA_ "GenSigSendType" SG_ 312 Parken_Motorlauf_Anf 3;
BA_ "GenSigSendType" SG_ 1792 ISO_ALL_01_Req_Data 3;
BA_ "GenSigFuncType" SG_ 1792 ISO_ALL_01_Req_Data 9;
BA_ "GenSigSwitchedByIgnition" SG_ 1792 ISO_ALL_01_Req_Data 0;
BA_ "GenSigSendType" SG_ 1819 ISO_HUD_Req_Data 3;
BA_ "GenSigFuncType" SG_ 1819 ISO_HUD_Req_Data 9;
BA_ "GenSigSwitchedByIgnition" SG_ 1819 ISO_HUD_Req_Data 0;
BA_ "GenSigSendType" SG_ 1925 ISO_HUD_Resp_Data 3;
BA_ "GenSigFuncType" SG_ 1925 ISO_HUD_Resp_Data 9;
BA_ "GenSigSwitchedByIgnition" SG_ 1925 ISO_HUD_Resp_Data 0;
BA_ "GenSigSendType" SG_ 1812 ISO_Kombi_Req_Data 3;
BA_ "GenSigFuncType" SG_ 1812 ISO_Kombi_Req_Data 9;
BA_ "GenSigSwitchedByIgnition" SG_ 1812 ISO_Kombi_Req_Data 0;
BA_ "GenSigSendType" SG_ 1918 ISO_Kombi_Resp_Data 3;
BA_ "GenSigFuncType" SG_ 1918 ISO_Kombi_Resp_Data 9;
BA_ "GenSigSwitchedByIgnition" SG_ 1918 ISO_Kombi_Resp_Data 0;
BA_ "GenSigSendType" SG_ 1875 ISO_Waehlhebel_Req_Data 3;
BA_ "GenSigFuncType" SG_ 1875 ISO_Waehlhebel_Req_Data 9;
BA_ "GenSigSwitchedByIgnition" SG_ 1875 ISO_Waehlhebel_Req_Data 0;
BA_ "GenSigSendType" SG_ 1981 ISO_Waehlhebel_Resp_Data 3;
BA_ "GenSigFuncType" SG_ 1981 ISO_Waehlhebel_Resp_Data 9;
BA_ "GenSigSwitchedByIgnition" SG_ 1981 ISO_Waehlhebel_Resp_Data 0;
BA_ "GenSigSendType" SG_ 2463978614 KAS_Anf_Bremsruck 0;
BA_ "GenSigSendType" SG_ 2463978614 KAS_Anf_OPS 0;
BA_ "GenSigSendType" SG_ 2463978614 KAS_Anf_Prefill 0;
BA_ "GenSigSendType" SG_ 2463978614 KAS_Anzeige_Info_links 3;
BA_ "GenSigSendType" SG_ 2463978614 KAS_Anzeige_Info_rechts 3;
BA_ "GenSigSendType" SG_ 2463978614 KAS_Anzeige_Warnung 3;
BA_ "GenSigSendType" SG_ 2463978614 KAS_Kritikalitaetslevel 0;
BA_ "GenSigStartValue" SG_ 2463978614 KAS_Kritikalitaetslevel 7;
BA_ "GenSigSendType" SG_ 2463978614 KAS_PreSense_Modus_System 0;
BA_ "GenSigSendType" SG_ 2463978614 KAS_Status 3;
BA_ "Fehlerwert" SG_ 2463978614 KAS_Status 6;
BA_ "GenSigSendType" SG_ 2463978614 KAS_Texte 3;
BA_ "GenSigSendType" SG_ 2463978614 KAS_Verfuegbarkeit 3;
BA_ "GenSigSendType" SG_ 2463978614 KAS_Verz_Anf 0;
BA_ "GenSigStartValue" SG_ 2463978614 KAS_Verz_Anf 254;
BA_ "Fehlerwert" SG_ 2463978614 KAS_Verz_Anf 255;
BA_ "GenSigActiveRepetitions" SG_ 497 FBS_Aktivierung_Pilot_Parken 7;
BA_ "GenSigSendType" SG_ 497 FBS_Aktivierung_Pilot_Parken 2;
BA_ "GenSigSwitchedByIgnition" SG_ 497 FBS_Aktivierung_Pilot_Parken 0;
BA_ "GenSigActiveRepetitions" SG_ 497 FFB_FDF_Taste 7;
BA_ "GenSigSendType" SG_ 497 FFB_FDF_Taste 2;
BA_ "GenSigSwitchedByIgnition" SG_ 497 FFB_FDF_Taste 0;
BA_ "GenSigActiveRepetitions" SG_ 497 FFB_Joker_Taste 7;
BA_ "GenSigSendType" SG_ 497 FFB_Joker_Taste 2;
BA_ "GenSigSwitchedByIgnition" SG_ 497 FFB_Joker_Taste 0;
BA_ "GenSigActiveRepetitions" SG_ 497 FFB_Park_Taste 7;
BA_ "GenSigSendType" SG_ 497 FFB_Park_Taste 2;
BA_ "GenSigSwitchedByIgnition" SG_ 497 FFB_Park_Taste 0;
BA_ "GenSigActiveRepetitions" SG_ 497 FFB_Remotestart_Taste 7;
BA_ "GenSigSendType" SG_ 497 FFB_Remotestart_Taste 2;
BA_ "GenSigSwitchedByIgnition" SG_ 497 FFB_Remotestart_Taste 0;
BA_ "GenSigActiveRepetitions" SG_ 497 KY_Auf_Taste 7;
BA_ "GenSigSendType" SG_ 497 KY_Auf_Taste 2;
BA_ "GenSigSwitchedByIgnition" SG_ 497 KY_Auf_Taste 0;
BA_ "GenSigActiveRepetitions" SG_ 497 KY_Bereich 7;
BA_ "GenSigSendType" SG_ 497 KY_Bereich 2;
BA_ "GenSigStartValue" SG_ 497 KY_Bereich 7;
BA_ "GenSigSwitchedByIgnition" SG_ 497 KY_Bereich 0;
BA_ "GenSigActiveRepetitions" SG_ 497 KY_BT_Entriegelung_Autorisiert 7;
BA_ "GenSigSendType" SG_ 497 KY_BT_Entriegelung_Autorisiert 2;
BA_ "GenSigSwitchedByIgnition" SG_ 497 KY_BT_Entriegelung_Autorisiert 0;
BA_ "GenSigActiveRepetitions" SG_ 497 KY_BT_Verriegelung_Autorisiert 7;
BA_ "GenSigSendType" SG_ 497 KY_BT_Verriegelung_Autorisiert 2;
BA_ "GenSigSwitchedByIgnition" SG_ 497 KY_BT_Verriegelung_Autorisiert 0;
BA_ "GenSigSendType" SG_ 497 KY_EasyClose_Abbruch 3;
BA_ "GenSigSwitchedByIgnition" SG_ 497 KY_EasyClose_Abbruch 0;
BA_ "GenSigSendType" SG_ 497 KY_EasyClose_Status 3;
BA_ "GenSigSwitchedByIgnition" SG_ 497 KY_EasyClose_Status 0;
BA_ "GenSigActiveRepetitions" SG_ 497 KY_Front_Entr_Autorisiert 7;
BA_ "GenSigSendType" SG_ 497 KY_Front_Entr_Autorisiert 2;
BA_ "GenSigSwitchedByIgnition" SG_ 497 KY_Front_Entr_Autorisiert 0;
BA_ "GenSigActiveRepetitions" SG_ 497 KY_Front_Verr_Autorisiert 7;
BA_ "GenSigSendType" SG_ 497 KY_Front_Verr_Autorisiert 2;
BA_ "GenSigSwitchedByIgnition" SG_ 497 KY_Front_Verr_Autorisiert 0;
BA_ "GenSigActiveRepetitions" SG_ 497 KY_FT_Entriegelung_Autorisiert 7;
BA_ "GenSigSendType" SG_ 497 KY_FT_Entriegelung_Autorisiert 2;
BA_ "GenSigSwitchedByIgnition" SG_ 497 KY_FT_Entriegelung_Autorisiert 0;
BA_ "GenSigActiveRepetitions" SG_ 497 KY_FT_Verriegelung_Autorisiert 7;
BA_ "GenSigSendType" SG_ 497 KY_FT_Verriegelung_Autorisiert 2;
BA_ "GenSigSwitchedByIgnition" SG_ 497 KY_FT_Verriegelung_Autorisiert 0;
BA_ "GenSigActiveRepetitions" SG_ 497 KY_HBFS_Entriegelung_Autorisiert 7;
BA_ "GenSigSendType" SG_ 497 KY_HBFS_Entriegelung_Autorisiert 2;
BA_ "GenSigSwitchedByIgnition" SG_ 497 KY_HBFS_Entriegelung_Autorisiert 0;
BA_ "GenSigActiveRepetitions" SG_ 497 KY_HBFS_Verriegelung_Autorisiert 7;
BA_ "GenSigSendType" SG_ 497 KY_HBFS_Verriegelung_Autorisiert 2;
BA_ "GenSigSwitchedByIgnition" SG_ 497 KY_HBFS_Verriegelung_Autorisiert 0;
BA_ "GenSigActiveRepetitions" SG_ 497 KY_HD_Auffahrt 7;
BA_ "GenSigSendType" SG_ 497 KY_HD_Auffahrt 2;
BA_ "GenSigSwitchedByIgnition" SG_ 497 KY_HD_Auffahrt 0;
BA_ "GenSigActiveRepetitions" SG_ 497 KY_HD_Entriegelung_Autorisiert 7;
BA_ "GenSigSendType" SG_ 497 KY_HD_Entriegelung_Autorisiert 2;
BA_ "GenSigSwitchedByIgnition" SG_ 497 KY_HD_Entriegelung_Autorisiert 0;
BA_ "GenSigActiveRepetitions" SG_ 497 KY_HD_Verriegelung_Autorisiert 7;
BA_ "GenSigSendType" SG_ 497 KY_HD_Verriegelung_Autorisiert 2;
BA_ "GenSigSwitchedByIgnition" SG_ 497 KY_HD_Verriegelung_Autorisiert 0;
BA_ "GenSigActiveRepetitions" SG_ 497 KY_HD_Zufahrt 7;
BA_ "GenSigSendType" SG_ 497 KY_HD_Zufahrt 2;
BA_ "GenSigSwitchedByIgnition" SG_ 497 KY_HD_Zufahrt 0;
BA_ "GenSigActiveRepetitions" SG_ 497 KY_HDF_Taste 7;
BA_ "GenSigSendType" SG_ 497 KY_HDF_Taste 2;
BA_ "GenSigSwitchedByIgnition" SG_ 497 KY_HDF_Taste 0;
BA_ "GenSigActiveRepetitions" SG_ 497 KY_HFS_Entriegelung_Autorisiert 7;
BA_ "GenSigSendType" SG_ 497 KY_HFS_Entriegelung_Autorisiert 2;
BA_ "GenSigSwitchedByIgnition" SG_ 497 KY_HFS_Entriegelung_Autorisiert 0;
BA_ "GenSigActiveRepetitions" SG_ 497 KY_HFS_Verriegelung_Autorisiert 7;
BA_ "GenSigSendType" SG_ 497 KY_HFS_Verriegelung_Autorisiert 2;
BA_ "GenSigSwitchedByIgnition" SG_ 497 KY_HFS_Verriegelung_Autorisiert 0;
BA_ "GenSigActiveRepetitions" SG_ 497 KY_IDG_in_Reichweite 7;
BA_ "GenSigSendType" SG_ 497 KY_IDG_in_Reichweite 2;
BA_ "GenSigSwitchedByIgnition" SG_ 497 KY_IDG_in_Reichweite 0;
BA_ "GenSigActiveRepetitions" SG_ 497 KY_LKL_1_Autorisierung 7;
BA_ "GenSigSendType" SG_ 497 KY_LKL_1_Autorisierung 2;
BA_ "GenSigSwitchedByIgnition" SG_ 497 KY_LKL_1_Autorisierung 0;
BA_ "GenSigActiveRepetitions" SG_ 497 KY_LKL_2_Autorisierung 7;
BA_ "GenSigSendType" SG_ 497 KY_LKL_2_Autorisierung 2;
BA_ "GenSigSwitchedByIgnition" SG_ 497 KY_LKL_2_Autorisierung 0;
BA_ "GenSigActiveRepetitions" SG_ 497 KY_Panik_Taste 7;
BA_ "GenSigSendType" SG_ 497 KY_Panik_Taste 2;
BA_ "GenSigSwitchedByIgnition" SG_ 497 KY_Panik_Taste 0;
BA_ "GenSigActiveRepetitions" SG_ 497 KY_Position 7;
BA_ "GenSigSendType" SG_ 497 KY_Position 2;
BA_ "GenSigStartValue" SG_ 497 KY_Position 7;
BA_ "GenSigSwitchedByIgnition" SG_ 497 KY_Position 0;
BA_ "GenSigActiveRepetitions" SG_ 497 KY_Schluessel_im_Fzg 7;
BA_ "GenSigSendType" SG_ 497 KY_Schluessel_im_Fzg 2;
BA_ "GenSigSwitchedByIgnition" SG_ 497 KY_Schluessel_im_Fzg 0;
BA_ "GenSigActiveRepetitions" SG_ 497 KY_Zu_Taste 7;
BA_ "GenSigSendType" SG_ 497 KY_Zu_Taste 2;
BA_ "GenSigSwitchedByIgnition" SG_ 497 KY_Zu_Taste 0;
BA_ "GenSigActiveRepetitions" SG_ 497 KY_ZV_Signatur 7;
BA_ "GenSigSendType" SG_ 497 KY_ZV_Signatur 2;
BA_ "GenSigSwitchedByIgnition" SG_ 497 KY_ZV_Signatur 0;
BA_ "GenSigActiveRepetitions" SG_ 497 Schluesselnr_Personalisierung 7;
BA_ "GenSigSendType" SG_ 497 Schluesselnr_Personalisierung 2;
BA_ "GenSigStartValue" SG_ 497 Schluesselnr_Personalisierung 14;
BA_ "GenSigSwitchedByIgnition" SG_ 497 Schluesselnr_Personalisierung 0;
BA_ "Fehlerwert" SG_ 497 Schluesselnr_Personalisierung 15;
BA_ "GenSigSendType" SG_ 1424 FBS_Warn_Schluessel_Batt 3;
BA_ "GenSigSwitchedByIgnition" SG_ 1424 FBS_Warn_Schluessel_Batt 0;
BA_ "GenSigSendType" SG_ 1424 KST_Wegstrecke_Challenge 0;
BA_ "GenSigSwitchedByIgnition" SG_ 1424 KST_Wegstrecke_Challenge 0;
BA_ "GenSigSendType" SG_ 1424 KY_FFB_Frequenz 3;
BA_ "GenSigSwitchedByIgnition" SG_ 1424 KY_FFB_Frequenz 0;
BA_ "GenSigSendType" SG_ 1424 KY_Fzg_Verlassen_erkannt 3;
BA_ "GenSigSwitchedByIgnition" SG_ 1424 KY_Fzg_Verlassen_erkannt 0;
BA_ "GenSigSendType" SG_ 1424 KY_Fzg_Zugang_erkannt 3;
BA_ "GenSigSwitchedByIgnition" SG_ 1424 KY_Fzg_Zugang_erkannt 0;
BA_ "GenSigSendType" SG_ 1424 KY_HF_Aktiv 3;
BA_ "GenSigSwitchedByIgnition" SG_ 1424 KY_HF_Aktiv 0;
BA_ "GenSigSendType" SG_ 1424 KY_Indikator_Mehrere_Schluessel 3;
BA_ "GenSigSwitchedByIgnition" SG_ 1424 KY_Indikator_Mehrere_Schluessel 0;
BA_ "GenSigSendType" SG_ 1424 KY_Keyless_Go_Verbau 3;
BA_ "GenSigSwitchedByIgnition" SG_ 1424 KY_Keyless_Go_Verbau 0;
BA_ "GenSigSendType" SG_ 1424 KY_Keyless_Verbau 3;
BA_ "GenSigSwitchedByIgnition" SG_ 1424 KY_Keyless_Verbau 0;
BA_ "GenSigSendType" SG_ 1424 KY_KYL_Fahrer_Hinweise 3;
BA_ "GenSigSwitchedByIgnition" SG_ 1424 KY_KYL_Fahrer_Hinweise 0;
BA_ "GenSigSendType" SG_ 1424 KY_LF_Aktiv 3;
BA_ "GenSigSwitchedByIgnition" SG_ 1424 KY_LF_Aktiv 0;
BA_ "GenSigSendType" SG_ 1424 KY_NFC_Fahrer_Hinweise 0;
BA_ "GenSigSwitchedByIgnition" SG_ 1424 KY_NFC_Fahrer_Hinweise 0;
BA_ "GenSigSendType" SG_ 1424 KY_StartStopp_Info 3;
BA_ "GenSigSwitchedByIgnition" SG_ 1424 KY_StartStopp_Info 0;
BA_ "GenSigSendType" SG_ 1424 KY_Transponder_aktiv 3;
BA_ "GenSigSwitchedByIgnition" SG_ 1424 KY_Transponder_aktiv 0;
BA_ "GenSigSendType" SG_ 1424 KYL_Warn_kein_Schluessel 3;
BA_ "GenSigSwitchedByIgnition" SG_ 1424 KYL_Warn_kein_Schluessel 0;
BA_ "GenSigSendType" SG_ 1424 KYL_Warn_Kessy_defekt 3;
BA_ "GenSigSwitchedByIgnition" SG_ 1424 KYL_Warn_Kessy_defekt 0;
BA_ "GenSigSendType" SG_ 1424 KYL_Warn_Notzuendschloss 3;
BA_ "GenSigSwitchedByIgnition" SG_ 1424 KYL_Warn_Notzuendschloss 0;
BA_ "GenSigSendType" SG_ 2463978671 KFS_Ausgefahren 3;
BA_ "GenSigSwitchedByIgnition" SG_ 2463978671 KFS_Ausgefahren 0;
BA_ "GenSigSendType" SG_ 2463978671 KFS_Eingefahren 3;
BA_ "GenSigSwitchedByIgnition" SG_ 2463978671 KFS_Eingefahren 0;
BA_ "GenSigSendType" SG_ 2463978671 KFS_Fehler_Beleuchtung 0;
BA_ "GenSigSwitchedByIgnition" SG_ 2463978671 KFS_Fehler_Beleuchtung 0;
BA_ "GenSigSendType" SG_ 960 BCM_Ausparken_Betrieb 3;
BA_ "GenSigSwitchedByIgnition" SG_ 960 BCM_Ausparken_Betrieb 0;
BA_ "GenSigSendType" SG_ 960 BCM_Remotestart_Betrieb 3;
BA_ "GenSigSwitchedByIgnition" SG_ 960 BCM_Remotestart_Betrieb 0;
BA_ "GenSigSendType" SG_ 960 BCM_Remotestart_KL15_Anf 3;
BA_ "GenSigSwitchedByIgnition" SG_ 960 BCM_Remotestart_KL15_Anf 0;
BA_ "GenSigSendType" SG_ 960 BCM_Remotestart_MO_Start 3;
BA_ "GenSigSwitchedByIgnition" SG_ 960 BCM_Remotestart_MO_Start 0;
BA_ "GenSigSendType" SG_ 960 Klemmen_Status_01_BZ 0;
BA_ "GenSigFuncType" SG_ 960 Klemmen_Status_01_BZ 1;
BA_ "GenSigSwitchedByIgnition" SG_ 960 Klemmen_Status_01_BZ 0;
BA_ "GenSigSendType" SG_ 960 Klemmen_Status_01_CRC 0;
BA_ "GenSigFuncType" SG_ 960 Klemmen_Status_01_CRC 2;
BA_ "GenSigSwitchedByIgnition" SG_ 960 Klemmen_Status_01_CRC 0;
BA_ "GenSigSendType" SG_ 960 KST_Fahrerhinweis_1 3;
BA_ "GenSigSwitchedByIgnition" SG_ 960 KST_Fahrerhinweis_1 0;
BA_ "GenSigSendType" SG_ 960 KST_Fahrerhinweis_2 3;
BA_ "GenSigSwitchedByIgnition" SG_ 960 KST_Fahrerhinweis_2 0;
BA_ "GenSigSendType" SG_ 960 KST_Fahrerhinweis_4 3;
BA_ "GenSigSwitchedByIgnition" SG_ 960 KST_Fahrerhinweis_4 0;
BA_ "GenSigSendType" SG_ 960 KST_Fahrerhinweis_5 3;
BA_ "GenSigSwitchedByIgnition" SG_ 960 KST_Fahrerhinweis_5 0;
BA_ "GenSigSendType" SG_ 960 KST_Fahrerhinweis_6 3;
BA_ "GenSigSwitchedByIgnition" SG_ 960 KST_Fahrerhinweis_6 0;
BA_ "GenSigSendType" SG_ 960 KST_Warn_P1_ZST_def 3;
BA_ "GenSigSwitchedByIgnition" SG_ 960 KST_Warn_P1_ZST_def 0;
BA_ "GenSigSendType" SG_ 960 KST_Warn_P2_ZST_def 3;
BA_ "GenSigSwitchedByIgnition" SG_ 960 KST_Warn_P2_ZST_def 0;
BA_ "GenSigSendType" SG_ 960 RSt_Fahrerhinweise 3;
BA_ "GenSigSwitchedByIgnition" SG_ 960 RSt_Fahrerhinweise 0;
BA_ "GenSigSendType" SG_ 960 ZAS_Kl_15 3;
BA_ "NWM-WakeupAllowed" SG_ 960 ZAS_Kl_15 1;
BA_ "GenSigFuncType" SG_ 960 ZAS_Kl_15 6;
BA_ "GenSigSwitchedByIgnition" SG_ 960 ZAS_Kl_15 0;
BA_ "GenSigSendType" SG_ 960 ZAS_Kl_50_Startanforderung 3;
BA_ "GenSigSwitchedByIgnition" SG_ 960 ZAS_Kl_50_Startanforderung 0;
BA_ "GenSigSendType" SG_ 960 ZAS_Kl_Infotainment 3;
BA_ "GenSigSwitchedByIgnition" SG_ 960 ZAS_Kl_Infotainment 0;
BA_ "GenSigSendType" SG_ 960 ZAS_Kl_S 3;
BA_ "GenSigSwitchedByIgnition" SG_ 960 ZAS_Kl_S 0;
BA_ "GenSigSendType" SG_ 960 ZAS_Kl_X 3;
BA_ "GenSigSwitchedByIgnition" SG_ 960 ZAS_Kl_X 0;
BA_ "GenSigSendType" SG_ 1420 Klemmen_Steuerung_01_BZ 0;
BA_ "GenSigFuncType" SG_ 1420 Klemmen_Steuerung_01_BZ 1;
BA_ "GenSigSwitchedByIgnition" SG_ 1420 Klemmen_Steuerung_01_BZ 0;
BA_ "GenSigSendType" SG_ 1420 Klemmen_Steuerung_01_CRC 0;
BA_ "GenSigFuncType" SG_ 1420 Klemmen_Steuerung_01_CRC 2;
BA_ "GenSigSwitchedByIgnition" SG_ 1420 Klemmen_Steuerung_01_CRC 0;
BA_ "GenSigSendType" SG_ 1420 KST_Anf_Klemmenfreigabe_ELV 8;
BA_ "GenSigSwitchedByIgnition" SG_ 1420 KST_Anf_Klemmenfreigabe_ELV 0;
BA_ "GenSigSendType" SG_ 1420 KST_Anf_ZV_Verriegelung 3;
BA_ "GenSigSwitchedByIgnition" SG_ 1420 KST_Anf_ZV_Verriegelung 0;
BA_ "GenSigSendType" SG_ 1420 KST_aut_Abschaltung_Zuendung 4;
BA_ "GenSigSwitchedByIgnition" SG_ 1420 KST_aut_Abschaltung_Zuendung 0;
BA_ "GenSigSendType" SG_ 1420 KST_Txt_Komfortabschaltung 3;
BA_ "GenSigSwitchedByIgnition" SG_ 1420 KST_Txt_Komfortabschaltung 0;
BA_ "GenSigSendType" SG_ 1420 KST_Txt_P_Gang 3;
BA_ "GenSigSwitchedByIgnition" SG_ 1420 KST_Txt_P_Gang 0;
BA_ "GenSigSendType" SG_ 1420 KST_Txt_Panikabschaltung 3;
BA_ "GenSigSwitchedByIgnition" SG_ 1420 KST_Txt_Panikabschaltung 0;
BA_ "GenSigSendType" SG_ 1420 KST_Unterdr_Zuendungsmeldung 3;
BA_ "GenSigSwitchedByIgnition" SG_ 1420 KST_Unterdr_Zuendungsmeldung 0;
BA_ "GenSigSendType" SG_ 1420 KST_ZAT_betaetigt 3;
BA_ "GenSigSwitchedByIgnition" SG_ 1420 KST_ZAT_betaetigt 0;
BA_ "GenSigSendType" SG_ 1420 Relais_VoKo_angesteuert 3;
BA_ "GenSigSwitchedByIgnition" SG_ 1420 Relais_VoKo_angesteuert 0;
BA_ "GenSigSendType" SG_ 1420 RSt_Anforderung_HMS 3;
BA_ "GenSigSwitchedByIgnition" SG_ 1420 RSt_Anforderung_HMS 0;
BA_ "GenSigSendType" SG_ 1646 KL_Anf_AussenspiegelHzg 3;
BA_ "GenSigSwitchedByIgnition" SG_ 1646 KL_Anf_AussenspiegelHzg 0;
BA_ "GenSigSendType" SG_ 1646 KL_BCmE_Livetip_Freigabe 3;
BA_ "GenSigSwitchedByIgnition" SG_ 1646 KL_BCmE_Livetip_Freigabe 0;
BA_ "GenSigSendType" SG_ 1646 KL_ErwVK_Anf 3;
BA_ "GenSigSwitchedByIgnition" SG_ 1646 KL_ErwVK_Anf 0;
BA_ "GenSigSendType" SG_ 1646 KL_ErwVK_Zusatzrelais 3;
BA_ "GenSigSwitchedByIgnition" SG_ 1646 KL_ErwVK_Zusatzrelais 0;
BA_ "GenSigSendType" SG_ 1646 KL_FSH_Automatikbetrieb 3;
BA_ "GenSigSwitchedByIgnition" SG_ 1646 KL_FSH_Automatikbetrieb 0;
BA_ "GenSigSendType" SG_ 1646 KL_Geblaese_Fond_Status 0;
BA_ "GenSigStartValue" SG_ 1646 KL_Geblaese_Fond_Status 14;
BA_ "GenSigSwitchedByIgnition" SG_ 1646 KL_Geblaese_Fond_Status 0;
BA_ "Fehlerwert" SG_ 1646 KL_Geblaese_Fond_Status 15;
BA_ "GenSigSendType" SG_ 1646 KL_Geblaese_Status 0;
BA_ "GenSigStartValue" SG_ 1646 KL_Geblaese_Status 14;
BA_ "GenSigSwitchedByIgnition" SG_ 1646 KL_Geblaese_Status 0;
BA_ "Fehlerwert" SG_ 1646 KL_Geblaese_Status 15;
BA_ "GenSigSendType" SG_ 1646 KL_Heizkreisventilstellung 0;
BA_ "GenSigSwitchedByIgnition" SG_ 1646 KL_Heizkreisventilstellung 0;
BA_ "Fehlerwert" SG_ 1646 KL_Heizkreisventilstellung 3;
BA_ "GenSigSendType" SG_ 1646 KL_HYB_ASV_hinten_schliessen_Anf 3;
BA_ "GenSigSwitchedByIgnition" SG_ 1646 KL_HYB_ASV_hinten_schliessen_Anf 0;
BA_ "GenSigSendType" SG_ 1646 KL_HYB_ASV_vorne_schliessen_Anf 3;
BA_ "GenSigSwitchedByIgnition" SG_ 1646 KL_HYB_ASV_vorne_schliessen_Anf 0;
BA_ "GenSigSendType" SG_ 1646 KL_I_Geblaese_Fond 3;
BA_ "GenSigSwitchedByIgnition" SG_ 1646 KL_I_Geblaese_Fond 0;
BA_ "Fehlerwert" SG_ 1646 KL_I_Geblaese_Fond 255;
BA_ "GenSigSendType" SG_ 1646 KL_Innen_Temp 0;
BA_ "GenSigStartValue" SG_ 1646 KL_Innen_Temp 254;
BA_ "GenSigSwitchedByIgnition" SG_ 1646 KL_Innen_Temp 0;
BA_ "Fehlerwert" SG_ 1646 KL_Innen_Temp 255;
BA_ "GenSigSendType" SG_ 1646 KL_Kompressorkupplung 3;
BA_ "GenSigSwitchedByIgnition" SG_ 1646 KL_Kompressorkupplung 0;
BA_ "GenSigSendType" SG_ 1646 KL_Magnetventil 3;
BA_ "GenSigSwitchedByIgnition" SG_ 1646 KL_Magnetventil 0;
BA_ "GenSigSendType" SG_ 1646 KL_Restwaerme_aktiv 3;
BA_ "GenSigSwitchedByIgnition" SG_ 1646 KL_Restwaerme_aktiv 0;
BA_ "GenSigSendType" SG_ 1646 KL_SIH_LEH_Verteilung_VL 3;
BA_ "GenSigSwitchedByIgnition" SG_ 1646 KL_SIH_LEH_Verteilung_VL 0;
BA_ "GenSigSendType" SG_ 1646 KL_SIH_LEH_Verteilung_VR 3;
BA_ "GenSigSwitchedByIgnition" SG_ 1646 KL_SIH_LEH_Verteilung_VR 0;
BA_ "GenSigSendType" SG_ 1646 KL_SIH_LEL_Verteilung_VL 3;
BA_ "GenSigSwitchedByIgnition" SG_ 1646 KL_SIH_LEL_Verteilung_VL 0;
BA_ "GenSigSendType" SG_ 1646 KL_SIH_LEL_Verteilung_VR 3;
BA_ "GenSigSwitchedByIgnition" SG_ 1646 KL_SIH_LEL_Verteilung_VR 0;
BA_ "GenSigSendType" SG_ 1646 KL_Solarluefter_aktiv 3;
BA_ "GenSigSwitchedByIgnition" SG_ 1646 KL_Solarluefter_aktiv 0;
BA_ "GenSigSendType" SG_ 1646 KL_Status_Beduftung 3;
BA_ "GenSigSwitchedByIgnition" SG_ 1646 KL_Status_Beduftung 0;
BA_ "GenSigSendType" SG_ 1646 KL_Status_Ionisator_Front 3;
BA_ "GenSigSwitchedByIgnition" SG_ 1646 KL_Status_Ionisator_Front 0;
BA_ "GenSigSendType" SG_ 1646 KL_STH_aktiv 3;
BA_ "GenSigSwitchedByIgnition" SG_ 1646 KL_STH_aktiv 0;
BA_ "GenSigSendType" SG_ 1646 KL_STH_Ansteuerung 3;
BA_ "GenSigSwitchedByIgnition" SG_ 1646 KL_STH_Ansteuerung 0;
BA_ "GenSigSendType" SG_ 1646 KL_STH_Betriebsdauer 3;
BA_ "GenSigSwitchedByIgnition" SG_ 1646 KL_STH_Betriebsdauer 0;
BA_ "GenSigSendType" SG_ 1646 KL_STH_Timer_Status 3;
BA_ "GenSigSwitchedByIgnition" SG_ 1646 KL_STH_Timer_Status 0;
BA_ "GenSigSendType" SG_ 1646 KL_STL_aktiv 3;
BA_ "GenSigSwitchedByIgnition" SG_ 1646 KL_STL_aktiv 0;
BA_ "GenSigSendType" SG_ 1646 KL_Umluft_Taste 3;
BA_ "GenSigSwitchedByIgnition" SG_ 1646 KL_Umluft_Taste 0;
BA_ "GenSigSendType" SG_ 1646 KL_WaPu 3;
BA_ "GenSigSwitchedByIgnition" SG_ 1646 KL_WaPu 0;
BA_ "GenSigSendType" SG_ 1663 KL_Absperrventil_Fond 3;
BA_ "GenSigSwitchedByIgnition" SG_ 1663 KL_Absperrventil_Fond 0;
BA_ "GenSigSendType" SG_ 1663 KL_Einheiten 3;
BA_ "GenSigSwitchedByIgnition" SG_ 1663 KL_Einheiten 0;
BA_ "GenSigSendType" SG_ 1663 KL_Fond_li_reduziert 3;
BA_ "GenSigSwitchedByIgnition" SG_ 1663 KL_Fond_li_reduziert 0;
BA_ "GenSigSendType" SG_ 1663 KL_Fond_re_reduziert 3;
BA_ "GenSigSwitchedByIgnition" SG_ 1663 KL_Fond_re_reduziert 0;
BA_ "GenSigSendType" SG_ 1663 KL_Fondbed_vorne_aktiv 3;
BA_ "GenSigSwitchedByIgnition" SG_ 1663 KL_Fondbed_vorne_aktiv 0;
BA_ "GenSigSendType" SG_ 1663 KL_Gebl_Verst_Abs_Modus 0;
BA_ "GenSigSwitchedByIgnition" SG_ 1663 KL_Gebl_Verst_Abs_Modus 0;
BA_ "GenSigSendType" SG_ 1663 KL_Geblaesespg_Fond 3;
BA_ "GenSigStartValue" SG_ 1663 KL_Geblaesespg_Fond 254;
BA_ "GenSigSwitchedByIgnition" SG_ 1663 KL_Geblaesespg_Fond 0;
BA_ "GenSigSendType" SG_ 1663 KL_Heizverbraucher_aus 3;
BA_ "GenSigSwitchedByIgnition" SG_ 1663 KL_Heizverbraucher_aus 0;
BA_ "GenSigSendType" SG_ 1663 KL_Heizverbraucher_Notaus 3;
BA_ "GenSigSwitchedByIgnition" SG_ 1663 KL_Heizverbraucher_Notaus 0;
BA_ "GenSigSendType" SG_ 1663 KL_ICO2_Sensor_defekt 3;
BA_ "GenSigSwitchedByIgnition" SG_ 1663 KL_ICO2_Sensor_defekt 0;
BA_ "GenSigSendType" SG_ 1663 KL_Kindersicherung 3;
BA_ "GenSigSwitchedByIgnition" SG_ 1663 KL_Kindersicherung 0;
BA_ "GenSigSendType" SG_ 1663 KL_Mod_Display_li 3;
BA_ "GenSigSwitchedByIgnition" SG_ 1663 KL_Mod_Display_li 0;
BA_ "GenSigSendType" SG_ 1663 KL_Mod_Display_re 3;
BA_ "GenSigSwitchedByIgnition" SG_ 1663 KL_Mod_Display_re 0;
BA_ "GenSigSendType" SG_ 1663 KL_SH_HL_Lastabschaltung 3;
BA_ "GenSigSwitchedByIgnition" SG_ 1663 KL_SH_HL_Lastabschaltung 0;
BA_ "GenSigSendType" SG_ 1663 KL_SH_HR_Lastabschaltung 3;
BA_ "GenSigSwitchedByIgnition" SG_ 1663 KL_SH_HR_Lastabschaltung 0;
BA_ "GenSigSendType" SG_ 1663 KL_Sollausblastemp_HL 3;
BA_ "GenSigStartValue" SG_ 1663 KL_Sollausblastemp_HL 1022;
BA_ "GenSigSwitchedByIgnition" SG_ 1663 KL_Sollausblastemp_HL 0;
BA_ "Fehlerwert" SG_ 1663 KL_Sollausblastemp_HL 1023;
BA_ "GenSigSendType" SG_ 1663 KL_Sollausblastemp_HR 3;
BA_ "GenSigStartValue" SG_ 1663 KL_Sollausblastemp_HR 1022;
BA_ "GenSigSwitchedByIgnition" SG_ 1663 KL_Sollausblastemp_HR 0;
BA_ "Fehlerwert" SG_ 1663 KL_Sollausblastemp_HR 1023;
BA_ "GenSigSendType" SG_ 1663 KL_Umluft 3;
BA_ "GenSigStartValue" SG_ 1663 KL_Umluft 254;
BA_ "GenSigSwitchedByIgnition" SG_ 1663 KL_Umluft 0;
BA_ "Fehlerwert" SG_ 1663 KL_Umluft 255;
BA_REL_ "GenSigTimeoutTime" BU_SG_REL_ CGS SG_ 324 Getriebe_16_CRC 500;
BA_REL_ "GenSigTimeoutTime" BU_SG_REL_ CGS SG_ 324 Getriebe_16_BZ 500;
BA_REL_ "GenSigTimeoutTime" BU_SG_REL_ CGS SG_ 324 GE_Ist_Fahrstufe 500;
BA_REL_ "GenSigTimeoutTime" BU_SG_REL_ CGS SG_ 324 GE_Testparameter_1 500;
BA_REL_ "GenSigTimeoutTime" BU_SG_REL_ CGS SG_ 324 GE_Testparameter_2 500;
BA_REL_ "GenSigTimeoutTime" BU_SG_REL_ CGS SG_ 324 GE_Test_Freigabe 500;
BA_REL_ "GenSigTimeoutTime" BU_SG_REL_ CGS SG_ 324 GE_N_Haltephase 500;
BA_REL_ "GenSigTimeoutTime" BU_SG_REL_ CGS SG_ 324 GE_WH_Abschalten 500;
BA_REL_ "GenSigTimeoutTime" BU_SG_REL_ CGS SG_ 324 GE_Soll_Haltemagnet 500;
BA_REL_ "GenSigTimeoutTime" BU_SG_REL_ CGS SG_ 324 GE_WH_Sperre 500;
BA_REL_ "GenSigTimeoutTime" BU_SG_REL_ CGS SG_ 960 Klemmen_Status_01_CRC 1000;
BA_REL_ "GenSigTimeoutTime" BU_SG_REL_ CGS SG_ 960 Klemmen_Status_01_BZ 1000;
BA_REL_ "GenSigTimeoutTime" BU_SG_REL_ CGS SG_ 960 ZAS_Kl_15 1000;
BA_REL_ "GenSigTimeoutTime" BU_SG_REL_ CGS SG_ 1646 KL_Innen_Temp 5000;
BA_REL_ "GenSigTimeoutTime" BU_SG_REL_ HUD SG_ 2463978614 KAS_Status 2000;
BA_REL_ "GenSigTimeoutTime" BU_SG_REL_ HUD SG_ 2463978614 KAS_Anzeige_Info_links 2000;
BA_REL_ "GenSigTimeoutTime" BU_SG_REL_ HUD SG_ 2463978614 KAS_Anzeige_Info_rechts 2000;
BA_REL_ "GenSigTimeoutTime" BU_SG_REL_ HUD SG_ 2463978614 KAS_Anzeige_Warnung 2000;
BA_REL_ "GenSigTimeoutTime" BU_SG_REL_ HUD SG_ 960 ZAS_Kl_15 1000;
BA_REL_ "GenSigTimeoutTime" BU_SG_REL_ Kombi SG_ 379 FCU_Warn_H2_Konzentrat_Motorraum 1000;
BA_REL_ "GenSigTimeoutTime" BU_SG_REL_ Kombi SG_ 2463978770 FCU_TK_Wasserstoffmasse_Netto 1000;
BA_REL_ "GenSigTimeoutTime" BU_SG_REL_ Kombi SG_ 2463978770 FCU_TK_H2_Fuellstand 1000;
BA_REL_ "GenSigTimeoutTime" BU_SG_REL_ Kombi SG_ 2463978770 FCU_TK_H2_Nachtanken_aktiv 1000;
BA_REL_ "GenSigTimeoutTime" BU_SG_REL_ Kombi SG_ 2463978770 FCU_TK_Meldungen 1000;
BA_REL_ "GenSigTimeoutTime" BU_SG_REL_ Kombi SG_ 2463978770 FCU_TK_Tankwarnungen 1000;
BA_REL_ "GenSigTimeoutTime" BU_SG_REL_ Kombi SG_ 606 FCU_Verbrauch_FC_Nebag 500;
BA_REL_ "GenSigTimeoutTime" BU_SG_REL_ Kombi SG_ 606 FCU_Verbrauch_FC_Nebag_Ueberlauf 500;
BA_REL_ "GenSigTimeoutTime" BU_SG_REL_ Kombi SG_ 606 FCU_Verbrauch_H2 500;
BA_REL_ "GenSigTimeoutTime" BU_SG_REL_ Kombi SG_ 606 FCU_Verbrauch_H2_Ueberlauf 500;
BA_REL_ "GenSigTimeoutTime" BU_SG_REL_ Kombi SG_ 606 FCU_Verbrauch_FC 500;
BA_REL_ "GenSigTimeoutTime" BU_SG_REL_ Kombi SG_ 606 FCU_Verbrauch_FC_Ueberlauf 500;
BA_REL_ "GenSigTimeoutTime" BU_SG_REL_ Kombi SG_ 607 FCU_TK_Fuellstand 500;
BA_REL_ "GenSigTimeoutTime" BU_SG_REL_ Kombi SG_ 607 FCU_Verb_FC_Nebag_Masaequi_Ueb 500;
BA_REL_ "GenSigTimeoutTime" BU_SG_REL_ Kombi SG_ 607 FCU_Verb_FC_Nebag_Masaequi 500;
BA_REL_ "GenSigTimeoutTime" BU_SG_REL_ Kombi SG_ 607 FCU_Anzeigeverbrauch_H2 500;
BA_REL_ "GenSigTimeoutTime" BU_SG_REL_ Kombi SG_ 707 FA_Warnung_Transportniveau 800;
BA_REL_ "GenSigTimeoutTime" BU_SG_REL_ Kombi SG_ 707 EFP_Anf_Kuehlklappenwarnung 800;
BA_REL_ "GenSigTimeoutTime" BU_SG_REL_ Kombi SG_ 707 FDR_M_HL_02 800;
BA_REL_ "GenSigTimeoutTime" BU_SG_REL_ Kombi SG_ 707 FDR_M_HR_02 800;
BA_REL_ "GenSigTimeoutTime" BU_SG_REL_ Kombi SG_ 707 FDR_M_VL_02 800;
BA_REL_ "GenSigTimeoutTime" BU_SG_REL_ Kombi SG_ 707 FDR_M_VR_02 800;
BA_REL_ "GenSigTimeoutTime" BU_SG_REL_ Kombi SG_ 2589283684 FoD_Transmission_Info 5000;
BA_REL_ "GenSigTimeoutTime" BU_SG_REL_ Kombi SG_ 2589283684 FoD_Anz_Funktionsabschaltung 5000;
BA_REL_ "GenSigTimeoutTime" BU_SG_REL_ Kombi SG_ 2463978599 MKE_Fahrzeit 5000;
BA_REL_ "GenSigTimeoutTime" BU_SG_REL_ Kombi SG_ 968 GE_Status_PaddleNeutral 2000;
BA_REL_ "GenSigTimeoutTime" BU_SG_REL_ Kombi SG_ 299 GRA_Hauptschalter 2000;
BA_REL_ "GenSigTimeoutTime" BU_SG_REL_ Kombi SG_ 299 GRA_Limiter 2000;
BA_REL_ "GenSigTimeoutTime" BU_SG_REL_ Kombi SG_ 310 HAL_01_CRC 1000;
BA_REL_ "GenSigTimeoutTime" BU_SG_REL_ Kombi SG_ 310 HAL_01_BZ 1000;
BA_REL_ "GenSigTimeoutTime" BU_SG_REL_ Kombi SG_ 310 HAL_Warnungen 1000;
BA_REL_ "GenSigTimeoutTime" BU_SG_REL_ Kombi SG_ 1412 HSP_01_CRC 2000;
BA_REL_ "GenSigTimeoutTime" BU_SG_REL_ Kombi SG_ 1412 HSP_01_BZ 2000;
BA_REL_ "GenSigTimeoutTime" BU_SG_REL_ Kombi SG_ 1412 HSP_Warnung_LED 2000;
BA_REL_ "GenSigTimeoutTime" BU_SG_REL_ Kombi SG_ 1412 HSP_Warnung_Text 2000;
BA_REL_ "GenSigTimeoutTime" BU_SG_REL_ Kombi SG_ 1609 HUD_Aktiv 5000;
BA_REL_ "GenSigTimeoutTime" BU_SG_REL_ Kombi SG_ 1283 HVK_01_CRC 1000;
BA_REL_ "GenSigTimeoutTime" BU_SG_REL_ Kombi SG_ 1283 HVK_01_BZ 1000;
BA_REL_ "GenSigTimeoutTime" BU_SG_REL_ Kombi SG_ 1283 HVK_HV_Netz_Warnungen 1000;
BA_REL_ "GenSigTimeoutTime" BU_SG_REL_ Kombi SG_ 1283 HVK_Gesamtst_Spgfreiheit 1000;
BA_REL_ "GenSigTimeoutTime" BU_SG_REL_ Kombi SG_ 1283 HVK_Iso_Fehlerstatus 1000;
BA_REL_ "GenSigTimeoutTime" BU_SG_REL_ Kombi SG_ 1381 HVLM_Ladesystemhinweise 5000;
BA_REL_ "GenSigTimeoutTime" BU_SG_REL_ Kombi SG_ 1381 HVLM_Zustand_LED 5000;
BA_REL_ "GenSigTimeoutTime" BU_SG_REL_ Kombi SG_ 1381 HVLM_Ladetexte 5000;
BA_REL_ "GenSigTimeoutTime" BU_SG_REL_ Kombi SG_ 312 Parken_Fahrbereitschaft_Anf 2000;
BA_REL_ "GenSigTimeoutTime" BU_SG_REL_ Kombi SG_ 2463978614 KAS_Status 2000;
BA_REL_ "GenSigTimeoutTime" BU_SG_REL_ Kombi SG_ 2463978614 KAS_Anzeige_Info_links 2000;
BA_REL_ "GenSigTimeoutTime" BU_SG_REL_ Kombi SG_ 2463978614 KAS_Anzeige_Info_rechts 2000;
BA_REL_ "GenSigTimeoutTime" BU_SG_REL_ Kombi SG_ 2463978614 KAS_Anzeige_Warnung 2000;
BA_REL_ "GenSigTimeoutTime" BU_SG_REL_ Kombi SG_ 2463978614 KAS_Texte 2000;
BA_REL_ "GenSigTimeoutTime" BU_SG_REL_ Kombi SG_ 497 Schluesselnr_Personalisierung 5000;
BA_REL_ "GenSigTimeoutTime" BU_SG_REL_ Kombi SG_ 1424 FBS_Warn_Schluessel_Batt 2000;
BA_REL_ "GenSigTimeoutTime" BU_SG_REL_ Kombi SG_ 1424 KY_KYL_Fahrer_Hinweise 2000;
BA_REL_ "GenSigTimeoutTime" BU_SG_REL_ Kombi SG_ 1424 KY_Keyless_Go_Verbau 2000;
BA_REL_ "GenSigTimeoutTime" BU_SG_REL_ Kombi SG_ 1424 KYL_Warn_kein_Schluessel 2000;
BA_REL_ "GenSigTimeoutTime" BU_SG_REL_ Kombi SG_ 1424 KYL_Warn_Kessy_defekt 2000;
BA_REL_ "GenSigTimeoutTime" BU_SG_REL_ Kombi SG_ 1424 KYL_Warn_Notzuendschloss 2000;
BA_REL_ "GenSigTimeoutTime" BU_SG_REL_ Kombi SG_ 1424 KY_NFC_Fahrer_Hinweise 2000;
BA_REL_ "GenSigTimeoutTime" BU_SG_REL_ Kombi SG_ 1424 KST_Wegstrecke_Challenge 2000;
BA_REL_ "GenSigTimeoutTime" BU_SG_REL_ Kombi SG_ 960 Klemmen_Status_01_CRC 1000;
BA_REL_ "GenSigTimeoutTime" BU_SG_REL_ Kombi SG_ 960 Klemmen_Status_01_BZ 1000;
BA_REL_ "GenSigTimeoutTime" BU_SG_REL_ Kombi SG_ 960 RSt_Fahrerhinweise 1000;
BA_REL_ "GenSigTimeoutTime" BU_SG_REL_ Kombi SG_ 960 ZAS_Kl_S 1000;
BA_REL_ "GenSigTimeoutTime" BU_SG_REL_ Kombi SG_ 960 ZAS_Kl_15 1000;
BA_REL_ "GenSigTimeoutTime" BU_SG_REL_ Kombi SG_ 960 ZAS_Kl_50_Startanforderung 1000;
BA_REL_ "GenSigTimeoutTime" BU_SG_REL_ Kombi SG_ 960 BCM_Remotestart_KL15_Anf 1000;
BA_REL_ "GenSigTimeoutTime" BU_SG_REL_ Kombi SG_ 960 KST_Warn_P1_ZST_def 1000;
BA_REL_ "GenSigTimeoutTime" BU_SG_REL_ Kombi SG_ 960 KST_Warn_P2_ZST_def 1000;
BA_REL_ "GenSigTimeoutTime" BU_SG_REL_ Kombi SG_ 960 KST_Fahrerhinweis_1 1000;
BA_REL_ "GenSigTimeoutTime" BU_SG_REL_ Kombi SG_ 960 KST_Fahrerhinweis_2 1000;
BA_REL_ "GenSigTimeoutTime" BU_SG_REL_ Kombi SG_ 960 BCM_Ausparken_Betrieb 1000;
BA_REL_ "GenSigTimeoutTime" BU_SG_REL_ Kombi SG_ 960 KST_Fahrerhinweis_5 1000;
BA_REL_ "GenSigTimeoutTime" BU_SG_REL_ Kombi SG_ 960 KST_Fahrerhinweis_6 1000;
BA_REL_ "GenSigTimeoutTime" BU_SG_REL_ Kombi SG_ 1420 KST_Txt_P_Gang 5000;
BA_REL_ "GenSigTimeoutTime" BU_SG_REL_ Kombi SG_ 1420 KST_Txt_Panikabschaltung 5000;
BA_REL_ "GenSigTimeoutTime" BU_SG_REL_ Kombi SG_ 1420 KST_Txt_Komfortabschaltung 5000;
BA_REL_ "GenSigTimeoutTime" BU_SG_REL_ Kombi SG_ 1420 KST_Unterdr_Zuendungsmeldung 5000;
BA_REL_ "GenSigTimeoutTime" BU_SG_REL_ Kombi SG_ 1420 KST_aut_Abschaltung_Zuendung 5000;
BA_REL_ "GenSigTimeoutTime" BU_SG_REL_ Kombi SG_ 1646 KL_STL_aktiv 5000;
BA_REL_ "GenSigTimeoutTime" BU_SG_REL_ Kombi SG_ 1646 KL_STH_aktiv 5000;
BA_REL_ "GenSigTimeoutTime" BU_SG_REL_ Kombi SG_ 1646 KL_Geblaese_Fond_Status 5000;
BA_REL_ "GenSigTimeoutTime" BU_SG_REL_ Kombi SG_ 1646 KL_STH_Betriebsdauer 5000;
BA_REL_ "GenSigTimeoutTime" BU_SG_REL_ Kombi SG_ 1646 KL_Geblaese_Status 5000;
BA_REL_ "GenSigTimeoutTime" BU_SG_REL_ Kombi SG_ 1646 KL_STH_Timer_Status 5000;
BA_REL_ "GenSigTimeoutTime" BU_SG_REL_ Kombi SG_ 1663 KL_ICO2_Sensor_defekt 5000;
BA_REL_ "GenSigTimeoutTime" BU_SG_REL_ Kombi_LB SG_ 707 FDR_04_CRC 800;
BA_REL_ "GenSigTimeoutTime" BU_SG_REL_ Kombi_LB SG_ 707 FDR_04_BZ 800;
BA_REL_ "GenSigTimeoutTime" BU_SG_REL_ Kombi_LB SG_ 707 FA_Warnung_Transportniveau 800;
BA_REL_ "GenSigTimeoutTime" BU_SG_REL_ Kombi_LB SG_ 707 EFP_Anf_Kuehlklappenwarnung 800;
BA_REL_ "GenSigTimeoutTime" BU_SG_REL_ Kombi_LB SG_ 707 FDR_M_HL_02 800;
BA_REL_ "GenSigTimeoutTime" BU_SG_REL_ Kombi_LB SG_ 707 FDR_M_HR_02 800;
BA_REL_ "GenSigTimeoutTime" BU_SG_REL_ Kombi_LB SG_ 707 FDR_M_VL_02 800;
BA_REL_ "GenSigTimeoutTime" BU_SG_REL_ Kombi_LB SG_ 707 FDR_M_VR_02 800;
BA_REL_ "GenSigTimeoutTime" BU_SG_REL_ Kombi_LB SG_ 2589283684 FoD_Transmission_Info 5000;
BA_REL_ "GenSigTimeoutTime" BU_SG_REL_ Kombi_LB SG_ 2589283684 FoD_Anz_Funktionsabschaltung 5000;
BA_REL_ "GenSigTimeoutTime" BU_SG_REL_ Kombi_LB SG_ 2463978599 MKE_Fahrzeit 5000;
BA_REL_ "GenSigTimeoutTime" BU_SG_REL_ Kombi_LB SG_ 968 GE_LaunchControl_LB 2000;
BA_REL_ "GenSigTimeoutTime" BU_SG_REL_ Kombi_LB SG_ 324 WH_gespeicherte_Fahrstufe 500;
BA_REL_ "GenSigTimeoutTime" BU_SG_REL_ Kombi_LB SG_ 324 WH_SensorPos_roh 500;
BA_REL_ "GenSigTimeoutTime" BU_SG_REL_ Kombi_LB SG_ 324 WH_P_Taste 500;
BA_REL_ "GenSigTimeoutTime" BU_SG_REL_ Kombi_LB SG_ 324 WH_Warnung_02 500;
BA_REL_ "GenSigTimeoutTime" BU_SG_REL_ Kombi_LB SG_ 324 WH_Warnung_03 500;
BA_REL_ "GenSigTimeoutTime" BU_SG_REL_ Kombi_LB SG_ 299 GRA_Hauptschalter 2000;
BA_REL_ "GenSigTimeoutTime" BU_SG_REL_ Kombi_LB SG_ 299 GRA_Limiter 2000;
BA_REL_ "GenSigTimeoutTime" BU_SG_REL_ Kombi_LB SG_ 310 HAL_01_CRC 1000;
BA_REL_ "GenSigTimeoutTime" BU_SG_REL_ Kombi_LB SG_ 310 HAL_01_BZ 1000;
BA_REL_ "GenSigTimeoutTime" BU_SG_REL_ Kombi_LB SG_ 310 HAL_VZ_Radwinkel 1000;
BA_REL_ "GenSigTimeoutTime" BU_SG_REL_ Kombi_LB SG_ 310 HAL_Radwinkel 1000;
BA_REL_ "GenSigTimeoutTime" BU_SG_REL_ Kombi_LB SG_ 310 HAL_Warnungen 1000;
BA_REL_ "GenSigTimeoutTime" BU_SG_REL_ Kombi_LB SG_ 310 HAL_Status_2 1000;
BA_REL_ "GenSigTimeoutTime" BU_SG_REL_ Kombi_LB SG_ 1283 HVK_01_CRC 1000;
BA_REL_ "GenSigTimeoutTime" BU_SG_REL_ Kombi_LB SG_ 1283 HVK_01_BZ 1000;
BA_REL_ "GenSigTimeoutTime" BU_SG_REL_ Kombi_LB SG_ 1283 HVK_HV_Netz_Warnungen 1000;
BA_REL_ "GenSigTimeoutTime" BU_SG_REL_ Kombi_LB SG_ 1283 HVK_Gesamtst_Spgfreiheit 1000;
BA_REL_ "GenSigTimeoutTime" BU_SG_REL_ Kombi_LB SG_ 1381 HVLM_Ladesystemhinweise 5000;
BA_REL_ "GenSigTimeoutTime" BU_SG_REL_ Kombi_LB SG_ 1381 HVLM_Zustand_LED 5000;
BA_REL_ "GenSigTimeoutTime" BU_SG_REL_ Kombi_LB SG_ 1381 HVLM_Ladetexte 5000;
BA_REL_ "GenSigTimeoutTime" BU_SG_REL_ Kombi_LB SG_ 312 Parken_Fahrbereitschaft_Anf 2000;
BA_REL_ "GenSigTimeoutTime" BU_SG_REL_ Kombi_LB SG_ 2463978614 KAS_Status 2000;
BA_REL_ "GenSigTimeoutTime" BU_SG_REL_ Kombi_LB SG_ 2463978614 KAS_Anzeige_Info_links 2000;
BA_REL_ "GenSigTimeoutTime" BU_SG_REL_ Kombi_LB SG_ 2463978614 KAS_Anzeige_Info_rechts 2000;
BA_REL_ "GenSigTimeoutTime" BU_SG_REL_ Kombi_LB SG_ 2463978614 KAS_Anzeige_Warnung 2000;
BA_REL_ "GenSigTimeoutTime" BU_SG_REL_ Kombi_LB SG_ 2463978614 KAS_Texte 2000;
BA_REL_ "GenSigTimeoutTime" BU_SG_REL_ Kombi_LB SG_ 497 Schluesselnr_Personalisierung 5000;
BA_REL_ "GenSigTimeoutTime" BU_SG_REL_ Kombi_LB SG_ 1424 FBS_Warn_Schluessel_Batt 2000;
BA_REL_ "GenSigTimeoutTime" BU_SG_REL_ Kombi_LB SG_ 1424 KY_KYL_Fahrer_Hinweise 2000;
BA_REL_ "GenSigTimeoutTime" BU_SG_REL_ Kombi_LB SG_ 1424 KY_Keyless_Go_Verbau 2000;
BA_REL_ "GenSigTimeoutTime" BU_SG_REL_ Kombi_LB SG_ 1424 KYL_Warn_kein_Schluessel 2000;
BA_REL_ "GenSigTimeoutTime" BU_SG_REL_ Kombi_LB SG_ 1424 KYL_Warn_Kessy_defekt 2000;
BA_REL_ "GenSigTimeoutTime" BU_SG_REL_ Kombi_LB SG_ 1424 KYL_Warn_Notzuendschloss 2000;
BA_REL_ "GenSigTimeoutTime" BU_SG_REL_ Kombi_LB SG_ 1424 KY_NFC_Fahrer_Hinweise 2000;
BA_REL_ "GenSigTimeoutTime" BU_SG_REL_ Kombi_LB SG_ 1424 KST_Wegstrecke_Challenge 2000;
BA_REL_ "GenSigTimeoutTime" BU_SG_REL_ Kombi_LB SG_ 960 Klemmen_Status_01_CRC 1000;
BA_REL_ "GenSigTimeoutTime" BU_SG_REL_ Kombi_LB SG_ 960 Klemmen_Status_01_BZ 1000;
BA_REL_ "GenSigTimeoutTime" BU_SG_REL_ Kombi_LB SG_ 960 RSt_Fahrerhinweise 1000;
BA_REL_ "GenSigTimeoutTime" BU_SG_REL_ Kombi_LB SG_ 960 ZAS_Kl_S 1000;
BA_REL_ "GenSigTimeoutTime" BU_SG_REL_ Kombi_LB SG_ 960 ZAS_Kl_15 1000;
BA_REL_ "GenSigTimeoutTime" BU_SG_REL_ Kombi_LB SG_ 960 ZAS_Kl_50_Startanforderung 1000;
BA_REL_ "GenSigTimeoutTime" BU_SG_REL_ Kombi_LB SG_ 960 KST_Warn_P1_ZST_def 1000;
BA_REL_ "GenSigTimeoutTime" BU_SG_REL_ Kombi_LB SG_ 960 KST_Warn_P2_ZST_def 1000;
BA_REL_ "GenSigTimeoutTime" BU_SG_REL_ Kombi_LB SG_ 960 KST_Fahrerhinweis_1 1000;
BA_REL_ "GenSigTimeoutTime" BU_SG_REL_ Kombi_LB SG_ 960 KST_Fahrerhinweis_2 1000;
BA_REL_ "GenSigTimeoutTime" BU_SG_REL_ Kombi_LB SG_ 960 BCM_Ausparken_Betrieb 1000;
BA_REL_ "GenSigTimeoutTime" BU_SG_REL_ Kombi_LB SG_ 960 KST_Fahrerhinweis_5 1000;
BA_REL_ "GenSigTimeoutTime" BU_SG_REL_ Kombi_LB SG_ 960 KST_Fahrerhinweis_6 1000;
BA_REL_ "GenSigTimeoutTime" BU_SG_REL_ Kombi_LB SG_ 1420 KST_Txt_P_Gang 5000;
BA_REL_ "GenSigTimeoutTime" BU_SG_REL_ Kombi_LB SG_ 1420 KST_Txt_Panikabschaltung 5000;
BA_REL_ "GenSigTimeoutTime" BU_SG_REL_ Kombi_LB SG_ 1420 KST_Txt_Komfortabschaltung 5000;
BA_REL_ "GenSigTimeoutTime" BU_SG_REL_ Kombi_LB SG_ 1420 KST_Unterdr_Zuendungsmeldung 5000;
BA_REL_ "GenSigTimeoutTime" BU_SG_REL_ Kombi_LB SG_ 1420 KST_aut_Abschaltung_Zuendung 5000;
BA_REL_ "GenSigTimeoutTime" BU_SG_REL_ Kombi_LB SG_ 1646 KL_STL_aktiv 5000;
BA_REL_ "GenSigTimeoutTime" BU_SG_REL_ Kombi_LB SG_ 1646 KL_Geblaese_Fond_Status 5000;
BA_REL_ "GenSigTimeoutTime" BU_SG_REL_ Kombi_LB SG_ 1646 KL_Geblaese_Status 5000;
BA_REL_ "GenSigTimeoutTime" BU_SG_REL_ Kombi_LB SG_ 1663 KL_ICO2_Sensor_defekt 5000;
BA_REL_ "GenSigTimeoutTime" BU_SG_REL_ Kombi_PAG SG_ 707 FDR_04_CRC 800;
BA_REL_ "GenSigTimeoutTime" BU_SG_REL_ Kombi_PAG SG_ 707 FDR_04_BZ 800;
BA_REL_ "GenSigTimeoutTime" BU_SG_REL_ Kombi_PAG SG_ 707 FA_Warnung_Transportniveau 800;
BA_REL_ "GenSigTimeoutTime" BU_SG_REL_ Kombi_PAG SG_ 707 eAWS_Warnmeldung_Prio3 800;
BA_REL_ "GenSigTimeoutTime" BU_SG_REL_ Kombi_PAG SG_ 707 EFP_Anf_Kuehlklappenwarnung 800;
BA_REL_ "GenSigTimeoutTime" BU_SG_REL_ Kombi_PAG SG_ 707 FDR_M_HL_02 800;
BA_REL_ "GenSigTimeoutTime" BU_SG_REL_ Kombi_PAG SG_ 707 FDR_M_HR_02 800;
BA_REL_ "GenSigTimeoutTime" BU_SG_REL_ Kombi_PAG SG_ 707 FDR_M_VL_02 800;
BA_REL_ "GenSigTimeoutTime" BU_SG_REL_ Kombi_PAG SG_ 707 FDR_M_VR_02 800;
BA_REL_ "GenSigTimeoutTime" BU_SG_REL_ Kombi_PAG SG_ 2463978599 MKE_Fahrzeit 5000;
BA_REL_ "GenSigTimeoutTime" BU_SG_REL_ Kombi_PAG SG_ 968 GE_LaunchControl_LB 2000;
BA_REL_ "GenSigTimeoutTime" BU_SG_REL_ Kombi_PAG SG_ 968 GE_Status_PaddleNeutral 2000;
BA_REL_ "GenSigTimeoutTime" BU_SG_REL_ Kombi_PAG SG_ 299 GRA_Hauptschalter 2000;
BA_REL_ "GenSigTimeoutTime" BU_SG_REL_ Kombi_PAG SG_ 299 GRA_Limiter 2000;
BA_REL_ "GenSigTimeoutTime" BU_SG_REL_ Kombi_PAG SG_ 310 HAL_01_CRC 1000;
BA_REL_ "GenSigTimeoutTime" BU_SG_REL_ Kombi_PAG SG_ 310 HAL_01_BZ 1000;
BA_REL_ "GenSigTimeoutTime" BU_SG_REL_ Kombi_PAG SG_ 310 HAL_Warnungen 1000;
BA_REL_ "GenSigTimeoutTime" BU_SG_REL_ Kombi_PAG SG_ 1609 HUD_Aktiv 5000;
BA_REL_ "GenSigTimeoutTime" BU_SG_REL_ Kombi_PAG SG_ 1609 HUD_Anforderung_Fokus 5000;
BA_REL_ "GenSigTimeoutTime" BU_SG_REL_ Kombi_PAG SG_ 1283 HVK_01_CRC 1000;
BA_REL_ "GenSigTimeoutTime" BU_SG_REL_ Kombi_PAG SG_ 1283 HVK_01_BZ 1000;
BA_REL_ "GenSigTimeoutTime" BU_SG_REL_ Kombi_PAG SG_ 1283 HVK_HV_Netz_Warnungen 1000;
BA_REL_ "GenSigTimeoutTime" BU_SG_REL_ Kombi_PAG SG_ 1283 HVK_Gesamtst_Spgfreiheit 1000;
BA_REL_ "GenSigTimeoutTime" BU_SG_REL_ Kombi_PAG SG_ 1283 HVK_Iso_Fehlerstatus 1000;
BA_REL_ "GenSigTimeoutTime" BU_SG_REL_ Kombi_PAG SG_ 1381 HVLM_Ladesystemhinweise 5000;
BA_REL_ "GenSigTimeoutTime" BU_SG_REL_ Kombi_PAG SG_ 1381 HVLM_Zustand_LED 5000;
BA_REL_ "GenSigTimeoutTime" BU_SG_REL_ Kombi_PAG SG_ 1381 HVLM_Ladetexte 5000;
BA_REL_ "GenSigTimeoutTime" BU_SG_REL_ Kombi_PAG SG_ 312 Parken_Fahrbereitschaft_Anf 2000;
BA_REL_ "GenSigTimeoutTime" BU_SG_REL_ Kombi_PAG SG_ 2463978614 KAS_Status 2000;
BA_REL_ "GenSigTimeoutTime" BU_SG_REL_ Kombi_PAG SG_ 2463978614 KAS_Anzeige_Info_links 2000;
BA_REL_ "GenSigTimeoutTime" BU_SG_REL_ Kombi_PAG SG_ 2463978614 KAS_Anzeige_Info_rechts 2000;
BA_REL_ "GenSigTimeoutTime" BU_SG_REL_ Kombi_PAG SG_ 2463978614 KAS_Anzeige_Warnung 2000;
BA_REL_ "GenSigTimeoutTime" BU_SG_REL_ Kombi_PAG SG_ 2463978614 KAS_Texte 2000;
BA_REL_ "GenSigTimeoutTime" BU_SG_REL_ Kombi_PAG SG_ 497 Schluesselnr_Personalisierung 5000;
BA_REL_ "GenSigTimeoutTime" BU_SG_REL_ Kombi_PAG SG_ 1424 FBS_Warn_Schluessel_Batt 2000;
BA_REL_ "GenSigTimeoutTime" BU_SG_REL_ Kombi_PAG SG_ 1424 KY_KYL_Fahrer_Hinweise 2000;
BA_REL_ "GenSigTimeoutTime" BU_SG_REL_ Kombi_PAG SG_ 1424 KY_Keyless_Go_Verbau 2000;
BA_REL_ "GenSigTimeoutTime" BU_SG_REL_ Kombi_PAG SG_ 1424 KYL_Warn_kein_Schluessel 2000;
BA_REL_ "GenSigTimeoutTime" BU_SG_REL_ Kombi_PAG SG_ 1424 KYL_Warn_Kessy_defekt 2000;
BA_REL_ "GenSigTimeoutTime" BU_SG_REL_ Kombi_PAG SG_ 1424 KYL_Warn_Notzuendschloss 2000;
BA_REL_ "GenSigTimeoutTime" BU_SG_REL_ Kombi_PAG SG_ 1424 KY_NFC_Fahrer_Hinweise 2000;
BA_REL_ "GenSigTimeoutTime" BU_SG_REL_ Kombi_PAG SG_ 1424 KST_Wegstrecke_Challenge 2000;
BA_REL_ "GenSigTimeoutTime" BU_SG_REL_ Kombi_PAG SG_ 960 Klemmen_Status_01_CRC 1000;
BA_REL_ "GenSigTimeoutTime" BU_SG_REL_ Kombi_PAG SG_ 960 Klemmen_Status_01_BZ 1000;
BA_REL_ "GenSigTimeoutTime" BU_SG_REL_ Kombi_PAG SG_ 960 ZAS_Kl_S 1000;
BA_REL_ "GenSigTimeoutTime" BU_SG_REL_ Kombi_PAG SG_ 960 ZAS_Kl_15 1000;
BA_REL_ "GenSigTimeoutTime" BU_SG_REL_ Kombi_PAG SG_ 960 ZAS_Kl_50_Startanforderung 1000;
BA_REL_ "GenSigTimeoutTime" BU_SG_REL_ Kombi_PAG SG_ 960 BCM_Remotestart_KL15_Anf 1000;
BA_REL_ "GenSigTimeoutTime" BU_SG_REL_ Kombi_PAG SG_ 960 KST_Warn_P1_ZST_def 1000;
BA_REL_ "GenSigTimeoutTime" BU_SG_REL_ Kombi_PAG SG_ 960 KST_Warn_P2_ZST_def 1000;
BA_REL_ "GenSigTimeoutTime" BU_SG_REL_ Kombi_PAG SG_ 960 KST_Fahrerhinweis_1 1000;
BA_REL_ "GenSigTimeoutTime" BU_SG_REL_ Kombi_PAG SG_ 960 KST_Fahrerhinweis_2 1000;
BA_REL_ "GenSigTimeoutTime" BU_SG_REL_ Kombi_PAG SG_ 960 BCM_Ausparken_Betrieb 1000;
BA_REL_ "GenSigTimeoutTime" BU_SG_REL_ Kombi_PAG SG_ 960 KST_Fahrerhinweis_5 1000;
BA_REL_ "GenSigTimeoutTime" BU_SG_REL_ Kombi_PAG SG_ 960 KST_Fahrerhinweis_6 1000;
BA_REL_ "GenSigTimeoutTime" BU_SG_REL_ Kombi_PAG SG_ 1420 KST_Txt_P_Gang 5000;
BA_REL_ "GenSigTimeoutTime" BU_SG_REL_ Kombi_PAG SG_ 1420 KST_Txt_Panikabschaltung 5000;
BA_REL_ "GenSigTimeoutTime" BU_SG_REL_ Kombi_PAG SG_ 1420 KST_Txt_Komfortabschaltung 5000;
BA_REL_ "GenSigTimeoutTime" BU_SG_REL_ Kombi_PAG SG_ 1420 KST_Unterdr_Zuendungsmeldung 5000;
BA_REL_ "GenSigTimeoutTime" BU_SG_REL_ Kombi_PAG SG_ 1420 KST_aut_Abschaltung_Zuendung 5000;
BA_REL_ "GenSigTimeoutTime" BU_SG_REL_ Kombi_PAG SG_ 1646 KL_STL_aktiv 5000;
BA_REL_ "GenSigTimeoutTime" BU_SG_REL_ Kombi_PAG SG_ 1646 KL_STH_aktiv 5000;
BA_REL_ "GenSigTimeoutTime" BU_SG_REL_ Kombi_PAG SG_ 1646 KL_Umluft_Taste 5000;
BA_REL_ "GenSigTimeoutTime" BU_SG_REL_ Kombi_PAG SG_ 1646 KL_Geblaese_Fond_Status 5000;
BA_REL_ "GenSigTimeoutTime" BU_SG_REL_ Kombi_PAG SG_ 1646 KL_STH_Betriebsdauer 5000;
BA_REL_ "GenSigTimeoutTime" BU_SG_REL_ Kombi_PAG SG_ 1646 KL_Geblaese_Status 5000;
BA_REL_ "GenSigTimeoutTime" BU_SG_REL_ Kombi_PAG SG_ 1646 KL_STH_Timer_Status 5000;
BA_REL_ "GenSigTimeoutTime" BU_SG_REL_ Kombi_PAG SG_ 1646 KL_FSH_Automatikbetrieb 5000;
BA_REL_ "GenSigTimeoutTime" BU_SG_REL_ Kombi_PAG SG_ 1663 KL_ICO2_Sensor_defekt 5000;
BA_REL_ "GenSigTimeoutTime" BU_SG_REL_ Waehlhebel_SB SG_ 324 Getriebe_16_CRC 500;
BA_REL_ "GenSigTimeoutTime" BU_SG_REL_ Waehlhebel_SB SG_ 324 Getriebe_16_BZ 500;
BA_REL_ "GenSigTimeoutTime" BU_SG_REL_ Waehlhebel_SB SG_ 324 GE_Ist_Fahrstufe 500;
BA_REL_ "GenSigTimeoutTime" BU_SG_REL_ Waehlhebel_SB SG_ 324 GE_Testparameter_1 500;
BA_REL_ "GenSigTimeoutTime" BU_SG_REL_ Waehlhebel_SB SG_ 324 GE_Testparameter_2 500;
BA_REL_ "GenSigTimeoutTime" BU_SG_REL_ Waehlhebel_SB SG_ 324 GE_Test_Freigabe 500;
BA_REL_ "GenSigTimeoutTime" BU_SG_REL_ Waehlhebel_SB SG_ 324 GE_N_Haltephase 500;
BA_REL_ "GenSigTimeoutTime" BU_SG_REL_ Waehlhebel_SB SG_ 324 GE_WH_Abschalten 500;
BA_REL_ "GenSigTimeoutTime" BU_SG_REL_ Waehlhebel_SB SG_ 324 GE_Soll_Haltemagnet 500;
BA_REL_ "GenSigTimeoutTime" BU_SG_REL_ Waehlhebel_SB SG_ 324 GE_WH_Sperre 500;
BA_REL_ "GenSigTimeoutTime" BU_SG_REL_ Waehlhebel_SB SG_ 960 Klemmen_Status_01_CRC 1000;
BA_REL_ "GenSigTimeoutTime" BU_SG_REL_ Waehlhebel_SB SG_ 960 Klemmen_Status_01_BZ 1000;
BA_REL_ "GenSigTimeoutTime" BU_SG_REL_ Waehlhebel_SB SG_ 960 ZAS_Kl_15 1000;
BA_REL_ "GenSigTimeoutTime" BU_SG_REL_ Waehlhebel_SB SG_ 1646 KL_Innen_Temp 5000;
VAL_ 379 FCU_Warn_H2_Konzentrat_Motorraum 0 "Init" 1 "H2_Konzentration_Hoch" 2 "H2_Konzentration_Warnschnwelle" 3 "Drei_Prozent_H2" 4 "Vier_Prozent_H2" 5 "Leak_Check_Shut_Down_failed" 6 "Leak_Check_Start_Up_failed" 7 "reserviert" ;
VAL_ 379 FCU_nicht_verfuegbar 0 "verfuegbar" 1 "nicht_verfuegbar" ;
VAL_ 379 FCU_Startstopp_Anforderung 0 "keine_Anforderung" 1 "Stoppverbot" 2 "Startanforderung" 3 "Stoppanforderung" 4 "Startverbot" 5 "Stoppverbot_weich" 6 "Startwunsch_weich" 7 "Stoppwunsch_weich" 8 "Startverbot_weich" ;
VAL_ 379 FCU_HV_Anf 0 "Init" 1 "HV_Netz_nicht_angefordert" 2 "HV_Netz_angefordert" 3 "Fehler" ;
VAL_ 379 FCU_Klima_Eingr 0 "kein_Eingriff" 1 "Klimakompressor_ausschalten" 2 "Klimakomp_Leistungsreduzierung" 3 "Klimakomp_wegen_Heissleuchte_aus" ;
VAL_ 379 FCU_IstModus 0 "Off" 1 "Standby" 2 "Run" 3 "Sleep" 4 "Blowby" 5 "Fehler_Notabschaltung" 31 "Init" ;
VAL_ 379 FCU_Status_Spgfreiheit 0 "Init" 1 "HV_Komponente_spannungsfrei" 2 "HV_Komp_nicht_spannungsfrei" 3 "Fehler_nicht_spannungsfrei" ;
VAL_ 379 FCU_Fehler_Leistungsreduzierung 0 "kein_Fehler" 1 "Fehler" ;
VAL_ 379 FCU_Fehler_Abschaltanforderung 0 "kein_Fehler" 1 "Fehler" ;
VAL_ 379 FCU_Fehler_Notabschaltung 0 "kein_Fehler" 1 "Fehler" ;
VAL_ 379 FCU_Fehler_Entladung_defekt 0 "nicht_aktiv" 1 "Fehler" 2 "Reserve" 3 "Init" ;
VAL_ 379 FCU_Fehler_Isofehler_I 0 "nicht_aktiv" 1 "aktiv" 2 "Reserve" 3 "Init" ;
VAL_ 379 FCU_Fehler_Isofehler_II 0 "nicht_aktiv" 1 "aktiv" 2 "Reserve" 3 "Init" ;
VAL_ 379 FCU_OBD_Lampe_Anf 0 "kein_MIL_Request" 1 "MIL_Request" ;
VAL_ 379 FCU_Absperrventil_schliessen 0 "nicht_verfuegbar" 1 "Ansteuerung_Ventil_zulaessig" 2 "Ventil_oeffnen_oder_geoeffnet" 3 "Ventil_schliessen_o_geschlossen" ;
VAL_ 379 FCU_TK_Betankung_Anforderung 0 "inaktiv" 1 "aktiv" ;
VAL_ 379 FCU_MinAbs_Leistung 1023 "Init" ;
VAL_ 379 FCU_Ionenspuelung_aktiv 0 "keine_Spuelung" 1 "Spuelung_zwingend_notwendig" 2 "Spuelung_Anforderung" ;
VAL_ 379 FCU_TK_Freigabe_Tankklappe 0 "keineFreigabe" 1 "Freigabe" 2 "TankvorgangAktiv" 3 "TimerOeffnenAbgelaufen" 4 "TimerSchliessenAbgelaufen" 5 "TimerBedingungenAbgelaufen" 6 "DruckTemperaturAenderung" 15 "Fehler" ;
VAL_ 2463978770 FCU_TK_H2_Fuellstand 510 "Init" 511 "Fehler" ;
VAL_ 2463978770 FCU_TK_H2_Nachtanken_aktiv 0 "Init" 1 "inaktiv" 2 "aktiv" 3 "Fehler" ;
VAL_ 2463978770 FCU_TK_Meldungen 0 "Init" 1 "Leckage1_Fahrzeug_Halt" 2 "Leckage2_Fahrzeug_NOT" 3 "Tankbereitschaft_herstellen" 4 "Tankbereitschaft_hergestellt" 5 "Fehler_Tanksystem" 7 "Fehler" ;
VAL_ 2463978770 FCU_TK_Tankwarnungen 0 "Init" 1 "Stufe1" 2 "Stufe2" 3 "Stufe3" 7 "Fehler" ;
VAL_ 606 FCU_Energieaequivalent 4095 "Init" ;
VAL_ 606 FCU_Verbrauch_FC_Nebag_Ueberlauf 0 "kein_Ueberlauf" 1 "Ueberlauf_Verbrauchssignal" ;
VAL_ 606 FCU_Verbrauch_H2_Ueberlauf 0 "kein_Ueberlauf" 1 "Ueberlauf_Verbrauchssignal" ;
VAL_ 606 FCU_Verbrauch_FC_Ueberlauf 0 "kein_Ueberlauf" 1 "Ueberlauf_Verbrauchssignal" ;
VAL_ 607 FCU_TK_Fuellstand 510 "Init" 511 "Fehler" ;
VAL_ 607 FCU_TK_Wasserstoffmasse_Tank 1022 "Init" 1023 "Fehler" ;
VAL_ 607 FCU_Verb_FC_Nebag_Masaequi_Ueb 0 "kein_Ueberlauf" 1 "Ueberlauf_Verbrauchssignal" ;
VAL_ 707 EFP_MomRad_Begr 4094 "Init" 4095 "Fehler" ;
VAL_ 707 FA_Warnung_Transportniveau 0 "keine_Anzeige" 1 "Warnung" ;
VAL_ 707 eAWS_Warnmeldung_Prio3 0 "keine_Anzeige" 1 "Hinweismeldung" ;
VAL_ 707 EFP_Anf_Kuehlklappenwarnung 0 "kein_Warnhinweis" 1 "Warnhinweis" ;
VAL_ 707 FDR_M_HL_02 252 "Darstellung_passiv" 253 "nicht_verbaut" 254 "Init" 255 "Fehler" ;
VAL_ 707 FDR_M_HR_02 252 "Darstellung_passiv" 253 "nicht_verbaut" 254 "Init" 255 "Fehler" ;
VAL_ 707 FDR_M_VL_02 252 "Darstellung_passiv" 253 "nicht_verbaut" 254 "Init" 255 "Fehler" ;
VAL_ 707 FDR_M_VR_02 252 "Darstellung_passiv" 253 "nicht_verbaut" 254 "Init" 255 "Fehler" ;
VAL_ 2589283684 FoD_Transmission_Info 0 "Initwert" 1 "start_transmission" 2 "finish_transmission" ;
VAL_ 2589283684 FoD_Anz_Funktionsabschaltung 0 "Init" 1 "Popup_aufschalten" ;
VAL_ 2549875476 FoD_Kombi_Req_Data 0 "Init" ;
VAL_ 2550006548 FoD_Kombi_Resp_Data 0 "Init" ;
VAL_ 2463978599 MKE_Anpassung_FZ 65535 "Fehler" ;
VAL_ 2463978599 MKE_Fahrzeit 0 "Init_keine_Anzeige" ;
VAL_ 968 GE_OBD_AbsperrVent 0 "kein Fehler / Init / nicht verbaut" 1 "KS- (Kurzschluss nach minus)" 2 "KS+ (Kurzschluss nach plus)" 3 "OC (Leitungsunterbrechung)" 4 "OOR+ (Signal zu gross)" 5 "OOR- (Signal zu klein)" 6 "RC+ (Signal unplausibel zu gross)" 7 "RC- (Signal unplausibel zu klein)" 8 "KS+/OC (Kurzschluss nach plus/Unterbrechung)" 9 "KS-/OC  (Kurzschluss nach minus/Unterbrechung)" 10 "KS-/KS+  (Kurzschluss nach minus/plus)" 11 "KS-/KS+/OC (Kurzschluss nach minus/plus/Unterbrechung)" 12 "Position_unbekannt" 13 "Failsafe_Position" 14 "Referenzfahrt_aktiv" 15 "frei" ;
VAL_ 968 GE_amax_moeglich 511 "nicht_definiert" ;
VAL_ 968 GE_Charisma_FahrPr 0 "keine_Funktion" 1 "Programm_1" 2 "Programm_2" 3 "Programm_3" 4 "Programm_4" 5 "Programm_5" 6 "Programm_6" 7 "Programm_7" 8 "Programm_8" 9 "Programm_9" 10 "Programm_10" 11 "Programm_11" 12 "Programm_12" 13 "Programm_13" 14 "Programm_14" 15 "Programm_15" ;
VAL_ 968 GE_Charisma_Status 0 "Init" 1 "verfuegbar" 2 "nicht_verfuegbar" 3 "asynchron_durch_Fahrerwunsch" ;
VAL_ 968 GE_Freigabe_Verfallsinfo_WFS 0 "Aus" 1 "Ein" ;
VAL_ 968 GE_LaunchControl_LB 0 "init" 1 "LC_not_available" 2 "LCperformance_not_possible" 3 "LCperformance_possible" 4 "LCperformance_armed" 5 "LCperformance_preparation" 6 "LCperformance_launch" 7 "LCperformance_aborted" 8 "LCsmoke_not_possible" 9 "LCsmoke_possible" 10 "LCsmoke_armed" 11 "LCsmoke_launch" 12 "LCsmoke_aborted" 13 "reserved" 14 "reserved" ;
VAL_ 968 GE_Status_PaddleNeutral 0 "Paddle_Neutral_inaktiv" 1 "Paddle_Neutral_aktiv" 2 "Paddle_Neutral_Ende_Timer_aktiv" 3 "Paddle_Neutral_Zwangsausstieg" ;
VAL_ 968 GE_Remotestart_Betrieb 0 "GSG_nicht_bereit_fuer_RS" 1 "GSG_bereit_fuer_oder_im_RS" ;
VAL_ 968 Freilauf_Charisma_FahrPr 0 "keine_Funktion" 1 "Programm_1" 2 "Programm_2" 3 "Programm_3" 4 "Programm_4" 5 "Programm_5" 6 "Programm_6" 7 "Programm_7" 8 "Programm_8" 9 "Programm_9" 10 "Programm_10" 11 "Programm_11" 12 "Programm_12" 13 "Programm_13" 14 "Programm_14" 15 "Programm_15" ;
VAL_ 968 Freilauf_Charisma_Status 0 "Init" 1 "verfuegbar" 2 "nicht_verfuegbar" 3 "asynchron_durch_Fahrerwunsch" ;
VAL_ 968 GE_Freigabe_Info_WFS 0 "ungueltig" 1 "gueltig" ;
VAL_ 968 GE_Sperr_Info_WFS 0 "nicht_gesperrt" 1 "gesperrt" ;
VAL_ 968 GE_Zustand_Kuppltemp 0 "Init" 1 "Kupplungstemp_normal" 2 "Kupplungstemp_hoch" 3 "Kupplungsschutz_aktivieren" ;
VAL_ 968 GE_Codierung_MSG 0 "Codierung iO / Init" 1 "Codierung niO" ;
VAL_ 968 GE_LaunchControl 0 "inaktiv" 1 "aktiv" ;
VAL_ 968 GE_Heizwunsch 0 "maximaler_Waermebedarf" 1 "kein_Waermebedarf" 2 "Kuehlbedarf" 3 "Notfall_(maximaler_Kuehlbedarf)" ;
VAL_ 968 GE_OBD_Status 0 "MIL aus" 1 "MIL ein" ;
VAL_ 968 GE_LFR_Adaption 0 "fuer_Adaption_geeignet" 1 "fuer_Adaption_nicht_geeignet" ;
VAL_ 968 GE_Sumpftemperatur 255 "Fehler" ;
VAL_ 324 GE_Ist_Fahrstufe 0 "Init" 1 "Position_1" 2 "Position_2" 3 "Position_3" 4 "Position_4" 5 "D" 6 "N" 7 "R" 8 "P" 10 "Position_Tipp_plus" 11 "Position_Tipp_minus" 12 "S" 13 "Kurz Manuell Prog." 14 "Tipp-Gasse" 15 "Fehler" ;
VAL_ 324 GE_Test_Freigabe 0 "kein Test" 1 "gültige Testparameter" ;
VAL_ 324 GE_N_Haltephase 0 "nicht_aktiv" 1 "aktiv" ;
VAL_ 324 GE_WH_Abschalten 0 "Wählhebel-SG ein" 1 "Wählhebel-SH aus" ;
VAL_ 324 GE_Soll_Haltemagnet 0 "Init_nicht_verwendet" 1 "nicht_halten" 2 "halten" 3 "keine_Vorgabe" ;
VAL_ 324 GE_WH_Sperre 0 "Wählhebel sperren" 1 "Wählhebel freigeben" ;
VAL_ 324 WH_gespeicherte_Fahrstufe 0 "keine_Speicherung" 1 "P" 2 "R" 3 "N" 4 "D" 5 "S" 6 "Tipp_Gasse" ;
VAL_ 324 WH_SensorPos_roh 0 "Init" 1 "Pos_1" 2 "Pos_2" 3 "Pos_3" 4 "Pos_4" 5 "Pos_5" 6 "Pos_6" 7 "Pos_7" 8 "Pos_8" 9 "Pos_9" 10 "Pos_10" 11 "Pos_11" 12 "Pos_12" 13 "Pos_13" 14 "Pos_14" 15 "Fehler" ;
VAL_ 324 WH_P_Taste 0 "Init" 1 "nicht_betaetigt" 2 "betaetigt" 3 "Fehler" ;
VAL_ 324 WH_Warnung_02 0 "Keine_Anzeige" 1 "Waehlhebel_defekt_Weiterfahrt_moeglich" 2 "Waehlhebel_in_Automatgasse_zurueckstellen" 3 "P_Taste_defekt" 4 "Zeitueberschr_P_wird_eingelegt" 5 "Wegrollgefahr__P_nicht_moeglich" ;
VAL_ 324 WH_Warnung_03 0 "keine_Anzeige" 1 "Fahrstufe_D_mit_rechtem_Paddle" 2 "Fahrstufe_D_ueber_MD_Button" ;
VAL_ 299 GRA_Hauptschalter 0 "Aus_Taster_nicht_betaetigt" 1 "Ein_Taster_betaetigt" ;
VAL_ 299 GRA_Abbrechen 0 "nicht_betaetigt" 1 "betaetigt" ;
VAL_ 299 GRA_Typ_Hauptschalter 0 "gerasteter_Lenkstockschalter" 1 "getasteter_Lenkstockschalter" ;
VAL_ 299 GRA_Limiter 0 "nicht_betaetigt" 1 "betaetigt" ;
VAL_ 299 GRA_Tip_Setzen 0 "nicht_betaetigt" 1 "betaetigt" ;
VAL_ 299 GRA_Tip_Hoch 0 "nicht_betaetigt" 1 "betaetigt" ;
VAL_ 299 GRA_Tip_Runter 0 "nicht_betaetigt" 1 "betaetigt" ;
VAL_ 299 GRA_Tip_Wiederaufnahme 0 "nicht_betaetigt" 1 "betaetigt" ;
VAL_ 299 GRA_Verstellung_Zeitluecke 0 "Taste_nicht_betaetigt" 1 "Dist_minus_1" 2 "Dist_plus_1" 3 "Dist_Toggle" ;
VAL_ 299 GRA_Codierung 0 "kein_Hebel" 1 "GRA_Hebel" 2 "ACC_Hebel" 3 "Limiter_Only" ;
VAL_ 299 GRA_Fehler 0 "kein_Fehler" 1 "Fehler" ;
VAL_ 299 GRA_LIM_Taste_verfuegbar 0 "Limiter_Taste_nicht_vorhanden" 1 "Limiter_Taste_vorhanden" ;
VAL_ 299 GRA_Tip_Stufe_2 0 "Tip_Stufe_1_keine_Betaetigung" 1 "Tip_Stufe_2" ;
VAL_ 299 GRA_Typ_Bedienteil 0 "Init" 1 "4_Positions_Bedienteil" 2 "6_Positions_Bedienteil" 3 "8_Positions_Bedienteil" 4 "PAG_5_Positions_Bedienteil" 5 "VW_MFL_Gen2" 6 "VW_MFL_Gen3" 7 "PAG_DX1_Bedienteil" ;
VAL_ 299 GRA_TravelAssist 0 "nicht_betaetigt" 1 "betaetigt" ;
VAL_ 310 HAL_Status 0 "Normalbetrieb" 1 "Lenkungsausfall" 2 "Derating_aktiv" 3 "Lenkung_manuell_deaktiviert" ;
VAL_ 310 HAL_VZ_Radwinkel 0 "positiv_Lenkeinschlag_links" 1 "negativ_Lenkeinschlag_rechts" ;
VAL_ 310 HAL_QBit_Radwinkel 0 "gueltiger_Wert" 1 "Ersatz_Init_oder_Fehlerwert" ;
VAL_ 310 HAL_Radwinkel 1020 "Unterspannung" 1021 "nicht_kalibriert" 1022 "Init" 1023 "Fehler" ;
VAL_ 310 HAL_Warnungen 0 "keine_Warnung" 1 "Ausfall_rote_Warnung" 2 "Systemstoerung_gelbe_Warnung" 3 "HAL_deaktiviert" ;
VAL_ 310 HAL_Winkelbegrenzung 0 "nicht_aktiv" 1 "Lenkwinkelbegrenzung_aktiv" ;
VAL_ 310 HAL_VZ_Fahrerwunschwinkel_Soll 0 "positiv" 1 "negativ" ;
VAL_ 310 HAL_Fahrerwunschwinkel_Soll 1022 "Init" 1023 "Fehler" ;
VAL_ 310 HAL_max_Gradient 126 "Init" 127 "Fehler" ;
VAL_ 310 HAL_EFP_FahrPr 0 "keine_Funktion" 1 "Programm_1" 2 "Programm_2" 3 "Programm_3" 4 "Programm_4" 5 "Programm_5" 6 "Programm_6" 7 "Programm_7" 8 "Programm_8" 9 "Programm_9" 10 "Programm_10" 11 "Programm_11" 12 "Programm_12" 13 "Programm_13" 14 "Programm_14" 15 "Programm_15" ;
VAL_ 310 HAL_Status_2 0 "Init" 1 "Fahrbereit" 2 "Symmetriefahrt" 3 "Gelbe_Warnung" 4 "Rote_Warnung" 5 "Hinterachlenkung_deaktiviert" ;
VAL_ 310 HAL_Charisma_Status 0 "Init" 1 "verfuegbar" 2 "nicht_verfuegbar" 3 "asynchron_durch_Fahrerwunsch" ;
VAL_ 310 HAL_Charisma_FahrPr 0 "keine_Funktion" 1 "Programm_1" 2 "Programm_2" 3 "Programm_3" 4 "Programm_4" 5 "Programm_5" 6 "Programm_6" 7 "Programm_7" 8 "Programm_8" 9 "Programm_9" 10 "Programm_10" 11 "Programm_11" 12 "Programm_12" 13 "Programm_13" 14 "Programm_14" 15 "Programm_15" ;
VAL_ 1412 HSP_Taster 0 "nicht_betaetigt" 1 "betaetigt" ;
VAL_ 1412 HSP_Status_LED 0 "LED_nicht_angesteuert" 1 "LED_angesteuert" ;
VAL_ 1412 HSP_Warnung_LED 0 "Aus" 1 "Ein" ;
VAL_ 1412 HSP_Warnung_Ton 0 "Aus" 1 "Ein" ;
VAL_ 1412 HSP_Warnung_Text 0 "Aus" 1 "Ein" ;
VAL_ 1412 HSP_Endlage_eingefahren 0 "Endlage nicht erreicht" 1 "Endlage erreicht" ;
VAL_ 1412 HSP_Endlage_ausgefahren 0 "Endlage nicht erreicht" 1 "Endlage erreicht" ;
VAL_ 1412 HSP_Unterspannung 0 "normal" 1 "Fehler" ;
VAL_ 1412 HSP_Ueberspannung 0 "normal" 1 "Fehler" ;
VAL_ 1412 HSP_Lokalaktiv 0 "war_nicht_lokal_aktiv" 1 "war_lokal_aktiv" ;
VAL_ 1412 HSP_ResponseError 0 "normal" 1 "Fehler" ;
VAL_ 1412 HSP_ErrorGueltigkeit_1 0 "Fehler_passiv__Fehlerpfad_nicht_durchlaufen" 1 "Fehler_gueltig__Fehlerpfad_durchlaufen" ;
VAL_ 1412 HSP_ErrorGueltigkeit_2 0 "Fehler_passiv__Fehlerpfad_nicht_durchlaufen" 1 "Fehler_gueltig__Fehlerpfad_durchlaufen" ;
VAL_ 1412 HSP_def 0 "normal" 1 "Fehler" ;
VAL_ 1412 HSP_Motor_def 0 "normal" 1 "Fehler" ;
VAL_ 1412 HSP_Spoiler_Error 0 "iO" 1 "Fehler__Endlage_nicht_erreicht" ;
VAL_ 1412 HSP_Taster_Error 0 "Taster_iO" 1 "Fehler__haengender_Taster" ;
VAL_ 1412 HSP_LED_Error 0 "normal" 1 "Fehler" ;
VAL_ 1412 HSP_Spielschutz 0 "inaktiv" 1 "aktiv" ;
VAL_ 1412 HSP_Motor_Temp_Text 0 "Aus" 1 "Ein" ;
VAL_ 1412 HSP_Charisma_FahrPr 0 "keine_Funktion" 1 "Programm_1" 2 "Programm_2" 3 "Programm_3" 4 "Programm_4" 5 "Programm_5" 6 "Programm_6" 7 "Programm_7" 8 "Programm_8" 9 "Programm_9" 10 "Programm_10" 11 "Programm_11" 12 "Programm_12" 13 "Programm_13" 14 "Programm_14" 15 "Programm_15" ;
VAL_ 1412 HSP_Charisma_Status 0 "Init" 1 "verfuegbar" 2 "nicht_verfuegbar" 3 "asynchron_durch_Fahrerwunsch" ;
VAL_ 1412 HSP_man_Betaet_nicht_zulaessig 0 "inaktiv" 1 "aktiv" ;
VAL_ 1412 HSP_Komponentensteuerung 0 "Aus" 1 "Ein" ;
VAL_ 1412 HSP_BAP_Messages 0 "No_message" 1 "Spoiler_extending" 2 "Spoiler_extending_hold_button" 3 "Spoiler_retracting" 4 "Spoiler_retracting_hold_button" 5 "Spoiler_extended" 6 "Spoiler_retracted" 7 "Extending_spoiler_not_possible" 8 "Retracting_spoiler_not_possible" 9 "Spoiler_not_available" 10 "Thermal_protection" 11 "Protection_against_misuse" 12 "Spoiler_intermediate_position" ;
VAL_ 1609 HUD_Aktiv 0 "HUD_aus_Init" 1 "HUD_aktiv" ;
VAL_ 1609 HUD_Anzeigefehler_NV 0 "kein_Fehler" 1 "Anzeigefehler" ;
VAL_ 1609 HUD_NV_in_Anzeige 0 "NV_nicht_in_Anzeige" 1 "NV_in_Anzeige" ;
VAL_ 1609 HUD_Anforderung_Fokus 0 "Kein_Fokus_angefordert" 1 "Fokus_angefordert" ;
VAL_ 1609 HUD_VZE_in_Anzeige 0 "VZE_nicht_in_Anzeige" 1 "VZE_in_Anzeige" ;
VAL_ 1609 HUD_FAS_Anzeige_Kombi 0 "Init" 1 "FAS_im_Kombi_Anzeigen" 2 "FAS_im_Kombi_Ausblenden" ;
VAL_ 1609 HUD_KDK_Anzeige_Kombi 0 "Init" 1 "KDK_im_Kombi_Anzeigen" 2 "KDK_im_Kombi_Ausblenden" ;
VAL_ 1609 HUD_PEA_Anzeige_Kombi 0 "Init" 1 "PEA_im_Kombi_Anzeigen" 2 "PEA_im_Kombi_Ausblenden" ;
VAL_ 1609 HUD_VZE_AIO_Anzeige_Kombi 0 "Init" 1 "VZE_AIO_im_Kombi_Anzeigen" 2 "VZE_AIO_im_Kombi_Ausblenden" ;
VAL_ 1283 HVK_Istmodus_Anf 0 "nicht_angefordert" 1 "angefordert" ;
VAL_ 1283 HVK_TN1_Sollmodus 0 "HV_Off" 1 "HV_On" 2 "reserviert" 3 "Initialisierung" ;
VAL_ 1283 HVK_MO_EmSollzustand 0 "HvOff" 1 "HvStbyReq" 2 "HvStbyWait" 3 "HvBattOnReq" 4 "HvBattOnWait" 10 "HvOnIdle" 18 "HvOnDrvReq" 19 "HvOnDrvWait" 20 "HvOnDrvRdy" 28 "HvStepUpReq" 29 "HvStepUpWait" 30 "HvStepUp" 38 "HvStepDownReq" 39 "HvStepDownWait" 40 "HvStepDown" 46 "HvAcChPreReq" 47 "HvAcChPreWait" 48 "HvAcChReq" 49 "HvAcChWait" 50 "HvAcCh" 56 "HvDcChPreReq" 57 "HvDcChPreWait" 58 "HvDcChReq" 59 "HvDcChWait" 60 "HvDcCh" 67 "HvChOffReq" 68 "HvChOffWait" 69 "HvOnIdleReq" 70 "HvOnIdleWait" 96 "HvCpntOffReq" 97 "HvCpntOffWait" 98 "HvBattOffReq" 99 "HvBattOffWait" 109 "HvDcDcFailOffReq" 110 "HvDcDcFail" 119 "HvElmOffReq" 120 "HvElmOff" 126 "HvFailCpntOffReq" 127 "HvFailCpntOffWait" 128 "HvFailBattOffReq" 129 "HvFailBattOffWait" 130 "HvFailBattOff" 138 "HvFailUCtlReq" 139 "HvFailUCtlWait" 140 "HvFailUCtl" 150 "HvEmgcyOff" 255 "Init" ;
VAL_ 1283 HVK_BMS_Sollmodus 0 "HV_Off" 1 "HV_On" 3 "AC_Laden_erw" 4 "AC_Laden" 6 "DC_Laden" 7 "Init" ;
VAL_ 1283 HVK_DCDC_Sollmodus 0 "Standby" 1 "HV_On_Vorladen" 2 "Tiefsetzen" 3 "Hochsetzen" 4 "Pruefpuls_12V" 6 "Pruefpuls_DC_Laden" 7 "Initialisierung" ;
VAL_ 1283 HVK_EKK_Sollmodus 0 "Keine_Freigabe" 1 "Freigabe" 2 "Freigabe_ausgesetzt" 7 "Init" ;
VAL_ 1283 HVK_HVPTC_Sollmodus 0 "Keine_Freigabe" 1 "Freigabe" 2 "Freigabe_ausgesetzt" 7 "Init" ;
VAL_ 1283 HVK_HVLM_Sollmodus 0 "keine_Freigabe" 1 "Freigabe_Lademanager" 2 "Vorladung_AC_Pfad" 7 "Init" ;
VAL_ 1283 HVK_HV_Netz_Warnungen 0 "Keine_Warnung" 1 "Warntext_HV_Netz_Anf" 2 "Fehlertext_HV_Netz_Anf" 3 "Warnung_Kein_Wiederstart_moeglich" ;
VAL_ 1283 HV_Bordnetz_aktiv 0 "inaktiv" 1 "aktiv" ;
VAL_ 1283 HV_Bordnetz_Fehler 0 "kein_Fehler" 1 "Fehler" ;
VAL_ 1283 HVK_Gesamtst_Spgfreiheit 0 "Funktion_Init__ohne_Funktion" 1 "HV_System_spannungsfrei" 2 "HV_System_nicht_spannungsfrei" 3 "Fehler" ;
VAL_ 1283 HVK_AktiveEntladung_Anf 0 "nicht_angefordert" 1 "angefordert" ;
VAL_ 1283 HVK_Iso_Fehlerstatus 0 "kein_Fehler" 1 "Fehler" ;
VAL_ 1283 HVK_Iso_Messung_Start 0 "keine_Messung" 1 "Messung_HV_Netz_1" 2 "Messung_HV_Netz_2" 4 "deaktiviert" ;
VAL_ 1283 HVK_AIAD_Sollmodus_2 0 "keine_Freigabe" 1 "Freigabe" ;
VAL_ 1283 HVK_DCDC_EKK_Sollmodus 0 "aus" 1 "ein" 2 "reserviert" 3 "Init" ;
VAL_ 1381 HVLM_HV_Abstellzeit 254 "Init" 255 "Fehler" ;
VAL_ 1381 HVLM_Ladesystemhinweise 0 "kein_Hinweis" 1 "Ladesystem_defekt" 2 "Ladesaeule_inkompatibel" 3 "DC_Laden_nicht_moeglich" ;
VAL_ 1381 HVLM_Schluessel_Anfrage 0 "Keine_Anfrage_Init" 1 "Suchanfrage_LKL_1_aktiv" 2 "Suchanfrage_LKL_2_aktiv" 3 "Reserve" ;
VAL_ 1381 HVLM_Zustand_LED 0 "Farbe_1__aus" 1 "Farbe_2__weiss" 2 "Farbe_3__gelb" 3 "Farbe_4__gruen" 4 "Farbe_5__rot" 5 "Farbe_3_pulsierend" 6 "Farbe_4_pulsierend" 7 "Farbe_5_pulsierend" 8 "Farbe_4_5_pulsierend" 9 "Farbe_4__gruen_blinkend" 14 "Init" 15 "Fehler" ;
VAL_ 1381 HVLM_MaxStrom_Netz 126 "Init" 127 "Fehler" ;
VAL_ 1381 HVLM_LG_Sollmodus 0 "Standby" 1 "Netzladung" ;
VAL_ 1381 HVLM_FreigabeTankdeckel 0 "keine_Freigabe" 1 "Freigabe" 2 "Init" 3 "Fehler" ;
VAL_ 1381 HVLM_Stecker_Verriegeln 0 "Stecker_entriegeln" 1 "Stecker_verriegeln" 2 "Init" 3 "keine_Anforderung" ;
VAL_ 1381 HVLM_Start_Spannungsmessung_DCLS 0 "inaktiv" 1 "DCLS_mit_Diode_Start_Messung" 2 "DCLS_ohne_Diode_Start_Messung" 3 "reserve" ;
VAL_ 1381 PnC_Trigger_OBC_cGW 0 "PnC_Init" 1 "PnC_NoNeeds" 2 "PnC_ReportUnknownRootCert" 3 "PnC_CreateVehicleCert" 4 "PnC_DP_RootCertContainer" 5 "PnC_DP_CapabilityIsoTpInfo" 6 "PnC_DP_Contract" 7 "PnC_DP_VehicleCert" 15 "PnC_Error" ;
VAL_ 1381 HVLM_FreigabeKlimatisierung 0 "keine_Freigabe" 1 "Freigabe" 2 "Init" 3 "Fehler" ;
VAL_ 1381 HVLM_Freigabe_Lastabwurf 0 "keine_Freigabe_Lastabwurf" 1 "Freigabe_Lastabwurf" ;
VAL_ 1381 HVLM_Ladetexte 0 "Keine_Anzeige" 1 "AC_Laden_nicht_moeglich" 2 "DC_Laden_nicht_moeglich" 3 "AC_und_DC_Laden_nicht_moeglich" ;
VAL_ 1381 HVLM_IsoMessung_Anf 0 "Laden_mit_Isomessung" 1 "Laden_ohne_Isomessung" ;
VAL_ 1381 HVLM_IstSpannung_HV 1022 "Init" 1023 "Fehler" ;
VAL_ 312 IPA_Anforderung_HMS 0 "keine_Anforderung" 1 "halten" 2 "parken" 3 "halten_Standby" 4 "anfahren" 5 "Loesen_ueber_Rampe" 6 "Parken_mit_P" ;
VAL_ 312 Parken_aktives_System 0 "kein_aktives_System" 1 "Manoevrierassistent_Ueberwachung" 2 "IPA" 3 "fernbedientes_Parken" 4 "Manoevrierassistent" 5 "Manoevrierassistent_quer" 6 "Anhaengerrangierassistent" 7 "fernbedienter_Anhaengerrangierassistent" ;
VAL_ 312 Parken_erhoehtes_Moment 0 "keine_Anforderung" 1 "Anforderung_Rampe1" 2 "Anforderung_Rampe2" 3 "Anforderung_Rampe3" 4 "Anforderung_Rampe4" 5 "Anforderung_Rampe5" 6 "Anforderung_Rampe6" 7 "Anforderung_Rampe7" 8 "Anforderung_Rampe8" 9 "Anforderung_Rampe9" 10 "Anforderung_Rampe10" 11 "Anforderung_Rampe11" 12 "Anforderung_Rampe12" 13 "Anforderung_Rampe13" 14 "Anforderung_Rampe14" 15 "Anforderung_Rampe15" ;
VAL_ 312 Parken_Motorlauf_Anf 0 "Keine_Anforderung" 1 "Motor_aus" 2 "Motor_an" 3 "Weiterlauf_Fahreruebernahme" ;
VAL_ 312 IPA_Fahrstufenwunsch 0 "Init" 1 "Fahrstufe_beibehalten" 2 "Position_R" 3 "Position_D" 4 "Position_N" ;
VAL_ 312 IPA_Status 0 "Init" 4 "IPA_Anzeige_Aktiv" 5 "IPA_Fahreruebernahme" 6 "IPA_Aktiv" 7 "IPA_Standby" 8 "IPA_Funktionsbereit" 9 "IPA_PP_Aktivierung" 10 "IPA_Abbruch" 11 "IPA_Aktivierend" 15 "IPA_PP_Start" ;
VAL_ 312 IPA_Status_IPA_GE 0 "Init" 1 "Neustart" 2 "Funktionsbereit" 3 "Aktiv" 7 "Fehler" ;
VAL_ 312 IPA_Status_IPA_TSK 1 "IPA_TSK_Init" 2 "IPA_TSK_Fehler" 4 "IPA_TSK_aktivierbar" 5 "IPA_TSK_pausiert" 6 "IPA_TSK_aktiv" 8 "IPA_TSK_funktionsbereit" ;
VAL_ 312 IPA_Sollbeschleunigung 0 "Neutralwert" ;
VAL_ 312 Parken_Fahrbereitschaft_Anf 0 "keine_Anforderung" 1 "Anforderung_Fahrbereitschaft" ;
VAL_ 312 IPA_Parken_beibehalten_HMS 0 "Parken_nicht_beibehalten" 1 "Parken_beibehalten" 2 "Init" 3 "Fehler" ;
VAL_ 312 IPA_Status_EDR 0 "Faulted" 1 "Off" 2 "On_but_not_controlling" 3 "On_actively_controlling" ;
VAL_ 312 IPA_PLA_LED 0 "LED_aus" 1 "LED_ein" 2 "LED_blinken" 3 "Funktion_gesperrt__LED_aus" 6 "Init" ;
VAL_ 312 IPA_APS_LED 0 "LED_aus" 1 "LED_ein" 2 "LED_blinken" 3 "Funktion_gesperrt__LED_aus" 6 "Init" ;
VAL_ 2463978614 KAS_Verfuegbarkeit 0 "Init" 1 "verfuegbar" 2 "nicht_verfuegbar" ;
VAL_ 2463978614 KAS_Kritikalitaetslevel 0 "unkritisch" 1 "Kritikalitaetslevel_1" 2 "Kritikalitaetslevel_2" 3 "Kritikalitaetslevel_3" 4 "Kritikalitaetslevel_4" 5 "Kritikalitaetslevel_5" 6 "reserviert" 7 "nicht_bewertbar" ;
VAL_ 2463978614 KAS_Anf_OPS 0 "Aus" 1 "An" ;
VAL_ 2463978614 KAS_PreSense_Modus_System 0 "deaktiviert" 1 "aktiviert" ;
VAL_ 2463978614 KAS_Status 0 "Init" 1 "Nicht_verfuegbar" 2 "Deaktiviert" 3 "Aktiv" 4 "Passiv" 5 "Blindheit" 6 "Fehler" 7 "reserviert" ;
VAL_ 2463978614 KAS_Anzeige_Info_links 0 "Keine_Anzeige" 1 "Info" 2 "Info_kritisch" ;
VAL_ 2463978614 KAS_Anzeige_Info_rechts 0 "Keine_Anzeige" 1 "Info" 2 "Info_kritisch" ;
VAL_ 2463978614 KAS_Anzeige_Warnung 0 "keine_Anzeige" 1 "Warnung_links" 2 "Warnung_rechts" 3 "Warnung_beidseitig" 4 "Bremsung" ;
VAL_ 2463978614 KAS_Texte 0 "keine_Anzeige" 1 "Stoerung_Bitte_Service_aufsuchen" 2 "Zurzeit_nicht_verfuegbar" 3 "Sensorsicht_umgebungsbedingt_eingeschraenkt" 4 "Eingeschraenkt_Stabilisierungskontrolle_ESC_ausgeschaltet" 5 "In_aktuellem_Audi_drive_select_modus_eingeschraenkt" 6 "Bremsung_erfolgt_Hindernis_erkannt_Bitte_uebernehmen" 7 "Bitte_uebernehmen" ;
VAL_ 2463978614 KAS_Anf_Prefill 0 "Prefill_nicht_angefordert" 1 "Prefill_angefordert" ;
VAL_ 2463978614 KAS_Anf_Bremsruck 0 "keine_Ruckanforderung" 1 "Bremsruck_Profil_01_angefordert" 2 "Bremsruck_Profil_02_angefordert" 3 "Bremsruck_Profil_03_angefordert" 4 "Bremsruck_Profil_04_angefordert" 5 "Bremsruck_Profil_05_angefordert" 6 "Bremsruck_Profil_06_angefordert" 7 "Bremsruck_Profil_07_angefordert" ;
VAL_ 2463978614 KAS_Verz_Anf 254 "Init" 255 "Fehler" ;
VAL_ 497 KY_IDG_in_Reichweite 0 "ausser_Reichweite_bzw_nicht_ermittelbar" 1 "innerhalb_Reichweite" ;
VAL_ 497 KY_Auf_Taste 0 "Taste_nicht_betaetigt" 1 "Oeffnentaste_betaetigt" ;
VAL_ 497 KY_HDF_Taste 0 "Taste_nicht_betaetigt" 1 "HDF_Taste_am_Funkschluessel_betaetigt" ;
VAL_ 497 KY_Panik_Taste 0 "Taste_nicht_betaetigt" 1 "Panik_Taste_am_Funkschluessel_betaetigt" ;
VAL_ 497 KY_Zu_Taste 0 "Taste_nicht_betaetigt" 1 "Zu_Taste_am_Funkschluessel_betaetigt" ;
VAL_ 497 KY_FT_Entriegelung_Autorisiert 0 "kein_Keylessschluessel_erkannt" 1 "Keyless_Schluessel_erkannt_und_authorisiert" ;
VAL_ 497 KY_FT_Verriegelung_Autorisiert 0 "kein_Verriegelungssensor_erkannt" 1 "Verriegelungssensor_erkannt_und_authorisiert" ;
VAL_ 497 KY_BT_Entriegelung_Autorisiert 0 "kein_Keylessschluessel_erkannt" 1 "Keyless_Schluessel_erkannt_und_authorisiert" ;
VAL_ 497 KY_BT_Verriegelung_Autorisiert 0 "kein_Verriegelungssensor_erkannt" 1 "Verriegelungssensor_erkannt_und_authorisiert" ;
VAL_ 497 KY_HFS_Entriegelung_Autorisiert 0 "kein_Keylessschluessel_erkannt" 1 "Keyless_Schluessel_erkannt_und_authorisiert" ;
VAL_ 497 KY_HFS_Verriegelung_Autorisiert 0 "kein_Verriegelungssensor_erkannt" 1 "Verriegelungssensor_erkannt_und_authorisiert" ;
VAL_ 497 KY_HBFS_Entriegelung_Autorisiert 0 "kein_Keylessschluessel_erkannt" 1 "Keyless_Schluessel_erkannt_und_authorisiert" ;
VAL_ 497 KY_HBFS_Verriegelung_Autorisiert 0 "kein_Verriegelungssensor_erkannt" 1 "Verriegelungssensor_erkannt_und_authorisiert" ;
VAL_ 497 KY_Front_Entr_Autorisiert 0 "kein_Keylessschluessel_erkannt" 1 "Keyless_Schluessel_erkannt_und_authorisiert" ;
VAL_ 497 KY_Front_Verr_Autorisiert 0 "kein_Verriegelungssensor_erkannt" 1 "Verriegelungssensor_erkannt_und_authorisiert" ;
VAL_ 497 KY_HD_Entriegelung_Autorisiert 0 "kein_Keylessschluessel_erkannt" 1 "Keyless_Schluessel_erkannt_und_authorisiert" ;
VAL_ 497 KY_HD_Verriegelung_Autorisiert 0 "nicht_autorisiert" 1 "autorisiert" ;
VAL_ 497 KY_Bereich 0 "Bereich_0" 1 "Bereich_1" 2 "Bereich_2" 3 "Bereich_3" 4 "Bereich_4" 5 "Bereich_5" 6 "Kein_Schluessel_gefunden" 7 "Init" ;
VAL_ 497 KY_Position 0 "Position_0" 1 "Postition_1" 2 "Postition_2" 3 "Postition_3" 4 "Postition_4" 6 "Kein_Schluessel_gefunden" 7 "Init" ;
VAL_ 497 Schluesselnr_Personalisierung 1 "Schluesselnummer_eins_aktiv" 2 "Schluesselnummer_zwei_aktiv" 3 "Schluesselnummer_drei_aktiv" 4 "Schluesselnummer_vier_aktiv" 5 "Schluesselnummer_fuenf_aktiv" 6 "Schluesselnummer_sechs_aktiv" 7 "Schluesselnummer_sieben_aktiv" 8 "Schluesselnummer_acht_aktiv" 14 "Init" 15 "Fehler" ;
VAL_ 497 FFB_FDF_Taste 0 "Taste_nicht_betaetigt" 1 "FDF_Taste_am_Funkschluessel_betaetigt" ;
VAL_ 497 FFB_Joker_Taste 0 "Taste_nicht_betaetigt" 1 "Joker_Taste_an_FFFB_betaetigt" ;
VAL_ 497 FFB_Park_Taste 0 "Taste_nicht_betaetigt" 1 "Park_Taste_betaetigt" ;
VAL_ 497 FFB_Remotestart_Taste 0 "Taste_nicht_betaetigt" 1 "Remotestart_Taste_betaetigt" ;
VAL_ 497 FBS_Aktivierung_Pilot_Parken 0 "keine_Funktionsaktivierung" 1 "Aktivierung_FFB_erkannt" ;
VAL_ 497 KY_Schluessel_im_Fzg 0 "Schluessel_nicht_im_Fahrzeug" 1 "Schluessel_im_Fahrzeug" ;
VAL_ 497 KY_EasyClose_Abbruch 0 "EasyClose_kein_Abbruch" 1 "EasyClose_Abbruch" ;
VAL_ 497 KY_EasyClose_Status 0 "Lampe_AUS" 1 "Lampe_EIN" 2 "Lampe_NORMAL" 3 "Lampe_HEKTIK" 4 "Akustik_Verweigerung" ;
VAL_ 497 KY_HD_Auffahrt 0 "keine_Anforderung" 1 "HD_Auffahrt_angefordert" ;
VAL_ 497 KY_HD_Zufahrt 0 "keine_Anforderung" 1 "HD_Zufahrt_angefordert" ;
VAL_ 497 KY_LKL_1_Autorisierung 0 "Kein_Zugang_LKL_1_erkannt" 1 "Zugang_LKL_1_erkannt" ;
VAL_ 497 KY_LKL_2_Autorisierung 0 "Kein_Zugang_LKL_2_erkannt" 1 "Zugang_LKL_2_erkannt" ;
VAL_ 1424 FBS_Warn_Schluessel_Batt 0 "i.O." 1 "defekt" ;
VAL_ 1424 KY_FFB_Frequenz 0 "Init" 1 "433 MHz" 2 "315 MHz" 3 "868 MHz" ;
VAL_ 1424 KY_HF_Aktiv 0 "Funktempfang_nicht_aktiv" 1 "HF_Funkempfang_aktiv" ;
VAL_ 1424 KY_LF_Aktiv 0 "Funktempfang_nicht_aktiv" 1 "LF_Funkempfang_aktiv" ;
VAL_ 1424 KY_KYL_Fahrer_Hinweise 0 "keine_Anzeige" 1 "FZG_Zugang_Kein_Schluessel_erkannt" 2 "Schluessel_im_Innenraum_gefunden" 3 "Schluessel_im_Kofferraum_gefunden" 4 "FZG_Start_Kein_Schluessel_erkannt" 5 "FZG_Start_Kein_Schluessel_oder_NFC_erkannt" 6 "Warn_kein_NFC_erkannt" 7 "KL15_Keine_Autom_Aktivierung" ;
VAL_ 1424 KY_StartStopp_Info 0 "Motorlauf_nicht_notwendig_(Stoppfreigabe)" 1 "Motoranlauf_nicht_zwingend_notwendig_(Stoppverbot,keine_Startanforderung)" 2 "Motoranlauf_zwingend_notwendig_(Startanforderung)" 3 "Systemfehler" ;
VAL_ 1424 KY_Keyless_Verbau 0 "nicht_verbaut" 1 "verbaut" ;
VAL_ 1424 KY_Keyless_Go_Verbau 0 "nicht_verbaut" 1 "verbaut" ;
VAL_ 1424 KY_Transponder_aktiv 0 "nicht_aktiv" 1 "aktiv" ;
VAL_ 1424 KYL_Warn_kein_Schluessel 1 "kein Schluessel erkannt" ;
VAL_ 1424 KYL_Warn_Kessy_defekt 0 "Kessy_i.O." 1 "Kessy defekt" ;
VAL_ 1424 KYL_Warn_Notzuendschloss 0 "Aus" 1 "Ein" ;
VAL_ 1424 KY_Fzg_Verlassen_erkannt 0 "nicht_erkannt" 1 "erkannt" ;
VAL_ 1424 KY_Fzg_Zugang_erkannt 0 "nicht_erkannt" 1 "erkannt" ;
VAL_ 1424 KY_Indikator_Mehrere_Schluessel 0 "Init" 1 "Mehrere_Schluessel_im_Fahrzeug_gefunden" ;
VAL_ 1424 KY_NFC_Fahrer_Hinweise 0 "Init" 1 "Warn_kein_Keyless_gueltiges_NFC" 2 "Warn_gueltiges_Keyless_kein_NFC" ;
VAL_ 1424 KST_Wegstrecke_Challenge 0 "Init" ;
VAL_ 2463978671 KFS_Ausgefahren 0 "false" 1 "true" ;
VAL_ 2463978671 KFS_Eingefahren 0 "false" 1 "true" ;
VAL_ 2463978671 KFS_Fehler_Beleuchtung 0 "kein_Fehler_erkannt" 1 "Fehler_erkannt" ;
VAL_ 960 RSt_Fahrerhinweise 0 "Init" 1 "Fahreruebernahme_Hinweis_ZAT_Automat_ohne_Gong" 2 "Fahreruebernahme_Hinweis_ZAT_Automat_mit_Gong" 3 "Fahreruebernahme_Hinweis_ZAT_Handschalter_ohne_Gong" 4 "Fahreruebernahme_Hinweis_ZAT_Handschalter_mit_Gong" 5 "Fahreruebernahme_Hinweis_ZAS_Automat_ohne_Gong" 6 "Fahreruebernahme_Hinweis_ZAS_Automat_mit_Gong" 7 "Fahreruebernahme_Hinweis_ZAS_Handschalter_ohne_Gong" 8 "Fahreruebernahme_Hinweis_ZAS_Handschalter_mit_Gong" 9 "RemoteStart_aktiv_ohne_Gong" 10 "RemoteStart_aktiv_mit_Gong" 11 "void" 12 "void" 13 "void" 14 "void" 15 "void" ;
VAL_ 960 ZAS_Kl_S 0 "aus" 1 "S_Kontakt_ein" ;
VAL_ 960 ZAS_Kl_15 0 "aus" 1 "ein" ;
VAL_ 960 ZAS_Kl_X 0 "aus" 1 "ein" ;
VAL_ 960 ZAS_Kl_50_Startanforderung 0 "aus" 1 "KL50_ein_Startwunsch_Fahrer" ;
VAL_ 960 BCM_Remotestart_Betrieb 0 "kein_RS_Betrieb" 1 "RS_Betrieb" ;
VAL_ 960 ZAS_Kl_Infotainment 0 "inaktiv" 1 "aktiv" ;
VAL_ 960 BCM_Remotestart_KL15_Anf 0 "inaktiv" 1 "aktiv" ;
VAL_ 960 BCM_Remotestart_MO_Start 0 "nicht_angefordert" 1 "angefordert" ;
VAL_ 960 KST_Warn_P1_ZST_def 0 "nicht_defekt" 1 "defekt" ;
VAL_ 960 KST_Warn_P2_ZST_def 0 "nicht_defekt" 1 "defekt" ;
VAL_ 960 KST_Fahrerhinweis_1 0 "inaktiv" 1 "aktiv" ;
VAL_ 960 KST_Fahrerhinweis_2 0 "inaktiv" 1 "aktiv" ;
VAL_ 960 BCM_Ausparken_Betrieb 0 "kein_Betrieb" 1 "Ausparkvorgang_aktiv" ;
VAL_ 960 KST_Fahrerhinweis_4 0 "inaktiv" 1 "aktiv" ;
VAL_ 960 KST_Fahrerhinweis_5 0 "inaktiv" 1 "aktiv" ;
VAL_ 960 KST_Fahrerhinweis_6 0 "inaktiv" 1 "aktiv" ;
VAL_ 1420 KST_Txt_P_Gang 0 "Aus" 1 "Ein" ;
VAL_ 1420 KST_Txt_Panikabschaltung 0 "Aus" 1 "Ein" ;
VAL_ 1420 KST_Anf_Klemmenfreigabe_ELV 0 "nicht_angefordert" 1 "angefordert" ;
VAL_ 1420 KST_Txt_Komfortabschaltung 0 "inaktiv" 1 "aktiv" ;
VAL_ 1420 KST_ZAT_betaetigt 0 "Aus" 1 "Ein" ;
VAL_ 1420 KST_Unterdr_Zuendungsmeldung 0 "keine_Unterdr_der_Zuendungsmeldung" 1 "Unterdr_der_Zuendungsmeldung_aktiv" ;
VAL_ 1420 KST_aut_Abschaltung_Zuendung 0 "Zuendung_wird_bei_Verl_nicht_deaktiviert" 1 "Zuendung_wird_bei_Verl_deaktiviert" ;
VAL_ 1420 KST_Anf_ZV_Verriegelung 0 "inaktiv" 1 "aktiv" ;
VAL_ 1420 Relais_VoKo_angesteuert 0 "nicht_angesteuert" 1 "angesteuert" ;
VAL_ 1420 RSt_Anforderung_HMS 0 "keine_Anforderung" 1 "halten" 2 "parken" 3 "halten_Standby" 4 "anfahren" 5 "Loesen_ueber_Rampe" 6 "Parken_mit_P" ;
VAL_ 1646 KL_STL_aktiv 0 "Standlueftung_nicht_aktiv" 1 "Standlueftung_aktiv" ;
VAL_ 1646 KL_STH_aktiv 0 "Standheizung_nicht_aktiv" 1 "Standheizung_aktiv" ;
VAL_ 1646 KL_Solarluefter_aktiv 0 "Solarluefter_nicht_aktiv" 1 "Solarluefter_aktiv__auto" ;
VAL_ 1646 KL_Umluft_Taste 0 "Taste_nicht_gedrueckt" 1 "Taste_gedrueckt" ;
VAL_ 1646 KL_Geblaese_Fond_Status 0 "Geblaese_aus" 1 "Geblaesestufe_10" 2 "Geblaesestufe_20" 3 "Geblaesestufe_30" 4 "Geblaesestufe_40" 5 "Geblaesestufe_50" 6 "Geblaesestufe_60" 7 "Geblaesestufe_70" 8 "Geblaesestufe_80" 9 "Geblaesestufe_90" 10 "Geblaesestufe_100" 14 "Init" 15 "Fehler" ;
VAL_ 1646 KL_STH_Ansteuerung 0 "Aus" 1 "Ein" 2 "Ein_mit_Motorvorwaermung" 3 "Heizleistung_reduziert" ;
VAL_ 1646 KL_Magnetventil 0 "Aus" 1 "Ein" ;
VAL_ 1646 KL_WaPu 0 "Wasserpumpe_aus" 1 "Wasserpumpe_aktiv" ;
VAL_ 1646 KL_Geblaese_Status 0 "Geblaese_aus" 1 "Geblaesestufe_10" 2 "Geblaesestufe_20" 3 "Geblaesestufe_30" 4 "Geblaesestufe_40" 5 "Geblaesestufe_50" 6 "Geblaesestufe_60" 7 "Geblaesestufe_70" 8 "Geblaesestufe_80" 9 "Geblaesestufe_90" 10 "Geblaesestufe_100" 14 "Init" 15 "Fehler" ;
VAL_ 1646 KL_Restwaerme_aktiv 0 "inaktiv" 1 "aktiv" ;
VAL_ 1646 KL_Kompressorkupplung 0 "oeffnen" 1 "schliessen" ;
VAL_ 1646 KL_BCmE_Livetip_Freigabe 0 "Anzeige_Livetip_nicht_zulaessig" 1 "Anzeige_Livetip_zulaessig" ;
VAL_ 1646 KL_HYB_ASV_hinten_schliessen_Anf 0 "keine_Anforderung" 1 "Ventil_schliessen" ;
VAL_ 1646 KL_HYB_ASV_vorne_schliessen_Anf 0 "keine_Anforderung" 1 "Ventil_schliessen" ;
VAL_ 1646 KL_ErwVK_Zusatzrelais 0 "nicht_angefordert" 1 "angefordert" ;
VAL_ 1646 KL_Status_Beduftung 0 "inaktiv" 1 "aktiv" ;
VAL_ 1646 KL_Status_Ionisator_Front 0 "inaktiv" 1 "aktiv" ;
VAL_ 1646 KL_STH_Timer_Status 0 "TimerInaktiv" 1 "TimerAktiv" ;
VAL_ 1646 KL_ErwVK_Anf 0 "nicht_angefordert" 1 "angefordert" ;
VAL_ 1646 KL_Innen_Temp 253 "nicht_verbaut" 254 "nicht_verfuegbar" 255 "Fehler" ;
VAL_ 1646 KL_I_Geblaese_Fond 255 "Fehler" ;
VAL_ 1646 KL_Anf_AussenspiegelHzg 0 "nicht_angefordert" 1 "angefordert" ;
VAL_ 1646 KL_Heizkreisventilstellung 0 "Init" 1 "Ventilstellung_gem_Anforderung" 2 "Ventilstellung_abweichend_Anf" 3 "Fehler" ;
VAL_ 1646 KL_FSH_Automatikbetrieb 0 "aus" 1 "angefordert_durch_Regelung" ;
VAL_ 1646 KL_SIH_LEH_Verteilung_VL 0 "gleichmaessige_Verteilung" 1 "Sitz_Prio_Hoch" 2 "Sitz_Prio_Mittel" 3 "Sitz_Prio_Niedrig" 4 "Lehne_Prio_Niedrig" 5 "Lehne_Prio_Mittel" 6 "Lehne_Prio_Hoch" ;
VAL_ 1646 KL_SIH_LEL_Verteilung_VL 0 "gleichmaessige_Verteilung" 1 "Sitz_Prio_Hoch" 2 "Sitz_Prio_Mittel" 3 "Sitz_Prio_Niedrig" 4 "Lehne_Prio_Niedrig" 5 "Lehne_Prio_Mittel" 6 "Lehne_Prio_Hoch" ;
VAL_ 1646 KL_SIH_LEH_Verteilung_VR 0 "gleichmaessige_Verteilung" 1 "Sitz_Prio_Hoch" 2 "Sitz_Prio_Mittel" 3 "Sitz_Prio_Niedrig" 4 "Lehne_Prio_Niedrig" 5 "Lehne_Prio_Mittel" 6 "Lehne_Prio_Hoch" ;
VAL_ 1646 KL_SIH_LEL_Verteilung_VR 0 "gleichmaessige_Verteilung" 1 "Sitz_Prio_Hoch" 2 "Sitz_Prio_Mittel" 3 "Sitz_Prio_Niedrig" 4 "Lehne_Prio_Niedrig" 5 "Lehne_Prio_Mittel" 6 "Lehne_Prio_Hoch" ;
VAL_ 1663 KL_Mod_Display_li 0 "Solltemperatur" 1 "Luftverteilung" 2 "Sitzheizung" 3 "Sitzlueftung" 4 "Luftmenge" 9 "OBD" 10 "Display_off" ;
VAL_ 1663 KL_Mod_Display_re 0 "Solltemperatur" 1 "Luftverteilung" 2 "Sitzheizung" 3 "Sitzlueftung" 4 "Luftmenge" 9 "OBD" 10 "Display_off" ;
VAL_ 1663 KL_Fondbed_vorne_aktiv 0 "nicht_aktiv" 1 "Bedienung_von_vorne_ist_aktiv" ;
VAL_ 1663 KL_Fond_re_reduziert 1 "Leistungsreduzierung" ;
VAL_ 1663 KL_Fond_li_reduziert 1 "Leistungsreduzierung" ;
VAL_ 1663 KL_Absperrventil_Fond 0 "nicht_ansteuern" 1 "ansteuern" ;
VAL_ 1663 KL_SH_HL_Lastabschaltung 0 "keine_Einschraenkung" 1 "Taktung" 2 "Abschaltung" ;
VAL_ 1663 KL_SH_HR_Lastabschaltung 0 "keine_Einschraenkung" 1 "Taktung" 2 "Abschaltung" ;
VAL_ 1663 KL_Sollausblastemp_HL 1023 "Fehler" ;
VAL_ 1663 KL_Einheiten 0 "°C" 1 "°F" ;
VAL_ 1663 KL_Kindersicherung 0 "nicht_aktiv" 1 "aktiv" ;
VAL_ 1663 KL_Heizverbraucher_aus 0 "keine_Einschraenkung" 1 "Heizverbraucher_deaktivieren" ;
VAL_ 1663 KL_Heizverbraucher_Notaus 0 "keine_Einschraenkung" 1 "Heizverbraucher_sofort_deaktivieren" ;
VAL_ 1663 KL_Gebl_Verst_Abs_Modus 0 "Aus" 1 "Ein" ;
VAL_ 1663 KL_Sollausblastemp_HR 1023 "Fehler" ;
VAL_ 1663 KL_ICO2_Sensor_defekt 0 "Init" 1 "nicht_defekt" 2 "defekt" 3 "CO2_Warnung" ;
VAL_ 1663 KL_Umluft 254 "Init" 255 "Fehler" ;
